VERSION ""

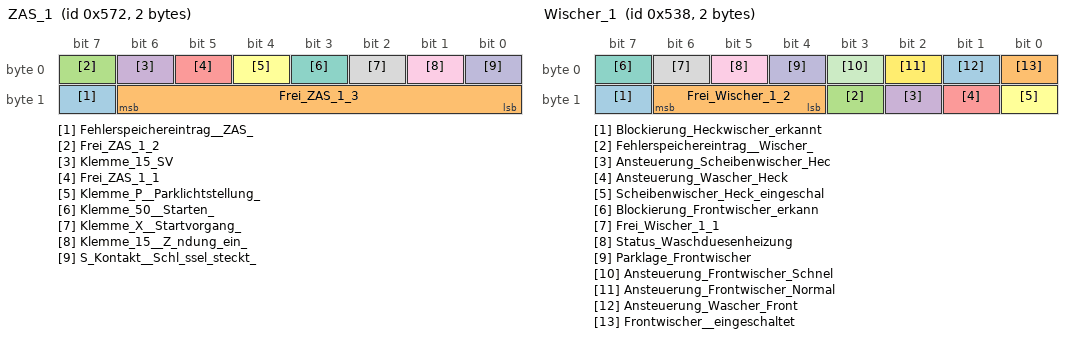
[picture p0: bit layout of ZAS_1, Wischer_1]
BO_ 1394 ZAS_1: 2 XXX
 SG_ Fehlerspeichereintrag__ZAS_ : 15|1@1+ (1,0) [0|0] "" XXX
 SG_ Frei_ZAS_1_3 : 8|7@1+ (1,0) [0|0] "" XXX
 SG_ Frei_ZAS_1_2 : 7|1@1+ (1,0) [0|0] "" XXX
 SG_ Klemme_15_SV : 6|1@1+ (1,0) [0|0] "" XXX
 SG_ Frei_ZAS_1_1 : 5|1@1+ (1,0) [0|0] "" XXX
 SG_ Klemme_P__Parklichtstellung_ : 4|1@1+ (1,0) [0|0] "" XXX
 SG_ Klemme_50__Starten_ : 3|1@1+ (1,0) [0|0] "" XXX
 SG_ Klemme_X__Startvorgang_ : 2|1@1+ (1,0) [0|0] "" XXX
 SG_ Klemme_15__Z_ndung_ein_ : 1|1@1+ (1,0) [0|0] "" XXX
 SG_ S_Kontakt__Schl_ssel_steckt_ : 0|1@1+ (1,0) [0|0] "" XXX

BO_ 1336 Wischer_1: 2 XXX
 SG_ Blockierung_Heckwischer_erkannt : 15|1@1+ (1,0) [0|0] "" XXX
 SG_ Frei_Wischer_1_2 : 12|3@1+ (1,0) [0|0] "" XXX
 SG_ Fehlerspeichereintrag__Wischer_ : 11|1@1+ (1,0) [0|0] "" XXX
 SG_ Ansteuerung_Scheibenwischer_Hec : 10|1@1+ (1,0) [0|0] "" XXX
 SG_ Ansteuerung_Wascher_Heck : 9|1@1+ (1,0) [0|0] "" XXX
 SG_ Scheibenwischer_Heck_eingeschal : 8|1@1+ (1,0) [0|0] "" XXX
 SG_ Blockierung_Frontwischer_erkann : 7|1@1+ (1,0) [0|0] "" XXX
 SG_ Frei_Wischer_1_1 : 6|1@1+ (1,0) [0|0] "" XXX
 SG_ Status_Waschduesenheizung : 5|1@1+ (1,0) [0|0] "" XXX
 SG_ Parklage_Frontwischer : 4|1@1+ (1,0) [0|0] "" XXX
 SG_ Ansteuerung_Frontwischer_Schnel : 3|1@1+ (1,0) [0|0] "" XXX
 SG_ Ansteuerung_Frontwischer_Normal : 2|1@1+ (1,0) [0|0] "" XXX
 SG_ Ansteuerung_Wascher_Front : 1|1@1+ (1,0) [0|0] "" XXX
 SG_ Frontwischer__eingeschaltet : 0|1@1+ (1,0) [0|0] "" XXX

BO_ 1464 WFS_1: 2 XXX
 SG_ WFS_Textbits : 8|8@1+ (1,0) [0|0] "" XXX
 SG_ Frei_WFS_1_1 : 1|7@1+ (1,0) [0|0] "" XXX
 SG_ WFS_LED : 0|1@1+ (1,0) [0|0] "" XXX

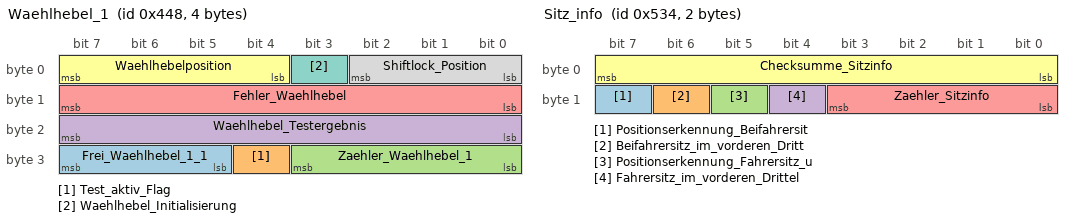
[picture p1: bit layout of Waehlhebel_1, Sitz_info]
BO_ 1096 Waehlhebel_1: 4 XXX
 SG_ Frei_Waehlhebel_1_1 : 29|3@1+ (1,0) [0|0] "" XXX
 SG_ Test_aktiv_Flag : 28|1@1+ (1,0) [0|0] "" XXX
 SG_ Zaehler_Waehlhebel_1 : 24|4@1+ (1,0) [0|15] "" XXX
 SG_ Waehlhebel_Testergebnis : 16|8@1+ (1,0) [0|255] "" XXX
 SG_ Fehler_Waehlhebel : 8|8@1+ (1,0) [0|0] "" XXX
 SG_ Waehlhebelposition : 4|4@1+ (1,0) [0|0] "" XXX
 SG_ Waehlhebel_Initialisierung : 3|1@1+ (1,0) [0|0] "" XXX
 SG_ Shiftlock_Position : 0|3@1+ (1,0) [0|0] "" XXX

BO_ 1496 Verbauliste_1: 8 XXX
 SG_ TV_Tuner : 63|1@1+ (1,0) [0|0] "" XXX
 SG_ DSP : 62|1@1+ (1,0) [0|0] "" XXX
 SG_ CD_Wechsler : 61|1@1+ (1,0) [0|0] "" XXX
 SG_ Spracheingabe : 60|1@1+ (1,0) [0|0] "" XXX
 SG_ Telematik : 59|1@1+ (1,0) [0|0] "" XXX
 SG_ Navigation : 58|1@1+ (1,0) [0|0] "" XXX
 SG_ Telefon : 57|1@1+ (1,0) [0|0] "" XXX
 SG_ Radio : 56|1@1+ (1,0) [0|0] "" XXX
 SG_ MMI_vorne : 55|1@1+ (1,0) [0|0] "" XXX
 SG_ MMI_hinten : 54|1@1+ (1,0) [0|0] "" XXX
 SG_ Frei_Verbauliste_1_11 : 53|1@1+ (1,0) [0|0] "" XXX
 SG_ Klimabedienteil_HL : 52|1@1+ (1,0) [0|0] "" XXX
 SG_ Frei_Verbauliste_1_10 : 50|2@1+ (1,0) [0|0] "" XXX
 SG_ Tankgeber : 49|1@1+ (1,0) [0|0] "" XXX
 SG_ Assistenzfahrlicht : 48|1@1+ (1,0) [0|0] "" XXX
 SG_ Memory_hinter_Fahrer : 47|1@1+ (1,0) [0|0] "" XXX
 SG_ Sitzmemory_hinten : 46|1@1+ (1,0) [0|0] "" XXX
 SG_ Sitzmemory_Beifahrer : 45|1@1+ (1,0) [0|0] "" XXX
 SG_ Anh_ngersteuergeraet : 44|1@1+ (1,0) [0|0] "" XXX
 SG_ Energiemanagement : 43|1@1+ (1,0) [0|0] "" XXX
 SG_ Wischermodul : 42|1@1+ (1,0) [0|0] "" XXX
 SG_ EZS___Kessy__Komfort_ : 41|1@1+ (1,0) [0|0] "" XXX
 SG_ Verdecksteuergeraet : 40|1@1+ (1,0) [0|0] "" XXX
 SG_ Standheizung : 39|1@1+ (1,0) [0|0] "" XXX
 SG_ Frei_Verbauliste_1_9 : 38|1@1+ (1,0) [0|0] "" XXX
 SG_ Einparkhilfe : 37|1@1+ (1,0) [0|0] "" XXX
 SG_ Klimasteuergeraet_Komfort : 36|1@1+ (1,0) [0|0] "" XXX
 SG_ Gateway : 35|1@1+ (1,0) [0|0] "" XXX
 SG_ Lenksaeulenmodul : 34|1@1+ (1,0) [0|0] "" XXX
 SG_ Reifendruck : 33|1@1+ (1,0) [0|0] "" XXX
 SG_ Kombiinstrument_Komfort : 32|1@1+ (1,0) [0|0] "" XXX
 SG_ Dachmodul : 31|1@1+ (1,0) [0|0] "" XXX
 SG_ Memory : 30|1@1+ (1,0) [0|0] "" XXX
 SG_ TSG_HR : 29|1@1+ (1,0) [0|0] "" XXX
 SG_ TSG_HL : 28|1@1+ (1,0) [0|0] "" XXX
 SG_ TSG_BT : 27|1@1+ (1,0) [0|0] "" XXX
 SG_ TSG_FT : 26|1@1+ (1,0) [0|0] "" XXX
 SG_ ZKE : 25|1@1+ (1,0) [0|0] "" XXX
 SG_ BSG_Komfort : 24|1@1+ (1,0) [0|0] "" XXX
 SG_ Frei_Verbauliste_1_8 : 19|5@1+ (1,0) [0|0] "" XXX
 SG_ Stabi_Entkopplung : 18|1@1+ (1,0) [0|0] "" XXX
 SG_ Waehlhebel : 17|1@1+ (1,0) [0|0] "" XXX
 SG_ Batteriemanager : 16|1@1+ (1,0) [0|0] "" XXX
 SG_ Daempfer_SG : 15|1@1+ (1,0) [0|0] "" XXX
 SG_ Niveauregulierung : 14|1@1+ (1,0) [0|0] "" XXX
 SG_ EZS___Kessy__Antrieb_ : 13|1@1+ (1,0) [0|0] "" XXX
 SG_ Bremsbooster : 12|1@1+ (1,0) [0|0] "" XXX
 SG_ Lenkhilfe : 11|1@1+ (1,0) [0|0] "" XXX
 SG_ Kombi_Antrieb : 10|1@1+ (1,0) [0|0] "" XXX
 SG_ Einspritzpumpe : 9|1@1+ (1,0) [0|0] "" XXX
 SG_ Lenkwinkel : 8|1@1+ (1,0) [0|0] "" XXX
 SG_ Allrad : 7|1@1+ (1,0) [0|0] "" XXX
 SG_ BSG_Antrieb : 6|1@1+ (1,0) [0|0] "" XXX
 SG_ ADR : 5|1@1+ (1,0) [0|0] "" XXX
 SG_ Airbag : 4|1@1+ (1,0) [0|0] "" XXX
 SG_ Climatronic_Antrieb : 3|1@1+ (1,0) [0|0] "" XXX
 SG_ ABS : 2|1@1+ (1,0) [0|0] "" XXX
 SG_ Getriebesteuergeraet : 1|1@1+ (1,0) [0|0] "" XXX
 SG_ Motorsteuergeraet : 0|1@1+ (1,0) [0|0] "" XXX

BO_ 1488 Systeminfo_1: 6 XXX
 SG_ CAN_Stand_4_1_Antrieb_Daten_Hau : 44|4@1+ (1,0) [0|15] "" XXX
 SG_ CAN_Stand_4_1_Antrieb_Daten_Neb : 40|4@1+ (1,0) [0|15] "" XXX
 SG_ CAN_Stand_4_1_Komfort_Daten_Hau : 36|4@1+ (1,0) [0|15] "" XXX
 SG_ CAN_Stand_4_1_Komfort_Daten_Neb : 32|4@1+ (1,0) [0|15] "" XXX
 SG_ Frei_Systeminfo_1_6 : 30|1@1+ (1,0) [0|0] "" XXX
 SG_ Viertuerer : 29|1@1+ (1,0) [0|0] "" XXX
 SG_ Rechtslenker : 28|1@1+ (1,0) [0|0] "" XXX
 SG_ Fahrzeug_Index : 24|4@1+ (1,0) [0|0] "" XXX
 SG_ Fahrzeug_Generation : 20|4@1+ (1,0) [0|15] "" XXX
 SG_ Fahrzeug_Derivat : 16|4@1+ (1,0) [0|15] "" XXX
 SG_ Fahrzeug_Marke_2 : 12|4@1+ (1,0) [0|15] "" XXX
 SG_ Fahrzeug_Klasse : 8|4@1+ (1,0) [0|15] "" XXX
 SG_ Verbauinformation_gueltig : 7|1@1+ (1,0) [0|0] "" XXX
 SG_ CAN_Infotainment_verbaut : 6|1@1+ (1,0) [0|0] "" XXX
 SG_ CAN_Infotainment_in_Diagnose : 5|1@1+ (1,0) [0|0] "" XXX
 SG_ Sleep_CAN_Infotainment : 4|1@1+ (1,0) [0|0] "" XXX
 SG_ CAN_Komfort_in_Diagnose : 3|1@1+ (1,0) [0|0] "" XXX
 SG_ Sleep_CAN_Komfort : 2|1@1+ (1,0) [0|0] "" XXX
 SG_ CAN_Antrieb_in_Diagnose : 1|1@1+ (1,0) [0|0] "" XXX
 SG_ CAN_Extern_zugeschaltet : 0|1@1+ (1,0) [0|0] "" XXX

BO_ 268 Slave_1: 8 XXX
 SG_ Delta_reduziertes_Sollmoment : 48|1@1+ (1,0) [0|0] "" XXX
 SG_ Delta_Drosselklappenwinkel : 32|16@1+ (1,0) [0|0] "" XXX
 SG_ Frei_Slave_1_1 : 25|7@1+ (1,0) [0|0] "" XXX
 SG_ Delta_Zuendwinkelausgabe : 24|1@1+ (1,0) [0|0] "" XXX
 SG_ Ubat_Freigabe_DVE__Slave_ : 23|1@1+ (1,0) [0|0] "" XXX
 SG_ Drosselklappe_Sollwertbegrenzun : 22|1@1+ (1,0) [0|0] "" XXX
 SG_ Einspritzverbot_lernen__Slave_ : 21|1@1+ (1,0) [0|0] "" XXX
 SG_ Master_erkannt__Slave_ : 20|1@1+ (1,0) [0|0] "" XXX
 SG_ Fehler_Momentenausgabe : 19|1@1+ (1,0) [0|0] "" XXX
 SG_ Fehler_Getriebe_Moment : 18|1@1+ (1,0) [0|0] "" XXX
 SG_ Fehler_Bremsenbotschaft : 17|1@1+ (1,0) [0|0] "" XXX
 SG_ Indiziertes_Istmoment__Slave_ : 0|16@1+ (0.0015259,0) [0|99.998] "%" XXX
 SG_ Timeout_Bremsenbotschaft : 0|1@1+ (1,0) [0|0] "" XXX

BO_ 1332 Sitz_info: 2 XXX
 SG_ Positionserkennung_Beifahrersit : 15|1@1+ (1,0) [0|0] "" XXX
 SG_ Beifahrersitz_im_vorderen_Dritt : 14|1@1+ (1,0) [0|0] "" XXX
 SG_ Positionserkennung_Fahrersitz_u : 13|1@1+ (1,0) [0|0] "" XXX
 SG_ Fahrersitz_im_vorderen_Drittel : 12|1@1+ (1,0) [0|0] "" XXX
 SG_ Zaehler_Sitzinfo : 8|4@1+ (1,0) [0|15] "" XXX
 SG_ Checksumme_Sitzinfo : 0|8@1+ (1,0) [0|0] "" XXX

BO_ 1810 PSG_3: 2 XXX
 SG_ Selbsttestergebnis : 0|16@1+ (1,0) [0|0] "" XXX

BO_ 1298 PSG_2: 8 XXX
 SG_ RAM_Inhalt_4 : 48|16@1+ (1,0) [0|0] "" XXX
 SG_ RAM_Inhalt_3 : 32|16@1+ (1,0) [0|0] "" XXX
 SG_ RAM_Inhalt_2 : 16|16@1+ (1,0) [0|0] "" XXX
 SG_ RAM_Inhalt_1 : 0|16@1+ (1,0) [0|0] "" XXX

BO_ 274 PSG_1: 8 XXX
 SG_ Pumpentemperatur__2_1_ : 48|16@1+ (0.0625,0) [0|4096] "K" XXX
 SG_ Pumpentemperatur__3_2_2_ : 44|12@1+ (1,0) [0|0] "" XXX
 SG_ Zylinderzaehler__3_2_2_ : 43|3@1+ (1,0) [1|8] "Zaehler" XXX
 SG_ Ansteuerdauer__3_2_2_ : 32|11@1+ (0.0469,0) [0|96] "NW" XXX
 SG_ Nockenwellendrehzahl__3_2_2_ : 20|12@1+ (4,0) [0|16380] "upm" XXX
 SG_ Pumpen_Statuswort__3_2_2_ : 0|20@1+ (1,0) [0|0] "" XXX

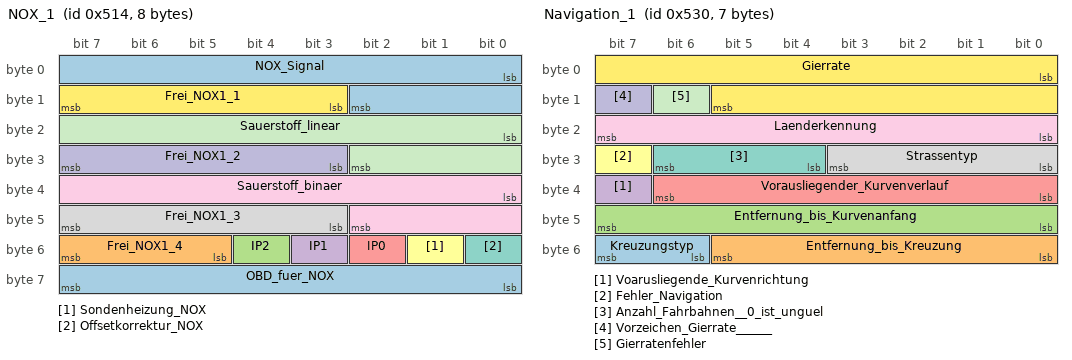
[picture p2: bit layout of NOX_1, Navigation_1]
BO_ 1300 NOX_1: 8 XXX
 SG_ OBD_fuer_NOX : 56|8@1+ (1,0) [0|0] "" XXX
 SG_ Frei_NOX1_4 : 53|3@1+ (1,0) [0|0] "" XXX
 SG_ IP2 : 52|1@1+ (1,0) [0|0] "" XXX
 SG_ IP1 : 51|1@1+ (1,0) [0|0] "" XXX
 SG_ IP0 : 50|1@1+ (1,0) [0|0] "" XXX
 SG_ Sondenheizung_NOX : 49|1@1+ (1,0) [0|0] "" XXX
 SG_ Offsetkorrektur_NOX : 48|1@1+ (1,0) [0|0] "" XXX
 SG_ Frei_NOX1_3 : 43|5@1+ (1,0) [0|0] "" XXX
 SG_ Sauerstoff_binaer : 32|11@1+ (1,-200) [-200|1847] "mV" XXX
 SG_ Frei_NOX1_2 : 27|5@1+ (1,0) [0|0] "" XXX
 SG_ Sauerstoff_linear : 16|11@1+ (1,0) [0|2047] "1000/Lambd" XXX
 SG_ Frei_NOX1_1 : 11|5@1+ (1,0) [0|0] "" XXX
 SG_ NOX_Signal : 0|11@1+ (1,0) [0|2047] "ppm" XXX

BO_ 1424 Niveau_1: 6 XXX
 SG_ Beladungszustand : 40|8@1+ (1,0) [0|253] "Zuladung" XXX
 SG_ Fehlerspeichereintrag__Niveau_1 : 39|1@1+ (1,0) [0|0] "" XXX
 SG_ Systemstatus__Niveau_1_ : 38|1@1+ (1,0) [0|0] "" XXX
 SG_ Reserve_Fahrzeugart : 37|1@1+ (1,0) [0|0] "" XXX
 SG_ Fahrzeugart_Niveau : 36|1@1+ (1,0) [0|0] "" XXX
 SG_ Textbits__Niveau_1_ : 32|4@1+ (1,0) [0|0] "" XXX
 SG_ Verstellung_HL : 31|1@1+ (1,0) [0|0] "" XXX
 SG_ Verstellung_HR : 30|1@1+ (1,0) [0|0] "" XXX
 SG_ Verstellung_VL : 29|1@1+ (1,0) [0|0] "" XXX
 SG_ Verstellung_VR : 28|1@1+ (1,0) [0|0] "" XXX
 SG_ Absenkung_Fahrzeug : 27|1@1+ (1,0) [0|0] "" XXX
 SG_ Anhebung_Fahrzeug : 26|1@1+ (1,0) [0|0] "" XXX
 SG_ Verstellung_aktiv : 25|1@1+ (1,0) [0|0] "" XXX
 SG_ Kompressorlauf_in_Kuerze : 24|1@1+ (1,0) [0|0] "" XXX
 SG_ Frei_Niveau_1_5 : 23|1@1+ (1,0) [0|0] "" XXX
 SG_ Taster_Niveau : 22|1@1+ (1,0) [0|0] "" XXX
 SG_ Parkniveau : 21|1@1+ (1,0) [0|0] "" XXX
 SG_ Zwischenniveau : 20|1@1+ (1,0) [0|0] "" XXX
 SG_ Niveaustati : 16|4@1+ (1,0) [0|0] "" XXX
 SG_ MSG_Einschraenkung : 15|1@1+ (1,0) [0|0] "" XXX
 SG_ ESP_Beeinflussung : 14|1@1+ (1,0) [0|0] "" XXX
 SG_ Warnlampe_Niveau_1 : 13|1@1+ (1,0) [0|0] "" XXX
 SG_ Frei_Niveau_1_1 : 12|1@1+ (1,0) [0|0] "" XXX
 SG_ Zaehler_Niveau_1 : 8|4@1+ (1,0) [0|15] "Zaehler" XXX
 SG_ Checksumme_Niveau_1 : 0|8@1+ (1,0) [0|0] "" XXX

BO_ 1328 Navigation_1: 7 XXX
 SG_ Kreuzungstyp : 54|2@1+ (1,0) [0|3] "" XXX
 SG_ Entfernung_bis_Kreuzung : 48|6@1+ (5,0) [0|315] "m" XXX
 SG_ Entfernung_bis_Kurvenanfang : 40|8@1+ (1,0) [0|255] "m" XXX
 SG_ Voarusliegende_Kurvenrichtung : 39|1@1+ (1,0) [0|0] "" XXX
 SG_ Vorausliegender_Kurvenverlauf : 32|7@1+ (50,0) [0|6350] "m" XXX
 SG_ Fehler_Navigation : 31|1@1+ (1,0) [0|0] "" XXX
 SG_ Anzahl_Fahrbahnen__0_ist_unguel : 28|3@1+ (1,0) [1|7] "" XXX
 SG_ Strassentyp : 24|4@1+ (1,0) [0|15] "" XXX
 SG_ Laenderkennung : 16|8@1+ (1,0) [0|0] "" XXX
 SG_ Vorzeichen_Gierrate______ : 15|1@1+ (1,0) [0|0] "" XXX
 SG_ Gierratenfehler : 14|1@1+ (1,0) [0|0] "" XXX
 SG_ Gierrate : 0|14@1+ (0.01,0) [0|100] "deg/sek" XXX

BO_ 1792 MSG_3: 3 XXX
 SG_ MSG_Konfiguration : 16|8@1+ (1,0) [0|0] "" XXX
 SG_ Lage_des_OT_Impuls : 0|16@1+ (0.01172,-384) [-384|384] "KW" XXX

BO_ 1280 MSG_2: 8 XXX
 SG_ RAM_Adresse_4 : 48|16@1+ (1,0) [0|0] "" XXX
 SG_ RAM_Adresse_3 : 32|16@1+ (1,0) [0|0] "" XXX
 SG_ RAM_Adresse_2 : 16|16@1+ (1,0) [0|0] "" XXX
 SG_ Ram_Adresse_1 : 0|16@1+ (1,0) [0|0] "" XXX

BO_ 256 MSG_1: 8 XXX
 SG_ Kurbelwellendrehzahl__3_2_2_ : 56|8@1+ (1,0) [0|0] "" XXX
 SG_ Soll_Foerderbeginn_KW__3_2_2_ : 40|16@1+ (0.01172,-384) [-384|384] "KW" XXX
 SG_ Soll_Foerderbeginn_NW__3_2_2_ : 28|12@1+ (0.01172,0) [0|768] "degNW" XXX
 SG_ Soll_Voreinspritzung : 16|12@1+ (1,0) [0|0] "" XXX
 SG_ Soll_Einspritzmenge : 0|16@1+ (0.03125,0) [0|2047] "mg/H" XXX

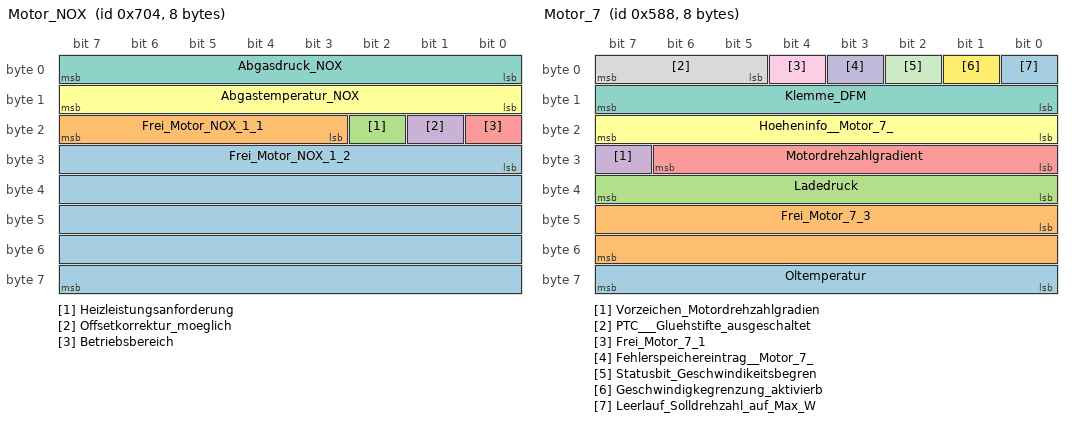
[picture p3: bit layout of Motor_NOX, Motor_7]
BO_ 1796 Motor_NOX: 8 XXX
 SG_ Frei_Motor_NOX_1_2 : 24|40@1+ (1,0) [0|0] "" XXX
 SG_ Frei_Motor_NOX_1_1 : 19|5@1+ (1,0) [0|0] "" XXX
 SG_ Heizleistungsanforderung : 18|1@1+ (1,0) [0|0] "" XXX
 SG_ Offsetkorrektur_moeglich : 17|1@1+ (1,0) [0|0] "" XXX
 SG_ Betriebsbereich : 16|1@1+ (1,0) [0|0] "" XXX
 SG_ Abgastemperatur_NOX : 8|8@1+ (5,-40) [-40|1230] "C" XXX
 SG_ Abgasdruck_NOX : 0|8@1+ (5,600) [600|1870] "mbar" XXX

BO_ 900 Motor_Momente: 8 XXX
 SG_ Momentenangaben_ungenau__Moment : 35|2@1+ (1,0) [0|0] "" XXX

BO_ 1408 Motor_Flexia: 8 XXX
 SG_ Ansaugsystem m0 : 63|1@1+ (1,0) [0|0] "" XXX
 SG_ Hubraum m0 : 56|7@1+ (0.1,0) [0|12.7] "l" XXX
 SG_ Steigung_der_Befuellungskennlin m1 : 56|8@1+ (0.001,0) [0|0.255] "l/mm" XXX
 SG_ Anzahl_Zylinder m0 : 52|4@1+ (1,0) [0|15] "Vent./Zyl." XXX
 SG_ Bewertungsfaktor_Russindex_Turb m1 : 50|6@1+ (0.1,0) [0|6.3] "" XXX
 SG_ Anzahl_Ventile m0 : 49|3@1+ (1,0) [0|7] "Vent./Zyl." XXX
 SG_ Bewertungsfaktor_Verschleissind m1 : 44|6@1+ (0.1,0) [0|6.3] "" XXX
 SG_ Hersteller_Code m1 : 40|4@1+ (1,0) [0|15] "" XXX
 SG_ Motorleistung m0 : 40|9@1+ (1,0) [0|512] "KW" XXX
 SG_ Max_Drehmoment m0 : 32|8@1+ (10,0) [0|2550] "Nm" XXX
 SG_ Normierter_Verbrauch m1 : 32|8@1+ (10,0) [0|2550] "l/Zyl." XXX
 SG_ Oelniveauschwelle m1 : 24|8@1+ (0.25,0) [0|63.75] "cm" XXX
 SG_ Drehzahl_MaxNorm m0 : 24|8@1+ (100,0) [0|25500] "U/min" XXX
 SG_ Verschleissindex : 16|8@1+ (1,0) [0|254] "" XXX
 SG_ Russindex : 8|8@1+ (1,0) [0|254] "" XXX
 SG_ Verbrennungsart : 7|1@1+ (1,0) [0|0] "" XXX
 SG_ Frei_Motor_Flexia_1 : 6|1@1+ (1,0) [0|0] "" XXX
 SG_ Warm_Up_Cycle : 5|1@1+ (1,0) [0|0] "" XXX
 SG_ Driving_Cycle : 4|1@1+ (1,0) [0|0] "" XXX
 SG_ Zaehler_Motor_Flexia : 1|3@1+ (1,0) [0|15] "" XXX
 SG_ Multiplex_Schalter_Motor_Flexia M : 0|1@1+ (1,0) [0|0] "" XXX

BO_ 1416 Motor_7: 8 XXX
 SG_ Oltemperatur : 56|8@1+ (1,0) [0|0] "" XXX
 SG_ Frei_Motor_7_3 : 40|16@1+ (1,0) [0|0] "" XXX
 SG_ Ladedruck : 32|8@1+ (0.01,0) [0|2.54] "bar" XXX
 SG_ Vorzeichen_Motordrehzahlgradien : 31|1@1+ (1,0) [0|0] "" XXX
 SG_ Motordrehzahlgradient : 24|7@1+ (1,0) [0|126] "U/min" XXX
 SG_ Hoeheninfo__Motor_7_ : 16|8@1+ (0.00787,0) [0|2] "" XXX
 SG_ Klemme_DFM : 8|8@1+ (0.4,0) [0|101.6] "%" XXX
 SG_ PTC___Gluehstifte_ausgeschaltet : 5|3@1+ (1,0) [0|0] "" XXX
 SG_ Frei_Motor_7_1 : 4|1@1+ (1,0) [0|0] "" XXX
 SG_ Fehlerspeichereintrag__Motor_7_ : 3|1@1+ (1,0) [0|0] "" XXX
 SG_ Statusbit_Geschwindikeitsbegren : 2|1@1+ (1,0) [0|0] "" XXX
 SG_ Geschwindigkegrenzung_aktivierb : 1|1@1+ (1,0) [0|0] "" XXX
 SG_ Leerlauf_Solldrehzahl_auf_Max_W : 0|1@1+ (1,0) [0|0] "" XXX

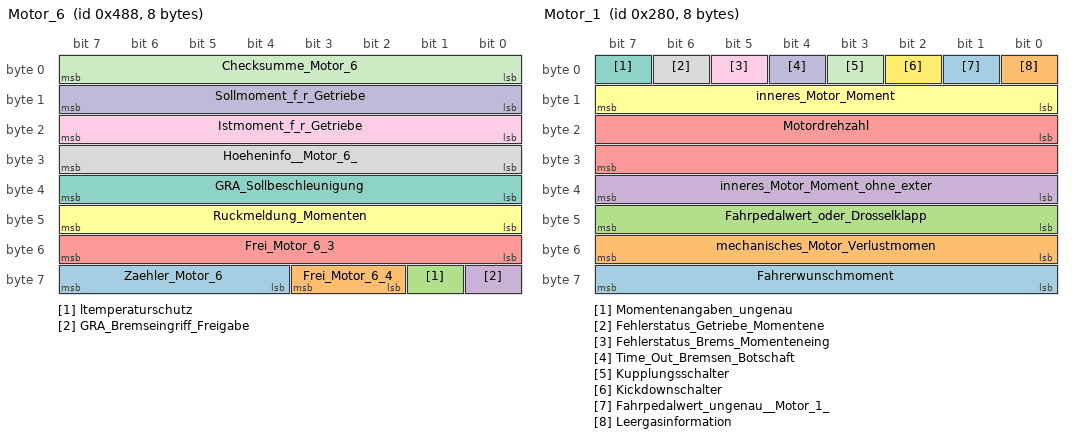
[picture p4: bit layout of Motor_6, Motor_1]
BO_ 1160 Motor_6: 8 XXX
 SG_ Zaehler_Motor_6 : 60|4@1+ (1,0) [0|15] "" XXX
 SG_ Frei_Motor_6_4 : 58|2@1+ (1,0) [0|0] "" XXX
 SG_ ltemperaturschutz : 57|1@1+ (1,0) [0|0] "" XXX
 SG_ GRA_Bremseingriff_Freigabe : 56|1@1+ (1,0) [0|0] "" XXX
 SG_ Frei_Motor_6_3 : 48|8@1+ (1,0) [0|0] "" XXX
 SG_ Ruckmeldung_Momenten : 40|8@1+ (0.39,0) [0|100] "" XXX
 SG_ GRA_Sollbeschleunigung : 32|8@1+ (0.024,-3.984) [-3.984|2.112] "m/s2" XXX
 SG_ Hoeheninfo__Motor_6_ : 24|8@1+ (0.00787,0) [0|2] "" XXX
 SG_ Istmoment_f_r_Getriebe : 16|8@1+ (0.39,0) [0|99] "MDI" XXX
 SG_ Sollmoment_f_r_Getriebe : 8|8@1+ (0.39,0) [0|99] "MDI" XXX
 SG_ Checksumme_Motor_6 : 0|8@1+ (1,0) [0|0] "" XXX

BO_ 1152 Motor_5: 8 XXX
 SG_ CHECKSUM : 56|8@1+ (1,0) [0|0] "" XXX
 SG_ Motortext_Bits__4_1_ : 52|4@1+ (1,0) [0|0] "" XXX
 SG_ Doppelte_Momente : 51|1@1+ (1,0) [0|0] "" XXX
 SG_ GRA_Hauptschalter : 50|1@1+ (1,0) [0|0] "" XXX
 SG_ Anlasser_Ausspuren : 49|1@1+ (1,0) [0|0] "" XXX
 SG_ Anlasser_Freigabe : 48|1@1+ (1,0) [0|0] "" XXX
 SG_ Klimadrucksignal__Motor_5_ : 40|8@1+ (0.2,0) [0|50.8] "bar" XXX
 SG_ K_hlerluefteransteuerung : 32|8@1+ (0.4,0) [0|101.6] "%" XXX
 SG_ Verbrauch_Ueberlauf : 31|1@1+ (1,0) [0|0] "" XXX
 SG_ Kraftstoffverbrauchssignal : 16|15@1+ (1,0) [0|32767] "ul" XXX
 SG_ Klimakompressor_Leistungsreduzi : 15|1@1+ (1,0) [0|0] "" XXX
 SG_ Kennfeldkuehlung : 14|1@1+ (1,0) [0|0] "" XXX
 SG_ Klimakompressor_aus__Motor_5_ : 13|1@1+ (1,0) [0|0] "" XXX
 SG_ CAT_Warnung : 12|1@1+ (1,0) [0|0] "" XXX
 SG_ OBD_2_Lampe : 11|1@1+ (1,0) [0|0] "" XXX
 SG_ E_Gas_Lampe : 10|1@1+ (1,0) [0|0] "" XXX
 SG_ Vorgluehlampe__Motor_5_ : 9|1@1+ (1,0) [0|0] "" XXX
 SG_ Ladekontroll_Lampe : 8|1@1+ (1,0) [0|0] "" XXX
 SG_ Multiplex_Code M : 6|2@1+ (1,0) [0|0] "" XXX
 SG_ Multiplex_Info_norm__Verbrauch m3 : 0|6@1+ (20,0) [0|1260] "l/Zyl" XXX
 SG_ Multiplex_Info_Motortyp m2 : 0|6@1+ (1,0) [0|0] "" XXX
 SG_ Multiplex_Info_Drehzahl_MD_Max m1 : 0|6@1+ (100,0) [0|6300] "U/min" XXX
 SG_ Multiplex_Info_Max_Drehmoment m0 : 0|6@1+ (10,0) [0|630] "Nm" XXX

BO_ 896 Motor_3: 8 XXX
 SG_ Drosselklappenpoti : 56|8@1+ (0.4,0) [0|101.6] "%" XXX
 SG_ Motor_Wunschdrehzahl : 48|8@1+ (25,0) [0|6350] "U/min" XXX
 SG_ Motordrehzahlbeeinflussung : 40|8@1+ (0.392,0) [0|100] "%" XXX
 SG_ Kein_Start_Stop : 39|1@1+ (1,0) [0|0] "" XXX
 SG_ Kein_E_Gas : 38|1@1+ (1,0) [0|0] "" XXX
 SG_ Reserviert_Motor_3_1 : 37|1@1+ (1,0) [0|0] "" XXX
 SG_ Vorzeichen_Rad_Wunschmoment : 36|1@1+ (1,0) [0|0] "" XXX
 SG_ Rad_Wunschmoment : 24|12@1+ (0.39,0) [0|1597] "MDI" XXX
 SG_ Fahrpedal_Rohsignal : 16|8@1+ (0.4,0) [0|101.6] "%" XXX
 SG_ Ansauglufttemperatur : 8|8@1+ (0.75,-48) [-48|142.5] "" XXX
 SG_ Fehlerstatus_Ansauglufttemperat : 7|1@1+ (1,0) [0|0] "" XXX
 SG_ Motorsteuerger_t_gesperrt : 6|1@1+ (1,0) [0|0] "" XXX
 SG_ Drosselklappenwinkel_ungenau : 5|1@1+ (1,0) [0|0] "" XXX
 SG_ Fahrpedalwert_ungenau__Motor_3_ : 4|1@1+ (1,0) [0|0] "" XXX
 SG_ Frei_Motor_3_1 : 3|1@1+ (1,0) [0|0] "" XXX
 SG_ Motor_Wunschdrehzahl_Priorit_t : 2|1@1+ (1,0) [0|0] "" XXX
 SG_ Uebertemperaturschutz__Motor_3_ : 1|1@1+ (1,0) [0|0] "" XXX
 SG_ Vorgluehmeldung : 0|1@1+ (1,0) [0|0] "" XXX

BO_ 648 Motor_2: 8 XXX
 SG_ Minimales_Motormoment_bei_Zuend : 56|8@1+ (0.39,0) [0|99] "MDI" XXX
 SG_ Begrenzungsmoment : 48|8@1+ (0.39,0) [0|99] "MDI" XXX
 SG_ Leerlaufsolldrehzahl__Motor_2_ : 40|8@1+ (10,0) [0|2540] "U/min" XXX
 SG_ Soll_Geschwindigkeit_bei_GRA_Be : 32|8@1+ (1.28,0) [0|325] "km/h" XXX
 SG_ Fahrzeuggeschwindigkeit : 24|8@1+ (1.28,0) [0|325] "km/h" XXX
 SG_ GRA_Status : 22|2@1+ (1,0) [0|0] "" XXX
 SG_ OBD_2_freeze_frame : 21|1@1+ (1,0) [0|0] "" XXX
 SG_ Status_Normalbetrieb : 20|1@1+ (1,0) [0|0] "" XXX
 SG_ Ansteuerung_Klima__4_1_ : 19|1@1+ (1,0) [0|0] "" XXX
 SG_ Fehlerstatus_Kuhlmitteltempera : 18|1@1+ (1,0) [0|0] "" XXX
 SG_ Bremstestschalter : 17|1@1+ (1,0) [0|0] "" XXX
 SG_ Bremslichtschalter : 16|1@1+ (1,0) [0|0] "" XXX
 SG_ Kuehlmitteltemperatur__Motor_2_ : 8|8@1+ (0.75,-48) [-48|142.5] "" XXX
 SG_ Multiplex_Code_Motor_2 M : 6|2@1+ (1,0) [0|0] "" XXX
 SG_ Multiplex_Info_Motorcode__4_x_ m1 : 0|6@1+ (1,0) [0|0] "" XXX
 SG_ Multiplex_Info_Getriebecode m2 : 0|6@1+ (1,0) [0|0] "" XXX
 SG_ Multiplex_Info_Max_Moment__Norm m3 : 0|6@1+ (10,0) [0|630] "Nm" XXX
 SG_ Multiplex_Info_CAN_Stand m0 : 0|6@1+ (1,0) [0|0] "" XXX

BO_ 640 Motor_1: 8 XXX
 SG_ Fahrerwunschmoment : 56|8@1+ (0.39,0) [0|99] "MDI" XXX
 SG_ mechanisches_Motor_Verlustmomen : 48|8@1+ (0.39,0) [0|99] "MDI" XXX
 SG_ Fahrpedalwert_oder_Drosselklapp : 40|8@1+ (0.4,0) [0|101.6] "%" XXX
 SG_ inneres_Motor_Moment_ohne_exter : 32|8@1+ (0.39,0) [0|99] "MDI" XXX
 SG_ Motordrehzahl : 16|16@1+ (0.25,0) [0|16256] "U/min" XXX
 SG_ inneres_Motor_Moment : 8|8@1+ (0.39,0) [0|99] "MDI" XXX
 SG_ Momentenangaben_ungenau : 7|1@1+ (1,0) [0|0] "" XXX
 SG_ Fehlerstatus_Getriebe_Momentene : 6|1@1+ (1,0) [0|0] "" XXX
 SG_ Fehlerstatus_Brems_Momenteneing : 5|1@1+ (1,0) [0|0] "" XXX
 SG_ Time_Out_Bremsen_Botschaft : 4|1@1+ (1,0) [0|0] "" XXX
 SG_ Kupplungsschalter : 3|1@1+ (1,0) [0|0] "" XXX
 SG_ Kickdownschalter : 2|1@1+ (1,0) [0|0] "" XXX
 SG_ Fahrpedalwert_ungenau__Motor_1_ M : 1|1@1+ (1,0) [0|0] "" XXX
 SG_ Leergasinformation : 0|1@1+ (1,0) [0|0] "" XXX

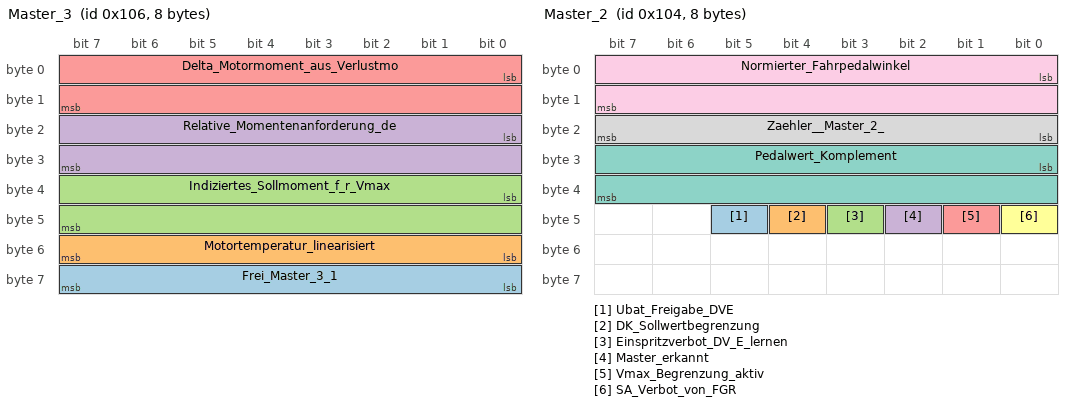
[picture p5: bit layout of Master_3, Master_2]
BO_ 262 Master_3: 8 XXX
 SG_ Frei_Master_3_1 : 56|8@1+ (1,0) [0|0] "" XXX
 SG_ Motortemperatur_linearisiert : 48|8@1+ (0.75,-48) [-48|143.25] "" XXX
 SG_ Indiziertes_Sollmoment_f_r_Vmax : 32|16@1+ (0.0015259,0) [0|100] "%" XXX
 SG_ Relative_Momentenanforderung_de : 16|16@1+ (0.003052,0) [0|200] "%" XXX
 SG_ Delta_Motormoment_aus_Verlustmo : 0|16@1+ (0.003052,-100) [-100|100] "%" XXX

BO_ 260 Master_2: 8 XXX
 SG_ Ubat_Freigabe_DVE : 45|1@1+ (1,0) [0|0] "" XXX
 SG_ DK_Sollwertbegrenzung : 44|1@1+ (1,0) [0|0] "" XXX
 SG_ Einspritzverbot_DV_E_lernen : 43|1@1+ (1,0) [0|0] "" XXX
 SG_ Master_erkannt : 42|1@1+ (1,0) [0|0] "" XXX
 SG_ Vmax_Begrenzung_aktiv : 41|1@1+ (1,0) [0|0] "" XXX
 SG_ SA_Verbot_von_FGR : 40|1@1+ (1,0) [0|0] "" XXX
 SG_ Pedalwert_Komplement : 24|16@1+ (1,0) [0|0] "" XXX
 SG_ Zaehler__Master_2_ : 16|8@1+ (1,0) [0|255] "" XXX
 SG_ Normierter_Fahrpedalwinkel : 0|16@1+ (0.001526,0) [0|100] "%" XXX

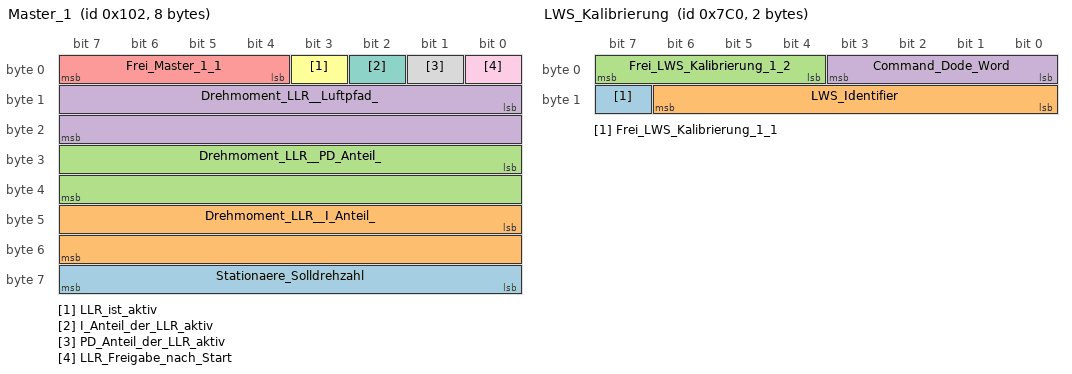
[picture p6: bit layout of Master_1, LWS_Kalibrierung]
BO_ 258 Master_1: 8 XXX
 SG_ Stationaere_Solldrehzahl : 56|8@1+ (10,0) [0|2550] "Umin" XXX
 SG_ Drehmoment_LLR__I_Anteil_ : 40|16@1+ (0.003052,-100) [-100|100] "%" XXX
 SG_ Drehmoment_LLR__PD_Anteil_ : 24|16@1+ (0.003052,-100) [-100|100] "%" XXX
 SG_ Drehmoment_LLR__Luftpfad_ : 8|16@1+ (0.003052,-100) [-100|100] "%" XXX
 SG_ Frei_Master_1_1 : 4|4@1+ (1,0) [0|0] "" XXX
 SG_ LLR_ist_aktiv : 3|1@1+ (1,0) [0|0] "" XXX
 SG_ I_Anteil_der_LLR_aktiv : 2|1@1+ (1,0) [0|0] "" XXX
 SG_ PD_Anteil_der_LLR_aktiv : 1|1@1+ (1,0) [0|0] "" XXX
 SG_ LLR_Freigabe_nach_Start : 0|1@1+ (1,0) [0|0] "" XXX

BO_ 1984 LWS_Kalibrierung: 2 XXX
 SG_ Frei_LWS_Kalibrierung_1_1 : 15|1@1+ (1,0) [0|0] "" XXX
 SG_ LWS_Identifier : 8|7@1+ (1,0) [0|0] "" XXX
 SG_ Frei_LWS_Kalibrierung_1_2 : 4|4@1+ (1,0) [0|0] "" XXX
 SG_ Command_Dode_Word : 0|4@1+ (1,0) [0|0] "" XXX

BO_ 1986 Lenkwinkel_Init: 4 XXX
 SG_ Kodierbytes : 8|24@1+ (1,0) [0|0] "" XXX
 SG_ Identiifier_f_r_LWS_Init : 0|8@1+ (1,0) [0|0] "" XXX

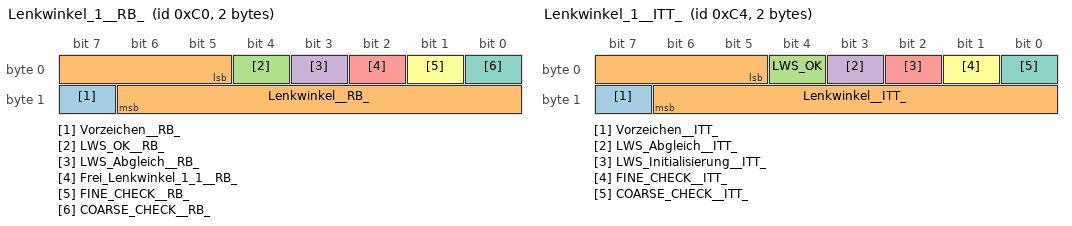
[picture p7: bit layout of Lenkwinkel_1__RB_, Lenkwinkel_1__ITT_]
BO_ 192 Lenkwinkel_1__RB_: 2 XXX
 SG_ Vorzeichen__RB_ : 15|1@1+ (1,0) [0|0] "" XXX
 SG_ Lenkwinkel__RB_ : 5|10@1+ (2.5,-720) [-720|720] "" XXX
 SG_ LWS_OK__RB_ : 4|1@1+ (1,0) [0|0] "" XXX
 SG_ LWS_Abgleich__RB_ : 3|1@1+ (1,0) [0|0] "" XXX
 SG_ Frei_Lenkwinkel_1_1__RB_ : 2|1@1+ (1,0) [0|0] "" XXX
 SG_ FINE_CHECK__RB_ : 1|1@1+ (1,0) [0|0] "" XXX
 SG_ COARSE_CHECK__RB_ : 0|1@1+ (1,0) [0|0] "" XXX

BO_ 196 Lenkwinkel_1__ITT_: 2 XXX
 SG_ Vorzeichen__ITT_ : 15|1@1+ (1,0) [0|0] "" XXX
 SG_ Lenkwinkel__ITT_ : 5|10@1+ (1.5,-768) [-768|766.5] "" XXX
 SG_ LWS_OK : 4|1@1+ (1,0) [0|0] "" XXX
 SG_ LWS_Abgleich__ITT_ : 3|1@1+ (1,0) [0|0] "" XXX
 SG_ LWS_Initialisierung__ITT_ : 2|1@1+ (1,0) [0|0] "" XXX
 SG_ FINE_CHECK__ITT_ : 1|1@1+ (1,0) [0|0] "" XXX
 SG_ COARSE_CHECK__ITT_ : 0|1@1+ (1,0) [0|0] "" XXX

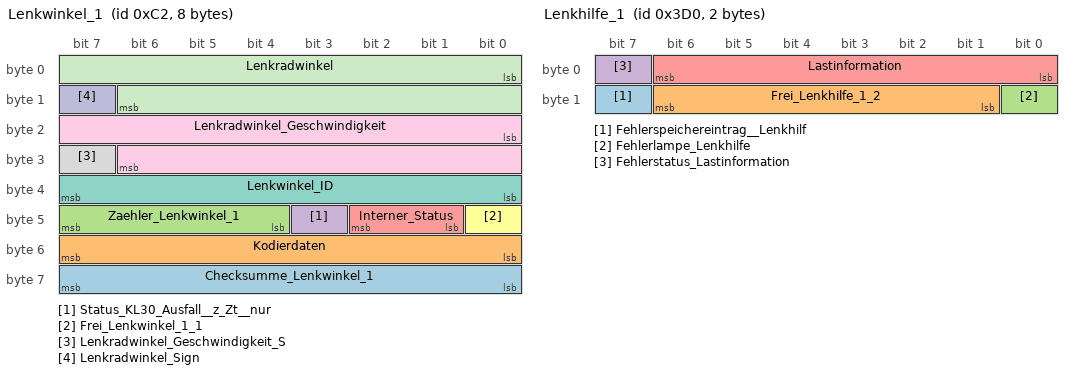
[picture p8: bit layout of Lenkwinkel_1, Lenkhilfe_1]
BO_ 194 Lenkwinkel_1: 8 XXX
 SG_ Checksumme_Lenkwinkel_1 : 56|8@1+ (1,0) [0|0] "" XXX
 SG_ Kodierdaten : 48|8@1+ (1,0) [0|0] "" XXX
 SG_ Zaehler_Lenkwinkel_1 : 44|4@1+ (1,0) [0|15] "" XXX
 SG_ Status_KL30_Ausfall__z_Zt__nur : 43|1@1+ (1,0) [0|0] "" XXX
 SG_ Interner_Status : 41|2@1+ (1,0) [0|0] "" XXX
 SG_ Frei_Lenkwinkel_1_1 : 40|1@1+ (1,0) [0|0] "" XXX
 SG_ Lenkwinkel_ID : 32|8@1+ (1,0) [0|0] "" XXX
 SG_ Lenkradwinkel_Geschwindigkeit_S : 31|1@1+ (1,0) [0|0] "" XXX
 SG_ Lenkradwinkel_Geschwindigkeit : 16|15@1+ (0.04375,0) [0|1433.6] "Grad/Sek" XXX
 SG_ Lenkradwinkel_Sign : 15|1@1+ (1,0) [0|0] "" XXX
 SG_ Lenkradwinkel : 0|15@1+ (0.04375,0) [0|1433.6] "Grad" XXX

BO_ 1502 Lenkhilfe_Fehler: 7 XXX
 SG_ Werkstattcode : 48|8@1+ (1,0) [0|0] "" XXX
 SG_ Multiplex_Signal : 45|3@1+ (1,0) [0|7] "" XXX
 SG_ Sensorcodierung_Lenkhilfe : 44|1@1+ (1,0) [0|0] "" XXX
 SG_ Kennliniencodierung_Lenkhilfe : 40|4@1+ (1,0) [0|15] "Kennlinie" XXX
 SG_ Geber_f__Lenkw__Speicher_ausles : 39|1@1+ (1,0) [0|0] "" XXX
 SG_ Kombiinstr__Speicher_auslesen : 38|1@1+ (1,0) [0|0] "" XXX
 SG_ Steuerger__Speicher_auslesen : 37|1@1+ (1,0) [0|0] "" XXX
 SG_ Lenkhilfe_Steuergeraet_defekt : 36|1@1+ (1,0) [0|0] "" XXX
 SG_ Frei_Lenkhilfe_1_3 : 32|4@1+ (1,0) [0|0] "" XXX
 SG_ Frei_Lenkhilfe_1_4 : 30|2@1+ (1,0) [0|0] "" XXX
 SG_ Geber_f__Lenkwi__k__CAN_Komm_sp : 29|1@1+ (1,0) [0|0] "" XXX
 SG_ Geber_f__Lenkwinkel_k__CAN_Komm : 28|1@1+ (1,0) [0|0] "" XXX
 SG_ Kombiinstr__k__CAN_Kommunik__sp : 27|1@1+ (1,0) [0|0] "" XXX
 SG_ Kombiinstrument_k__CAN_Kommunik : 26|1@1+ (1,0) [0|0] "" XXX
 SG_ Steuergeraet_k__CAN_Kommunik__S : 25|1@1+ (1,0) [0|0] "" XXX
 SG_ Steuergeraet_keine_CAN_Kommunik : 24|1@1+ (1,0) [0|0] "" XXX
 SG_ Lenkhilfe_Spannung_Ks__nach_Mas : 23|1@1+ (1,0) [0|0] "" XXX
 SG_ Lenkhilfe_Spannung_Ks_nach_Mass : 22|1@1+ (1,0) [0|0] "" XXX
 SG_ Lenkhilfe_Spannung_Ks__nach___s : 21|1@1+ (1,0) [0|0] "" XXX
 SG_ Lenkhilfe_Spannung_Ks__nach__ : 20|1@1+ (1,0) [0|0] "" XXX
 SG_ Lenkhilfe_Temperaturschutz_sp_ : 19|1@1+ (1,0) [0|0] "" XXX
 SG_ Lenkhilfe_Temperaturschutz : 18|1@1+ (1,0) [0|0] "" XXX
 SG_ Lenkhilfe_Betrieb_unpl__Sig__sp : 17|1@1+ (1,0) [0|0] "" XXX
 SG_ Lenkhilfe_Betrieb_unpl__Signal : 16|1@1+ (1,0) [0|0] "" XXX
 SG_ Lenkhilfesensor_k__Kommunik__sp : 15|1@1+ (1,0) [0|0] "" XXX
 SG_ Lenkhilfesensor_keine_Kommunik_ : 14|1@1+ (1,0) [0|0] "" XXX
 SG_ Lenkhilfesensor_defekt_sp_ : 13|1@1+ (1,0) [0|0] "" XXX
 SG_ Lenkhilfesensor_defekt : 12|1@1+ (1,0) [0|0] "" XXX
 SG_ Lenkhilfesensor_Unterbrechung_s : 11|1@1+ (1,0) [0|0] "" XXX
 SG_ Lenkhilfesensor_Unterbrechung : 10|1@1+ (1,0) [0|0] "" XXX
 SG_ Lenkhilfesensor_Ks_nach_Masse_s : 9|1@1+ (1,0) [0|0] "" XXX
 SG_ Lenkhifesensor_Ks_nach_Masse : 8|1@1+ (1,0) [0|0] "" XXX
 SG_ Spannung_Kl_15_zu_klein_sp_ : 7|1@1+ (1,0) [0|0] "" XXX
 SG_ Spannung_Kl_15_zu_klein : 6|1@1+ (1,0) [0|0] "" XXX
 SG_ Frei_Lenkhilfe_1_5 : 4|2@1+ (1,0) [0|0] "" XXX
 SG_ Spannung_Kl_30_zu_klein_sp_ : 3|1@1+ (1,0) [0|0] "" XXX
 SG_ Spannung_Kl_30_zu_klein : 2|1@1+ (1,0) [0|0] "" XXX
 SG_ Spannung_Kl_30_zu_gro__sp_ : 1|1@1+ (1,0) [0|0] "" XXX
 SG_ Spannung_Kl_30_zu_gro_ : 0|1@1+ (1,0) [0|0] "" XXX

BO_ 976 Lenkhilfe_1: 2 XXX
 SG_ Fehlerspeichereintrag__Lenkhilf : 15|1@1+ (1,0) [0|0] "" XXX
 SG_ Frei_Lenkhilfe_1_2 : 9|6@1+ (1,0) [0|0] "" XXX
 SG_ Fehlerlampe_Lenkhilfe : 8|1@1+ (1,0) [0|0] "" XXX
 SG_ Fehlerstatus_Lastinformation : 7|1@1+ (1,0) [0|0] "" XXX
 SG_ Lastinformation : 0|7@1+ (1,0) [0|127] "A" XXX

BO_ 1312 Kombi_3: 8 XXX
 SG_ Frei_Kombi_3_2 : 60|4@1+ (1,0) [0|0] "" XXX
 SG_ Kilometerstand : 40|20@1+ (1,0) [0|1000000] "km" XXX
 SG_ Fehlerstatus_Standzeit : 39|1@1+ (1,0) [0|0] "" XXX
 SG_ Standzeit : 24|15@1+ (4,0) [0|131068] "sec" XXX
 SG_ Frei_Kombi_3_1 : 20|4@1+ (1,0) [0|0] "" XXX
 SG_ Schluesselinfo : 16|4@1+ (1,0) [0|15] "" XXX
 SG_ Kombi_Multiplex_Code M : 14|2@1+ (1,0) [0|0] "" XXX
 SG_ Kombi_Verbauliste_Niveauregulie m3 : 11|1@1+ (1,0) [0|0] "" XXX
 SG_ Kombi_Multiplex_Marke m1 : 11|3@1+ (1,0) [0|0] "" XXX
 SG_ Kombi_Verbauliste_Lenkhilfe m3 : 10|1@1+ (1,0) [0|0] "" XXX
 SG_ Kombi_Verbauliste_Dieselpumpe m3 : 9|1@1+ (1,0) [0|0] "" XXX
 SG_ Kombi_Verbauliste_Lenkwinkel m3 : 8|1@1+ (1,0) [0|0] "" XXX
 SG_ Kombi_Multiplex_Baureihe m1 : 8|3@1+ (1,0) [0|0] "" XXX
 SG_ Kombi_Multiplex_Laendervariante m0 : 8|6@1+ (1,0) [0|0] "" XXX
 SG_ Kombi_Verbauliste_Allrad m3 : 7|1@1+ (1,0) [0|0] "" XXX
 SG_ Kombi_Verbauliste_Bordnetz m3 : 6|1@1+ (1,0) [0|0] "" XXX
 SG_ Kombi_Verbauliste_ACC m3 : 5|1@1+ (1,0) [0|0] "" XXX
 SG_ Kombi_Verbauliste_Airbag m3 : 4|1@1+ (1,0) [0|0] "" XXX
 SG_ Kombi_Multiplex_Generation m1 : 4|4@1+ (1,0) [0|0] "" XXX
 SG_ Kombi_Verbauliste_Klima m3 : 3|1@1+ (1,0) [0|0] "" XXX
 SG_ Kombi_Verbauliste_ABS m3 : 2|1@1+ (1,0) [0|0] "" XXX
 SG_ Kombi_Verbauliste_Motor m3 : 0|1@1+ (1,0) [0|0] "" XXX
 SG_ Kombi_Multiplex_Derivat m1 : 0|4@1+ (1,0) [0|0] "" XXX
 SG_ Kombi_Multiplex_Sprachvariante m0 : 0|8@1+ (1,0) [0|0] "" XXX
 SG_ Kombi_Multiplex_Reifenumfang m2 : 0|12@1+ (1,0) [0|4095] "mm" XXX

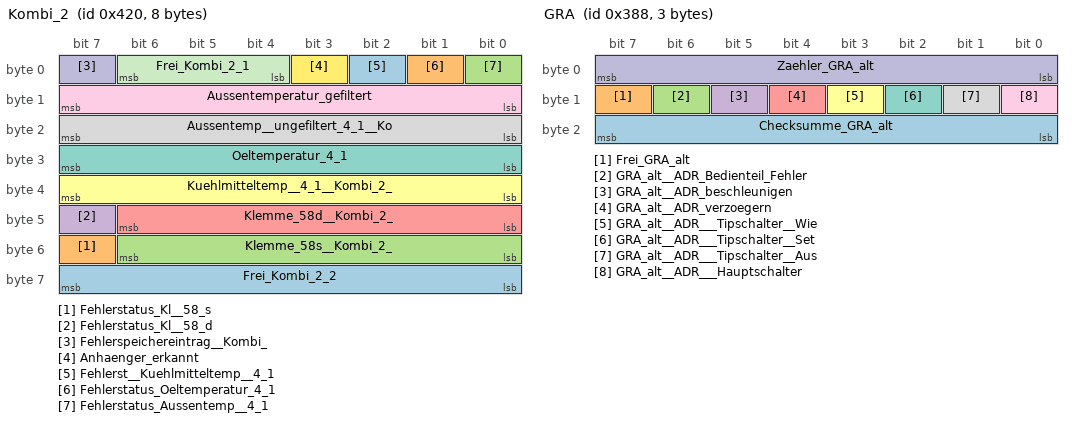
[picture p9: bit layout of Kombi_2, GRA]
BO_ 1056 Kombi_2: 8 XXX
 SG_ Frei_Kombi_2_2 : 56|8@1+ (1,0) [0|0] "" XXX
 SG_ Fehlerstatus_Kl__58_s : 55|1@1+ (1,0) [0|0] "" XXX
 SG_ Klemme_58s__Kombi_2_ : 48|7@1+ (1,0) [0|100] "%" XXX
 SG_ Fehlerstatus_Kl__58_d : 47|1@1+ (1,0) [0|0] "" XXX
 SG_ Klemme_58d__Kombi_2_ : 40|7@1+ (1,0) [0|100] "%" XXX
 SG_ Kuehlmitteltemp__4_1__Kombi_2_ : 32|8@1+ (0.75,-48) [-48|142.5] "C" XXX
 SG_ Oeltemperatur_4_1 : 24|8@1+ (1,-60) [-60|194] "C" XXX
 SG_ Aussentemp__ungefiltert_4_1__Ko : 16|8@1+ (0.5,-50) [-50|77] "C" XXX
 SG_ Aussentemperatur_gefiltert : 8|8@1+ (0.5,-50) [-50|77] "C" XXX
 SG_ Fehlerspeichereintrag__Kombi_ : 7|1@1+ (1,0) [0|0] "" XXX
 SG_ Frei_Kombi_2_1 : 4|3@1+ (1,0) [0|0] "" XXX
 SG_ Anhaenger_erkannt : 3|1@1+ (1,0) [0|0] "" XXX
 SG_ Fehlerst__Kuehlmitteltemp__4_1 : 2|1@1+ (1,0) [0|0] "" XXX
 SG_ Fehlerstatus_Oeltemperatur_4_1 : 1|1@1+ (1,0) [0|0] "" XXX
 SG_ Fehlerstatus_Aussentemp__4_1 : 0|1@1+ (1,0) [0|0] "" XXX

BO_ 800 Kombi_1: 8 XXX
 SG_ Frei_Kombi_1_3 : 56|8@1+ (1,0) [0|0] "" XXX
 SG_ Angezeigte_Geschwindigkeit : 46|10@1+ (0.32,0) [0|325] "km/h" XXX
 SG_ Blinker_rechts_4_1 : 45|1@1+ (1,0) [0|0] "" XXX
 SG_ Blinker_links_4_1 : 44|1@1+ (1,0) [0|0] "" XXX
 SG_ Gesetzte_Zeitluecke__Kombi_1_ : 43|1@1+ (1,0) [0|0] "" XXX
 SG_ ADR_Summer_abgeschaltet : 42|1@1+ (1,0) [0|0] "" XXX
 SG_ Frei_Kombi_1_2 : 40|2@1+ (1,0) [0|0] "" XXX
 SG_ Geschwindigkeit__Kombi_1_ : 25|15@1+ (0.01,0) [0|326] "km/h" XXX
 SG_ Signalquelle_Geschwindigkeit_4_ : 24|1@1+ (1,0) [0|0] "" XXX
 SG_ Tankwarnung : 23|1@1+ (1,0) [0|0] "" XXX
 SG_ Tankinhalt : 16|7@1+ (1,0) [0|126] "l" XXX
 SG_ Tankstop : 15|1@1+ (1,0) [0|0] "" XXX
 SG_ Frei_Kombi_1_7 : 12|3@1+ (1,0) [0|0] "" XXX
 SG_ Kombi_im_Stellgliedtest : 11|1@1+ (1,0) [0|0] "" XXX
 SG_ Ladekontroll_Lampe__Kombi_ : 10|1@1+ (1,0) [0|0] "" XXX
 SG_ Bremsinfo : 8|2@1+ (1,0) [0|0] "" XXX
 SG_ Vorgluehlampe__Kombi_1_ : 7|1@1+ (1,0) [0|0] "" XXX
 SG_ Tankwarnlampe : 6|1@1+ (1,0) [0|0] "" XXX
 SG_ Heissleuchten_Vorwarnung : 5|1@1+ (1,0) [0|0] "" XXX
 SG_ Kuehlmittelmangel : 4|1@1+ (1,0) [0|0] "" XXX
 SG_ Dynamische_Oeldruckwarnung : 3|1@1+ (1,0) [0|0] "" XXX
 SG_ Oeldruck : 2|1@1+ (1,0) [0|0] "" XXX
 SG_ Fehlerstatus_Tank : 1|1@1+ (1,0) [0|0] "" XXX
 SG_ Fahrertuer_4_1 : 0|1@1+ (1,0) [0|0] "" XXX

BO_ 1504 Klima_1: 8 XXX
 SG_ Aussentemp__ungef__Sto_f__4_1 : 56|8@1+ (0.5,-50) [-50|77] "C" XXX
 SG_ Fehlerspeichereintrag__Klima_ : 55|1@1+ (1,0) [0|0] "" XXX
 SG_ Frei_Klima_1_5 : 50|5@1+ (1,0) [0|0] "" XXX
 SG_ AC_Schalter : 49|1@1+ (1,0) [0|0] "" XXX
 SG_ Temperatureinheit : 48|1@1+ (1,0) [0|0] "" XXX
 SG_ Kuehlerluefteransteuerung__Klim : 40|8@1+ (0.4,0) [0|101.6] "%" XXX
 SG_ Geblaeselast_4_1 : 32|8@1+ (0.4,0) [0|101.6] "%" XXX
 SG_ Kompressorlast : 24|8@1+ (0.25,0) [0|63.5] "Nm" XXX
 SG_ Klimadrucksignal__Klima_1_ : 16|8@1+ (0.2,0) [0|50.8] "bar" XXX
 SG_ Aussentemp__ungef__4_1__Klima_1 : 8|8@1+ (0.5,-50) [-50|77] "C" XXX
 SG_ Kaeltemitteldruck_veraltet : 7|1@1+ (1,0) [0|0] "" XXX
 SG_ Kompressormoment_veraltet_4_1 : 6|1@1+ (1,0) [0|0] "" XXX
 SG_ Keine_Heizleistg_gewuenscht_4_1 : 5|1@1+ (1,0) [0|0] "" XXX
 SG_ Kompressorzustand__4_1_ : 4|1@1+ (1,0) [0|0] "" XXX
 SG_ Heizbare_Frontscheibe : 3|1@1+ (1,0) [0|0] "" XXX
 SG_ Heizbare_Heckscheibe : 2|1@1+ (1,0) [0|0] "" XXX
 SG_ Fahrerwunsch_Zuheizer : 1|1@1+ (1,0) [0|0] "" XXX
 SG_ Drehzahlanhebung : 0|1@1+ (1,0) [0|0] "" XXX

BO_ 906 GRA_Neu: 4 XXX
 SG_ CHECKSUM : 0|8@1+ (1,0) [0|255] "" XXX
 SG_ GRA_Hauptschalt : 8|1@1+ (1,0) [0|1] "" XXX
 SG_ GRA_Abbrechen : 9|1@1+ (1,0) [0|1] "" XXX
 SG_ GRA_Down_kurz : 10|1@1+ (1,0) [0|1] "" XXX
 SG_ GRA_Up_kurz : 11|1@1+ (1,0) [0|1] "" XXX
 SG_ GRA_Down_lang : 12|1@1+ (1,0) [0|1] "" XXX
 SG_ GRA_Up_lang : 13|1@1+ (1,0) [0|1] "" XXX
 SG_ GRA_Fehler_Bed : 14|1@1+ (1,0) [0|1] "" XXX
 SG_ GRA_Kodierinfo : 15|1@1+ (1,0) [0|1] "" XXX
 SG_ GRA_Neu_Setzen : 16|1@1+ (1,0) [0|1] "" XXX
 SG_ GRA_Recall : 17|1@1+ (1,0) [0|1] "" XXX
 SG_ GRA_Sender : 18|2@1+ (1,0) [0|3] "" XXX
 SG_ COUNTER : 20|4@1+ (1,0) [0|15] "" XXX
 SG_ GRA_Tip_Down : 24|1@1+ (1,0) [0|1] "" XXX
 SG_ GRA_Tip_Up : 25|1@1+ (1,0) [0|1] "" XXX
 SG_ GRA_Zeitluecke : 26|2@1+ (1,0) [0|3] "" XXX
 SG_ GRA_Sta_Limiter : 28|1@1+ (1,0) [0|1] "" XXX
 SG_ GRA_Typ_Hauptschalt : 29|1@1+ (1,0) [0|1] "" XXX
 SG_ GRA_Sportschalter : 30|1@1+ (1,0) [0|1] "" XXX
 SG_ GRA_Fehler_Tip : 31|1@1+ (1,0) [0|1] "" XXX

BO_ 904 GRA: 3 XXX
 SG_ Checksumme_GRA_alt : 16|8@1+ (1,0) [0|0] "" XXX
 SG_ Frei_GRA_alt : 15|1@1+ (1,0) [0|0] "" XXX
 SG_ GRA_alt__ADR_Bedienteil_Fehler : 14|1@1+ (1,0) [0|0] "" XXX
 SG_ GRA_alt__ADR_beschleunigen : 13|1@1+ (1,0) [0|0] "" XXX
 SG_ GRA_alt__ADR_verzoegern : 12|1@1+ (1,0) [0|0] "" XXX
 SG_ GRA_alt__ADR___Tipschalter__Wie : 11|1@1+ (1,0) [0|0] "" XXX
 SG_ GRA_alt__ADR___Tipschalter__Set : 10|1@1+ (1,0) [0|0] "" XXX
 SG_ GRA_alt__ADR___Tipschalter__Aus : 9|1@1+ (1,0) [0|0] "" XXX
 SG_ GRA_alt__ADR___Hauptschalter : 8|1@1+ (1,0) [0|0] "" XXX
 SG_ Zaehler_GRA_alt : 0|8@1+ (1,0) [0|255] "" XXX

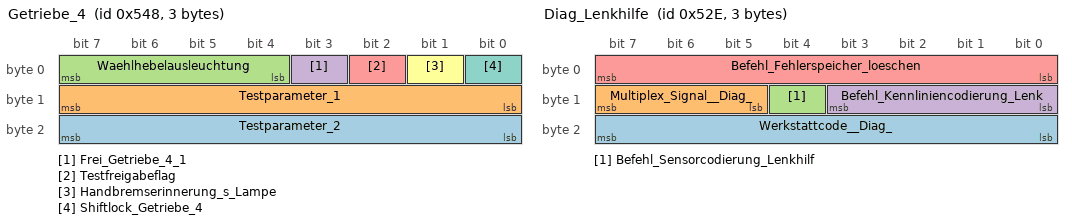
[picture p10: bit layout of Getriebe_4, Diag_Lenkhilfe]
BO_ 1352 Getriebe_4: 3 XXX
 SG_ Testparameter_2 : 16|8@1+ (1,0) [0|255] "" XXX
 SG_ Testparameter_1 : 8|8@1+ (1,0) [0|255] "" XXX
 SG_ Waehlhebelausleuchtung : 4|4@1+ (1,0) [0|0] "" XXX
 SG_ Frei_Getriebe_4_1 : 3|1@1+ (1,0) [0|0] "" XXX
 SG_ Testfreigabeflag : 2|1@1+ (1,0) [0|0] "" XXX
 SG_ Handbremserinnerung_s_Lampe : 1|1@1+ (1,0) [0|0] "" XXX
 SG_ Shiftlock_Getriebe_4 : 0|1@1+ (1,0) [0|0] "" XXX

BO_ 1344 Getriebe_2: 8 XXX
 SG_ eingelegte_Fahrstufe : 60|4@1+ (1,0) [0|0] "" XXX
 SG_ Ganganzeige_Kombi___Getriebe_Va : 56|4@1+ (1,0) [0|15] "" XXX
 SG_ Fehlerlampe_f_r_Kupplung_bei_VL : 55|1@1+ (1,0) [0|0] "" XXX
 SG_ Anforderung_Kriechadaption : 54|1@1+ (1,0) [0|0] "" XXX
 SG_ ECO_Anzeige__4_1_ : 53|1@1+ (1,0) [0|0] "" XXX
 SG_ Shift_Lock_Lampe : 52|1@1+ (1,0) [0|0] "" XXX
 SG_ Unterdrueckung_von_Warnungen : 51|1@1+ (1,0) [0|0] "" XXX
 SG_ Gong : 50|1@1+ (1,0) [0|0] "" XXX
 SG_ Starter_wird_angesteuert : 49|1@1+ (1,0) [0|0] "" XXX
 SG_ Hochschaltlampe : 48|1@1+ (1,0) [0|0] "" XXX
 SG_ Synchronisationszeit : 40|8@1+ (20,0) [0|5080] "ms" XXX
 SG_ invertierte_Synchronisations_Wu : 32|8@1+ (25,0) [0|6350] "U/min" XXX
 SG_ Synchronisations_Wunschdrehzahl : 24|8@1+ (25,0) [0|6350] "U/min" XXX
 SG_ Gradientenbegrenzung : 16|8@1+ (10,0) [0|2540] "Nm/s" XXX
 SG_ Leerlaufsolldrehzahl__Getriebe : 8|8@1+ (10,0) [0|2540] "U/min" XXX
 SG_ Zahler_Getriebe_2 : 4|4@1+ (1,0) [0|15] "" XXX
 SG_ Zwischengasflag : 3|1@1+ (1,0) [0|0] "" XXX
 SG_ Ecomatic__4_1_ : 2|1@1+ (1,0) [0|0] "" XXX
 SG_ Schubabschaltunterstuetzung : 1|1@1+ (1,0) [0|0] "" XXX
 SG_ LFR_Adaption_Freigabeflag : 0|1@1+ (1,0) [0|0] "" XXX

BO_ 1088 Getriebe_1: 8 XXX
 SG_ Wandlerverlustmoment : 56|8@1+ (0.39,0) [0|99.06] "MDI" XXX
 SG_ Fehlerspeichereintrag__Getriebe : 55|1@1+ (1,0) [0|0] "" XXX
 SG_ COUNTER : 51|4@1+ (1,0) [0|15] "" XXX
 SG_ Gang_eingelegt : 50|1@1+ (1,0) [0|0] "" XXX
 SG_ Schaltabsicht : 49|1@1+ (1,0) [0|0] "" XXX
 SG_ Motor_aus : 48|1@1+ (1,0) [0|0] "" XXX
 SG_ OBD_Status__Getriebe_1___4_1_ : 46|2@1+ (1,0) [0|0] "" XXX
 SG_ Kuehlleistung : 44|2@1+ (1,0) [0|0] "" XXX
 SG_ Getriebe_Notlauf : 40|4@1+ (1,0) [0|0] "" XXX
 SG_ Fahrwiderstandsindex : 32|8@1+ (0.249,-31.6) [-31.6|31.6] "" XXX
 SG_ inneres_Soll_Motormoment : 24|8@1+ (0.39,0) [0|99.06] "MDI" XXX
 SG_ Uebertragungsfunktion : 16|8@1+ (0.1,0) [0|25.4] "" XXX
 SG_ Waehlhebelposition__Getriebe_1_ : 12|4@1+ (1,0) [0|0] "" XXX
 SG_ Zielgang_oder_eingelegter_Gang : 8|4@1+ (1,0) [0|0] "" XXX
 SG_ EGS_Anforderung : 7|1@1+ (1,0) [0|0] "" XXX
 SG_ Kodierung_im_MSG : 6|1@1+ (1,0) [0|0] "" XXX
 SG_ Leerlaufsolldrehzahlanhebung : 5|1@1+ (1,0) [0|0] "" XXX
 SG_ Wandlerkupplung : 3|2@1+ (1,0) [0|0] "" XXX
 SG_ Klimakompressor_aus__Getriebe_1 : 2|1@1+ (1,0) [0|0] "" XXX
 SG_ Status_Getriebe_und_Wandlerschu : 1|1@1+ (1,0) [0|0] "" XXX
 SG_ Schaltung_aktiv__Getriebe_1_ : 0|1@1+ (1,0) [0|0] "" XXX

BO_ 912 Gate_Komf_1: 8 XXX
 SG_ GK1_Sta_RDK_Warn : 0|1@1+ (1,0) [0|1] "" XXX
 SG_ GK1_Sta_Anhaen : 1|1@1+ (1,0) [0|1] "" XXX
 SG_ GK1_Sta_Licht1 : 2|1@1+ (1,0) [0|1] "" XXX
 SG_ GK1_Sta_Licht3 : 3|1@1+ (1,0) [0|1] "" XXX
 SG_ GK1_Sta_Tuerkont : 4|1@1+ (1,0) [0|1] "" XXX
 SG_ GK1_Sta_Li_vorn : 5|1@1+ (1,0) [0|1] "" XXX
 SG_ GK1_SleepAckn : 7|1@1+ (1,0) [0|1] "" XXX
 SG_ GK1_CharismaModus m1 : 8|4@1+ (1,0) [0|15] "" XXX
 SG_ GK1_SamFktNr M : 12|4@1+ (1,0) [0|15] "" XXX
 SG_ GK1_Fa_Tuerkont : 16|1@1+ (1,0) [0|1] "" XXX
 SG_ GK1_RueckfahrSch : 17|1@1+ (1,0) [0|1] "" XXX
 SG_ GK1_ELV_verrieg : 18|1@1+ (1,0) [0|1] "" XXX
 SG_ GK1_Sta_Kessy_2 : 19|1@1+ (1,0) [0|1] "" XXX
 SG_ GK1_Sta_Stdhzg : 20|1@1+ (1,0) [0|1] "" XXX
 SG_ GK1_SH_Verbau : 21|1@1+ (1,0) [0|1] "" XXX
 SG_ GK1_ParkFrontWi : 22|1@1+ (1,0) [0|1] "" XXX
 SG_ GK1_KW_Warm : 23|1@1+ (1,0) [0|1] "" XXX
 SG_ BCM_Remotestart_Betrieb : 24|1@1+ (1,0) [0|1] "" XXX
 SG_ BSK_HL_geoeffnet : 26|1@1+ (1,0) [0|1] "" XXX
 SG_ BSK_HR_geoeffnet : 27|1@1+ (1,0) [0|1] "" XXX
 SG_ GK1_Rueckfahr : 28|1@1+ (1,0) [0|1] "" XXX
 SG_ GK1_BrLi_links : 29|1@1+ (1,0) [0|1] "" XXX
 SG_ GK1_BrLi_rechts : 30|1@1+ (1,0) [0|1] "" XXX
 SG_ GK1_BrLi_mitte : 31|1@1+ (1,0) [0|1] "" XXX
 SG_ GK1_BLS_ILM : 32|1@1+ (1,0) [0|1] "" XXX
 SG_ GK1_EDC_ILM : 33|1@1+ (1,0) [0|1] "" XXX
 SG_ GK1_Blinker_li : 34|1@1+ (1,0) [0|1] "" XXX
 SG_ GK1_Blinker_re : 35|1@1+ (1,0) [0|1] "" XXX
 SG_ GK1_def_P_verr : 36|1@1+ (1,0) [0|1] "" XXX
 SG_ GK1_LS1_Fernlicht : 37|1@1+ (1,0) [0|1] "" XXX
 SG_ GK1_Sta_Licht2 : 38|1@1+ (1,0) [0|1] "" XXX
 SG_ GK1_Sta_LSM : 39|1@1+ (1,0) [0|1] "" XXX
 SG_ GK1_Count_Anhaen : 40|4@1+ (1,0) [0|15] "" XXX
 SG_ BSK_BT_geoeffnet : 41|1@1+ (1,0) [0|1] "" XXX
 SG_ BSK_HD_Hauptraste : 43|1@1+ (1,0) [0|1] "" XXX
 SG_ GK1_BLS_AAG : 44|1@1+ (1,0) [0|1] "" XXX
 SG_ GK1_EDC_AAG : 45|1@1+ (1,0) [0|1] "" XXX
 SG_ GK1_Anhaenger : 46|1@1+ (1,0) [0|1] "" XXX
 SG_ GK1_BrLi_Anhaen : 47|1@1+ (1,0) [0|1] "" XXX
 SG_ GK1_Abblendlicht : 48|1@1+ (1,0) [0|1] "" XXX
 SG_ GK1_Fernlicht : 49|1@1+ (1,0) [0|1] "" XXX
 SG_ GK1_Wischer_vorn : 50|1@1+ (1,0) [0|1] "" XXX
 SG_ GK1_Sta_ILM_F_1 : 51|1@1+ (1,0) [0|1] "" XXX
 SG_ GK1_Abbl_VL_def : 52|1@1+ (1,0) [0|1] "" XXX
 SG_ GK1_Abbl_VR_def : 53|1@1+ (1,0) [0|1] "" XXX
 SG_ GK1_Blink_Autob : 54|1@1+ (1,0) [0|1] "" XXX
 SG_ GK1_Warnblk_Status : 55|1@1+ (1,0) [0|1] "" XXX
 SG_ GK1_SH_laeuft : 56|1@1+ (1,0) [0|1] "" XXX
 SG_ SH1_ein_Wasserpumpe : 57|1@1+ (1,0) [0|1] "" XXX
 SG_ GK1_Nebel_ein : 58|1@1+ (1,0) [0|1] "" XXX
 SG_ GK1_Bremslicht : 59|1@1+ (1,0) [0|1] "" XXX
 SG_ GK1_Anh_abgesteckt : 60|1@1+ (1,0) [0|1] "" XXX
 SG_ GK1_AnhKonLamp : 61|1@1+ (1,0) [0|1] "" XXX
 SG_ LDS_Stellung_AFL : 62|1@1+ (1,0) [0|1] "" XXX
 SG_ GK1_SH_Zusatzfkt : 63|1@1+ (1,0) [0|1] "" XXX

BO_ 1340 Fahrwerk_1: 1 XXX
 SG_ Frei_Fahrwerk_1_2 : 7|1@1+ (1,0) [0|0] "" XXX
 SG_ Frei_Fahrwerk_1_1 : 6|2@1+ (1,0) [0|0] "" XXX
 SG_ Einstellung_Fahrwerkdaempfung_4 : 4|3@1+ (1,0) [0|7] "" XXX
 SG_ Ansteuererung_Fahrzeugniveau : 0|4@1+ (1,0) [0|15] "" XXX

BO_ 1472 EPB_1: 8 XXX
 SG_ COUNTER : 0|4@1+ (1,0) [0|15] "" XXX
 SG_ EP1_Fehler_Sta : 4|2@1+ (1,0) [0|3] "" Vector__XXX
 SG_ EP1_Sta_EPB : 6|1@1+ (1,0) [0|1] "" XXX
 SG_ EP1_Sta_Schalter : 7|1@1+ (1,0) [0|1] "" XXX
 SG_ EP1_Spannkraft : 8|5@1+ (1,0) [0|30] "Unit_KiloNewto" XXX
 SG_ EP1_Schalterinfo : 13|2@1+ (1,0) [0|3] "" XXX
 SG_ EP1_Sta_NWS : 15|1@1+ (1,0) [0|1] "" XXX
 SG_ EP1_Neig_winkel : 16|8@1+ (1,-128) [-128|127] "Unit_PerCentOfForceOfGravi" XXX
 SG_ EP1_Verzoegerung : 24|8@1+ (0.048,-7.968) [-7.968|4.224] "Unit_MeterPerSeconSquar" XXX
 SG_ EP1_Fehlereintr : 32|1@1+ (1,0) [0|1] "" XXX
 SG_ EP1_Freigabe_Ver : 33|1@1+ (1,0) [0|1] "" XXX
 SG_ EP1_AutoHold_zul : 34|1@1+ (1,0) [0|1] "" XXX
 SG_ EP1_AutoHold_aktiv : 35|1@1+ (1,0) [0|1] "" XXX
 SG_ EP1_SleepInd : 36|1@1+ (1,0) [0|1] "" XXX
 SG_ EP1_Status_Kl_15 : 37|1@1+ (1,0) [0|1] "" XXX
 SG_ EP1_Lampe_AutoP : 38|1@1+ (1,0) [0|1] "" XXX
 SG_ EP1_Bremslicht : 39|1@1+ (1,0) [0|1] "" XXX
 SG_ EP1_Warnton1 : 40|1@1+ (1,0) [0|1] "" XXX
 SG_ EP1_Warnton2 : 41|1@1+ (1,0) [0|1] "" XXX
 SG_ EP1_AnfShLock : 42|1@1+ (1,0) [0|1] "" XXX
 SG_ EPB_Autoholdlampe : 43|1@1+ (1,0) [0|1] "" XXX
 SG_ EP1_QualNeigWi : 44|1@1+ (1,0) [0|1] "" XXX
 SG_ EP1_KuppModBer : 45|2@1+ (1,0) [0|3] "" XXX
 SG_ EP1_HydrHalten : 47|1@1+ (1,0) [0|1] "" XXX
 SG_ EP1_Fkt_Lampe : 48|1@1+ (1,0) [0|1] "" Vector__XXX
 SG_ EP1_Warnton : 49|1@1+ (1,0) [0|1] "" XXX
 SG_ EP1_Fehler_BKL : 50|1@1+ (1,0) [0|1] "" Vector__XXX
 SG_ EP1_Fehler_gelb : 51|1@1+ (1,0) [0|1] "" XXX
 SG_ EP1__Text : 52|4@1+ (1,0) [0|8] "" Vector__XXX
 SG_ CHECKSUM : 56|8@1+ (1,0) [0|255] "" XXX

BO_ 1326 Diag_Lenkhilfe: 3 XXX
 SG_ Werkstattcode__Diag_ : 16|8@1+ (1,0) [0|0] "" XXX
 SG_ Multiplex_Signal__Diag_ : 13|3@1+ (1,0) [0|7] "" XXX
 SG_ Befehl_Sensorcodierung_Lenkhilf : 12|1@1+ (1,0) [0|0] "" XXX
 SG_ Befehl_Kennliniencodierung_Lenk : 8|4@1+ (1,0) [0|0] "" XXX
 SG_ Befehl_Fehlerspeicher_loeschen : 0|8@1+ (1,0) [0|0] "" XXX

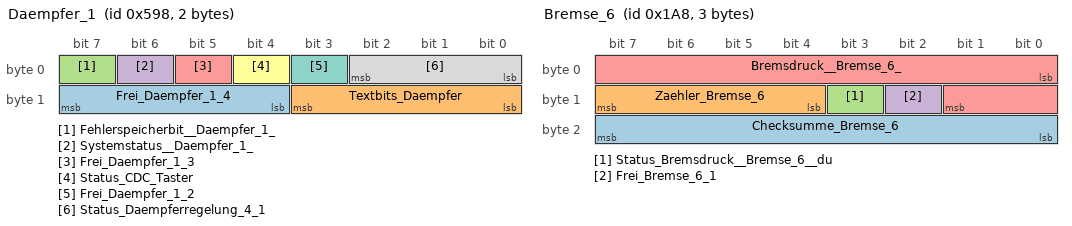
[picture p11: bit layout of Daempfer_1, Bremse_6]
BO_ 1432 Daempfer_1: 2 XXX
 SG_ Frei_Daempfer_1_4 : 12|4@1+ (1,0) [0|0] "" XXX
 SG_ Textbits_Daempfer : 8|4@1+ (1,0) [0|0] "" XXX
 SG_ Fehlerspeicherbit__Daempfer_1_ : 7|1@1+ (1,0) [0|0] "" XXX
 SG_ Systemstatus__Daempfer_1_ : 6|1@1+ (1,0) [0|0] "" XXX
 SG_ Frei_Daempfer_1_3 : 5|1@1+ (1,0) [0|0] "" XXX
 SG_ Status_CDC_Taster : 4|1@1+ (1,0) [0|0] "" XXX
 SG_ Frei_Daempfer_1_2 : 3|1@1+ (1,0) [0|0] "" XXX
 SG_ Status_Daempferregelung_4_1 : 0|3@1+ (1,0) [0|7] "" XXX

BO_ 1392 BSG_Last: 4 XXX
 SG_ Klimaanlage_abschalten : 31|1@1+ (1,0) [0|0] "" XXX
 SG_ Sitzbelueftung_abschalten : 30|1@1+ (1,0) [0|0] "" XXX
 SG_ Wischwasserheizung_abschalten : 29|1@1+ (1,0) [0|0] "" XXX
 SG_ Lenkradheizung_abschalten : 28|1@1+ (1,0) [0|0] "" XXX
 SG_ Heizbare_Sitze_abschalten : 27|1@1+ (1,0) [0|0] "" XXX
 SG_ Heizbare_Aussenspiegel_abschalt : 26|1@1+ (1,0) [0|0] "" XXX
 SG_ Heizbare_Frontscheibe_abschalte : 25|1@1+ (1,0) [0|0] "" XXX
 SG_ Heizbare_Heckscheibe_abschalten : 24|1@1+ (1,0) [0|0] "" XXX
 SG_ Batteriespannung_Bordnetzbatter : 16|8@1+ (0.05,5) [5|17.7] "V" XXX
 SG_ Motorhaubenkontakt : 15|1@1+ (1,0) [0|0] "" XXX
 SG_ Leuchtweitenregulierung : 14|1@1+ (1,0) [0|0] "" XXX
 SG_ Fehlerspeichereintrag__BSG_Last : 13|1@1+ (1,0) [0|0] "" XXX
 SG_ Zustand_der_Starterbatterie : 11|2@1+ (1,0) [0|0] "" XXX
 SG_ Zustand_der_Bordnetzbatterie : 9|2@1+ (1,0) [0|0] "" XXX
 SG_ LL_Drehzahlanhebung : 8|1@1+ (1,0) [0|0] "" XXX
 SG_ Klemme_L : 7|1@1+ (1,0) [0|0] "" XXX
 SG_ Frei_BSG_Last_1_1 : 4|3@1+ (1,0) [0|0] "" XXX
 SG_ ZAS_Klemme_50 : 3|1@1+ (1,0) [0|0] "" XXX
 SG_ ZAS_Klemme_X : 2|1@1+ (1,0) [0|0] "" XXX
 SG_ ZAS_Klemme_15 : 1|1@1+ (1,0) [0|0] "" XXX
 SG_ ZAS_Klemme_S : 0|1@1+ (1,0) [0|0] "" XXX

BO_ 1136 BSG_Kombi: 5 XXX
 SG_ Frei_BSG_Kombi_1_3 : 36|4@1+ (1,0) [0|0] "" XXX
 SG_ Ruecksitzlehne_HR_verr__4_1 : 35|1@1+ (1,0) [0|0] "" XXX
 SG_ Ruecksitzlehne_HL_verr__4_1 : 34|1@1+ (1,0) [0|0] "" XXX
 SG_ Fehlerlampe_Lenkhilfe_veraltet : 33|1@1+ (1,0) [0|0] "" XXX
 SG_ Fehlerlampe_Lenkhilfe__BSG_Komb : 32|1@1+ (1,0) [0|0] "" XXX
 SG_ Fehlerstatus_Kl__58s : 31|1@1+ (1,0) [0|0] "" XXX
 SG_ Klemme_58s__BSG_Kombi_ : 24|7@1+ (1,0) [0|100] "%" XXX
 SG_ Fehlerstatus_Kl__58d : 23|1@1+ (1,0) [0|0] "" XXX
 SG_ Klemme_58d__BSG_Kombi_ : 16|7@1+ (1,0) [0|100] "%" XXX
 SG_ Unterspannung : 15|1@1+ (1,0) [0|0] "" XXX
 SG_ Frei_BSG_Kombi_1_2 : 14|1@1+ (1,0) [0|0] "" XXX
 SG_ Heckdeckel_geoeffnet : 13|1@1+ (1,0) [0|0] "" XXX
 SG_ Motorhaube_geoeffnet : 12|1@1+ (1,0) [0|0] "" XXX
 SG_ Tuer_hinten_rechts_geoeffnet : 11|1@1+ (1,0) [0|0] "" XXX
 SG_ Tuer_hinten_links_geoeffnet : 10|1@1+ (1,0) [0|0] "" XXX
 SG_ Beifahrertuer_geoeffnet : 9|1@1+ (1,0) [0|0] "" XXX
 SG_ Fahrertuer_geoeffnet : 8|1@1+ (1,0) [0|0] "" XXX
 SG_ Lade_Kontrollampe : 7|1@1+ (1,0) [0|0] "" XXX
 SG_ Frei_BSG_Kombi_1_1 : 6|1@1+ (1,0) [0|0] "" XXX
 SG_ Rueckfahrlicht : 5|1@1+ (1,0) [0|0] "" XXX
 SG_ DWA_Akku : 4|1@1+ (1,0) [0|0] "" XXX
 SG_ Warnblink_Mode : 3|1@1+ (1,0) [0|0] "" XXX
 SG_ Anhaenger_Kontrollampe : 2|1@1+ (1,0) [0|0] "" XXX
 SG_ Blinker_rechts_Kontrollampe : 1|1@1+ (1,0) [0|0] "" XXX
 SG_ Blinker_links_Kontrollampe : 0|1@1+ (1,0) [0|0] "" XXX

BO_ 424 Bremse_6: 3 XXX
 SG_ Checksumme_Bremse_6 : 16|8@1+ (1,0) [0|0] "" XXX
 SG_ Zaehler_Bremse_6 : 12|4@1+ (1,0) [0|15] "" XXX
 SG_ Status_Bremsdruck__Bremse_6__du : 11|1@1+ (1,0) [0|0] "" XXX
 SG_ Frei_Bremse_6_1 : 10|1@1+ (1,0) [0|0] "" XXX
 SG_ Bremsdruck__Bremse_6_ : 0|10@1+ (0.3255,-40) [-40|293] "bar" XXX

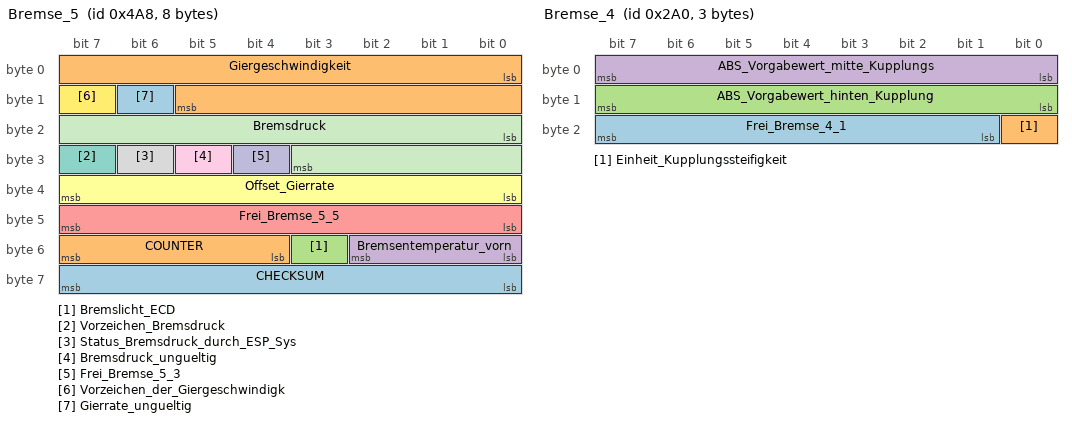
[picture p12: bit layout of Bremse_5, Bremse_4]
BO_ 1192 Bremse_5: 8 XXX
 SG_ CHECKSUM : 56|8@1+ (1,0) [0|0] "" XXX
 SG_ COUNTER : 52|4@1+ (1,0) [0|15] "" XXX
 SG_ Bremslicht_ECD : 51|1@1+ (1,0) [0|0] "" XXX
 SG_ Bremsentemperatur_vorn : 48|3@1+ (125,125) [125|1000] "C" XXX
 SG_ Frei_Bremse_5_5 : 40|8@1+ (1,0) [0|0] "" XXX
 SG_ Offset_Gierrate : 32|8@1+ (0.05,-6.375) [-6.375|6.375] "deg/s" XXX
 SG_ Vorzeichen_Bremsdruck : 31|1@1+ (1,0) [0|0] "" XXX
 SG_ Status_Bremsdruck_durch_ESP_Sys : 30|1@1+ (1,0) [0|0] "" XXX
 SG_ Bremsdruck_ungueltig : 29|1@1+ (1,0) [0|0] "" XXX
 SG_ Frei_Bremse_5_3 : 28|1@1+ (1,0) [0|0] "" XXX
 SG_ Bremsdruck : 16|12@1+ (0.1,0) [0|250] "bar" XXX
 SG_ Vorzeichen_der_Giergeschwindigk : 15|1@1+ (1,0) [0|0] "" XXX
 SG_ Gierrate_ungueltig : 14|1@1+ (1,0) [0|0] "" XXX
 SG_ Giergeschwindigkeit : 0|14@1+ (0.01,0) [0|100] "Grad/sec" XXX

BO_ 672 Bremse_4: 3 XXX
 SG_ Frei_Bremse_4_1 : 17|7@1+ (1,0) [0|0] "" XXX
 SG_ Einheit_Kupplungssteifigkeit : 16|1@1+ (1,0) [0|0] "" XXX
 SG_ ABS_Vorgabewert_hinten_Kupplung : 8|8@1+ (0.7874,0) [0|100] "%" XXX
 SG_ ABS_Vorgabewert_mitte_Kupplungs : 0|8@1+ (3,-381) [-381|378] "Nm/min" XXX

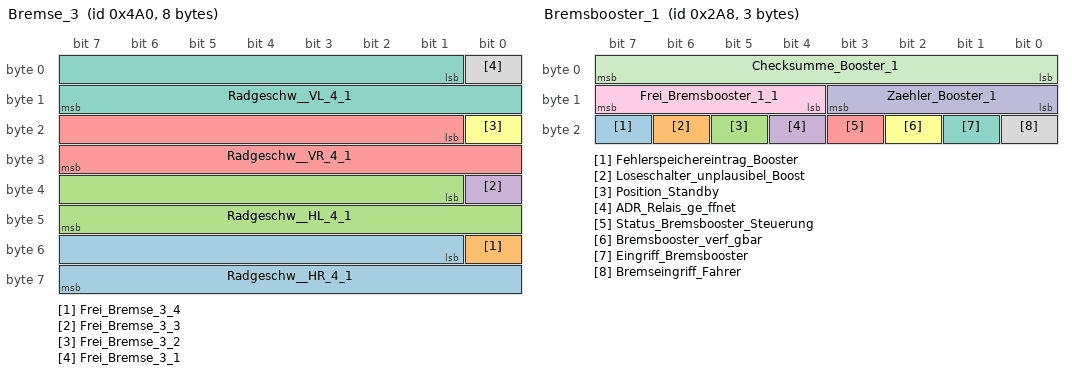
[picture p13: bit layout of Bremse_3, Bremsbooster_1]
BO_ 1184 Bremse_3: 8 XXX
 SG_ Radgeschw__HR_4_1 : 49|15@1+ (0.01,0) [0|326] "km/h" XXX
 SG_ Frei_Bremse_3_4 : 48|1@1+ (1,0) [0|0] "" XXX
 SG_ Radgeschw__HL_4_1 : 33|15@1+ (0.01,0) [0|326] "km/h" XXX
 SG_ Frei_Bremse_3_3 : 32|1@1+ (1,0) [0|0] "" XXX
 SG_ Radgeschw__VR_4_1 : 17|15@1+ (0.01,0) [0|326] "km/h" XXX
 SG_ Frei_Bremse_3_2 : 16|1@1+ (0.01,0) [0|325] "km/h" XXX
 SG_ Radgeschw__VL_4_1 : 1|15@1+ (0.01,0) [0|326] "km/h" XXX
 SG_ Frei_Bremse_3_1 : 0|1@1+ (1,0) [0|0] "" XXX

BO_ 1440 Bremse_2: 8 XXX
 SG_ gemessene_Querbeschleunigung : 63|1@1+ (1,0) [0|0] "" XXX
 SG_ Frei_Bremse_2_2 : 62|1@1+ (1,0) [0|0] "" XXX
 SG_ Impulszahl : 56|6@1+ (1,0) [0|63] "" XXX
 SG_ Fehlerstatus_Wegimpulse_4_1 : 55|1@1+ (1,0) [0|0] "" XXX
 SG_ Frei_Bremse_2_5 : 54|1@1+ (1,0) [0|0] "" XXX
 SG_ Warnlampe_DDS : 53|1@1+ (1,0) [0|0] "" XXX
 SG_ Fehlerspeichereintrag_Bremse : 52|1@1+ (1,0) [0|0] "" XXX
 SG_ Wegimpulszaehlerstatus : 51|1@1+ (1,0) [0|0] "" XXX
 SG_ Wegimpulse_Vorderachse : 40|11@1+ (1,0) [0|2047] "" XXX
 SG_ Zeitstempel : 24|16@1+ (1,0) [0|65535] "tics" XXX
 SG_ mittlere_Raddrehzahl__Bremse_2 : 9|15@1+ (0.002,0) [0|65.278] "U/sec" XXX
 SG_ Querbeschl__TimerTic M : 8|1@1+ (1,0) [0|0] "" XXX
 SG_ Timer m1 : 0|8@1+ (0.04,0) [0|10.2] "usec" XXX
 SG_ Querbeschleunigung m0 : 0|8@1+ (0.01,-1.27) [-1.27|1.27] "g" XXX

BO_ 416 Bremse_1: 8 XXX
 SG_ Geschwindigkeitsersatzwert : 63|1@1+ (1,0) [0|0] "" XXX
 SG_ ESP_Systemstatus_4_1 : 62|1@1+ (1,0) [0|0] "" XXX
 SG_ ESP_Passiv_getastet : 61|1@1+ (1,0) [0|0] "" XXX
 SG_ ASR_Steuerger_t : 60|1@1+ (1,0) [0|0] "" XXX
 SG_ COUNTER : 56|4@1+ (1,0) [0|15] "" XXX
 SG_ MSR_Eingriffsmoment : 48|8@1+ (0.39,0) [0|99.06] "MDI" XXX
 SG_ ASR_Eingriffsmoment_schnell : 40|8@1+ (0.39,0) [0|99.06] "MDI" XXX
 SG_ ASR_Eingriffsmoment_langsam : 32|8@1+ (0.39,0) [0|99.06] "MDI" XXX
 SG_ Geschwindigkeit_neu__Bremse_1_ : 17|15@1+ (0.01,0) [0|326.39] "km/h" XXX
 SG_ Aktiver_Bremskraftverstaerker : 16|1@1+ (1,0) [0|0] "" XXX
 SG_ ABS_in_Diagnose : 15|1@1+ (1,0) [0|0] "" XXX
 SG_ Fehlerstatus_Schlechtwegausblen : 14|1@1+ (1,0) [0|0] "" XXX
 SG_ Schlechtwegausblendung : 13|1@1+ (1,0) [0|0] "" XXX
 SG_ Fahrer_bremst__Bremse_1___4_1_ : 11|1@1+ (1,0) [0|0] "" XXX
 SG_ Bremskontroll_Lampe : 10|1@1+ (1,0) [0|0] "" XXX
 SG_ Lampe_ASR___ESP : 9|1@1+ (1,0) [0|0] "" XXX
 SG_ Lampe_ABS : 8|1@1+ (1,0) [0|0] "" XXX
 SG_ EBV_Eingriff : 7|1@1+ (1,0) [0|0] "" XXX
 SG_ ASR_Schaltbeeinflussung : 5|2@1+ (1,0) [0|0] "" XXX
 SG_ ESP_Eingriff : 4|1@1+ (1,0) [0|0] "" XXX
 SG_ EDS_Eingriff : 3|1@1+ (1,0) [0|0] "" XXX
 SG_ ABS_Bremsung__4_1_ : 2|1@1+ (1,0) [0|0] "" XXX
 SG_ MSR_Anforderung : 1|1@1+ (1,0) [0|0] "" XXX
 SG_ ASR_Anforderung : 0|1@1+ (1,0) [0|0] "" XXX

BO_ 680 Bremsbooster_1: 3 XXX
 SG_ Fehlerspeichereintrag_Booster : 23|1@1+ (1,0) [0|0] "" XXX
 SG_ Loseschalter_unplausibel_Boost : 22|1@1+ (1,0) [0|0] "" XXX
 SG_ Position_Standby : 21|1@1+ (1,0) [0|0] "" XXX
 SG_ ADR_Relais_ge_ffnet : 20|1@1+ (1,0) [0|0] "" XXX
 SG_ Status_Bremsbooster_Steuerung : 19|1@1+ (1,0) [0|0] "" XXX
 SG_ Bremsbooster_verf_gbar : 18|1@1+ (1,0) [0|0] "" XXX
 SG_ Eingriff_Bremsbooster : 17|1@1+ (1,0) [0|0] "" XXX
 SG_ Bremseingriff_Fahrer : 16|1@1+ (1,0) [0|0] "" XXX
 SG_ Frei_Bremsbooster_1_1 : 12|4@1+ (1,0) [0|0] "" XXX
 SG_ Zaehler_Booster_1 : 8|4@1+ (1,0) [0|15] "" XXX
 SG_ Checksumme_Booster_1 : 0|8@1+ (1,0) [0|0] "" XXX

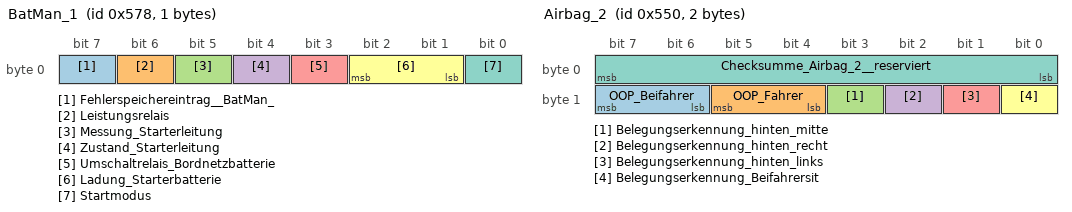
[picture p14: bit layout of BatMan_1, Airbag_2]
BO_ 1400 BatMan_1: 1 XXX
 SG_ Fehlerspeichereintrag__BatMan_ : 7|1@1+ (1,0) [0|0] "" XXX
 SG_ Leistungsrelais : 6|1@1+ (1,0) [0|0] "" XXX
 SG_ Messung_Starterleitung : 5|1@1+ (1,0) [0|0] "" XXX
 SG_ Zustand_Starterleitung : 4|1@1+ (1,0) [0|0] "" XXX
 SG_ Umschaltrelais_Bordnetzbatterie : 3|1@1+ (1,0) [0|0] "" XXX
 SG_ Ladung_Starterbatterie : 1|2@1+ (1,0) [0|0] "" XXX
 SG_ Startmodus : 0|1@1+ (1,0) [0|0] "" XXX

BO_ 704 Allrad_1: 5 XXX
 SG_ Kupplungssteifigkeit_Hinten__Is : 32|8@1+ (0.7874,0) [0|100] "%" XXX
 SG_ Fehlerspeichereintrag_Allrad_1 : 31|1@1+ (1,0) [0|0] "" XXX
 SG_ Frei_Allrad_1_1 : 26|5@1+ (1,0) [0|0] "" XXX
 SG_ Schaltung_Vorwarnung : 25|1@1+ (1,0) [0|0] "" XXX
 SG_ Schaltung_aktiv__Allrad_1_ : 24|1@1+ (1,0) [0|0] "" XXX
 SG_ Ganginfo__PNG_ : 20|4@1+ (1,0) [0|0] "" XXX
 SG_ PNG_Anzeige_blinkend : 19|1@1+ (1,0) [0|0] "" XXX
 SG_ PNG_Status_4_1 : 16|3@1+ (1,0) [0|0] "" XXX
 SG_ Kupplungssteifigkeit_Mitte__Ist : 8|8@1+ (3,-381) [-381|378] "Nm/min" XXX
 SG_ Einheit_der_Kupplungssteifigkei : 7|1@1+ (1,0) [0|0] "" XXX
 SG_ Geschwindigkeitsbegrenzung : 6|1@1+ (1,0) [0|0] "" XXX
 SG_ Allrad_Warnlampe : 5|1@1+ (1,0) [0|0] "" XXX
 SG_ Notlauf : 4|1@1+ (1,0) [0|0] "" XXX
 SG_ Kupplung_komplett_offen : 3|1@1+ (1,0) [0|0] "" XXX
 SG_ Fehlerstatus_Kupplungssteifigke : 2|1@1+ (1,0) [0|0] "" XXX
 SG_ Ubertemperaturschutz__Allrad_1_ : 1|1@1+ (1,0) [0|0] "" XXX
 SG_ Fehler_Allrad_Kupplung : 0|1@1+ (1,0) [0|0] "" XXX

BO_ 1360 Airbag_2: 2 XXX
 SG_ OOP_Beifahrer : 14|2@1+ (1,0) [0|0] "" XXX
 SG_ OOP_Fahrer : 12|2@1+ (1,0) [0|0] "" XXX
 SG_ Belegungserkennung_hinten_mitte : 11|1@1+ (1,0) [0|0] "" XXX
 SG_ Belegungserkennung_hinten_recht : 10|1@1+ (1,0) [0|0] "" XXX
 SG_ Belegungserkennung_hinten_links : 9|1@1+ (1,0) [0|0] "" XXX
 SG_ Belegungserkennung_Beifahrersit : 8|1@1+ (1,0) [0|0] "" XXX
 SG_ Checksumme_Airbag_2__reserviert : 0|8@1+ (1,0) [0|0] "" XXX

BO_ 80 Airbag_1: 4 XXX
 SG_ CHECKSUM : 24|8@1+ (1,0) [0|0] "" XXX
 SG_ COUNTER : 20|4@1+ (1,0) [0|15] "" XXX
 SG_ Fehlerspeichereintrag : 19|1@1+ (1,0) [0|0] "" XXX
 SG_ Frei_Airbag_1_2 : 18|1@1+ (1,0) [0|0] "" XXX
 SG_ Airbag_im_Stellgliedtest : 17|1@1+ (1,0) [0|0] "" XXX
 SG_ Airbag_in_Diagnose : 16|1@1+ (1,0) [0|0] "" XXX
 SG_ Gurtwarnung_Beifahrer : 15|1@1+ (1,0) [0|0] "" XXX
 SG_ Gurtschalter_Beifahrer : 14|1@1+ (1,0) [0|0] "" XXX
 SG_ Gurtwarnung_Fahrer : 13|1@1+ (1,0) [0|0] "" XXX
 SG_ Gurtschalter_Fahrer : 12|1@1+ (1,0) [0|0] "" XXX
 SG_ Airbag_Systemfehler : 11|1@1+ (1,0) [0|0] "" XXX
 SG_ Kindersitzerkennung : 10|1@1+ (1,0) [0|0] "" XXX
 SG_ Airbag_deaktiviert : 9|1@1+ (1,0) [0|0] "" XXX
 SG_ Airbag_Lampe : 8|1@1+ (1,0) [0|0] "" XXX
 SG_ Crash_Intensitaet : 5|3@1+ (1,0) [0|111] "B" XXX
 SG_ Rollover : 4|1@1+ (1,0) [0|0] "" XXX
 SG_ Seiten_Crash_Beifahrer : 3|1@1+ (1,0) [0|0] "" XXX
 SG_ Seiten_Crash_Fahrer : 2|1@1+ (1,0) [0|0] "" XXX
 SG_ Heck_Crash : 1|1@1+ (1,0) [0|0] "" XXX
 SG_ Front_Crash : 0|1@1+ (1,0) [0|0] "" XXX

BO_ 864 ADR_System: 8 XXX
 SG_ S_Checksumme_ADR_1 : 56|8@1+ (1,0) [0|0] "" XXX
 SG_ S_Frei_ADR_1_1 : 52|4@1+ (1,0) [0|0] "" XXX
 SG_ S_Zeitluecke_gemessen : 48|4@1+ (1,0) [0|15] "" XXX
 SG_ S_Fehlerspeichereintrag_ADR : 47|1@1+ (1,0) [0|0] "" XXX
 SG_ S_Fehlerspeichereintrag_Bremsbo : 46|1@1+ (1,0) [0|0] "" XXX
 SG_ S_ADR_Relais_geoeffnet : 45|1@1+ (1,0) [0|0] "" XXX
 SG_ S_Bremsbooster_Status : 43|2@1+ (1,0) [0|0] "" XXX
 SG_ S_Eingriff_Bremsbooster : 42|1@1+ (1,0) [0|0] "" XXX
 SG_ S_Loeseschalter_unplausibel : 41|1@1+ (1,0) [0|0] "" XXX
 SG_ S_Bremseingriff_Fahrer : 40|1@1+ (1,0) [0|0] "" XXX
 SG_ S_Anzeige_Sensor_blind : 39|1@1+ (1,0) [0|0] "" XXX
 SG_ S_Ansteuerung_optischer_Fahrerh : 38|1@1+ (1,0) [0|0] "" XXX
 SG_ S_Ansteuerung_Gong_2 : 37|1@1+ (1,0) [0|0] "" XXX
 SG_ S_Ansteuerung_Gong_1 : 36|1@1+ (1,0) [0|0] "" XXX
 SG_ S_Schaltaufforderung : 34|2@1+ (1,0) [0|0] "" XXX
 SG_ S_Anzeige_Prioritaet : 33|1@1+ (1,0) [0|0] "" XXX
 SG_ S_Anzeige_Zeitluecke : 32|1@1+ (1,0) [0|0] "" XXX
 SG_ S_Wunschgeschwindigkeit : 24|8@1+ (1,0) [0|254] "km/h" XXX
 SG_ S_Objekt_erfasst : 22|2@1+ (1,0) [0|0] "" XXX
 SG_ S_Gesetzte_Zeitluecke__ADR_1_ : 18|4@1+ (1,0) [0|15] "" XXX
 SG_ S_Synchronisation_Bremsbooster : 17|1@1+ (1,0) [0|0] "" XXX
 SG_ S_Momentenanforderung_Freigabe : 16|1@1+ (1,0) [0|0] "" XXX
 SG_ S_Verhinderung_Schubabschaltung : 15|1@1+ (1,0) [0|0] "" XXX
 SG_ S_Status_ADR_1__S_ : 13|2@1+ (1,0) [0|0] "" XXX
 SG_ S_Fehler_ADR_1__S_ : 12|1@1+ (1,0) [0|0] "" XXX
 SG_ S_Zaehler_ADR_1 : 8|4@1+ (1,0) [0|15] "" XXX
 SG_ S_Momentenanforderung_ADR : 0|8@1+ (0.39,0) [0|99] "MDI" XXX

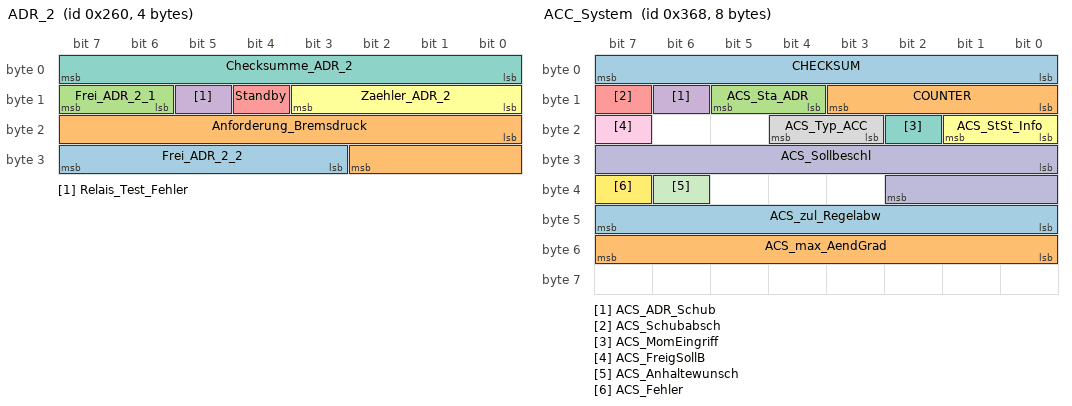
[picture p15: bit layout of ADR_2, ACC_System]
BO_ 608 ADR_2: 4 XXX
 SG_ Frei_ADR_2_2 : 27|5@1+ (1,0) [0|0] "" XXX
 SG_ Anforderung_Bremsdruck : 16|11@1+ (0.0625,0) [0|127.9375] "bar" XXX
 SG_ Frei_ADR_2_1 : 14|2@1+ (1,0) [0|0] "" XXX
 SG_ Relais_Test_Fehler : 13|1@1+ (1,0) [0|0] "" XXX
 SG_ Standby : 12|1@1+ (1,0) [0|0] "" XXX
 SG_ Zaehler_ADR_2 : 8|4@1+ (1,0) [0|15] "" XXX
 SG_ Checksumme_ADR_2 : 0|8@1+ (1,0) [0|0] "" XXX

BO_ 1324 ADR_1: 8 XXX
 SG_ Checksumme_ADR_1 : 56|8@1+ (1,0) [0|0] "" XXX
 SG_ Frei_ADR_1_5 : 52|4@1+ (1,0) [0|0] "" XXX
 SG_ Zeitluecke_gemessen : 48|4@1+ (1,0) [0|15] "" XXX
 SG_ Fehlerspeichereintrag_ADR : 47|1@1+ (1,0) [0|0] "" XXX
 SG_ Reserviert_ADR_1_1 : 40|7@1+ (1,0) [0|0] "" XXX
 SG_ Anzeige_Sensor_blind : 39|1@1+ (1,0) [0|0] "" XXX
 SG_ Ansteuerung_optischer_Fahrerhin : 38|1@1+ (1,0) [0|0] "" XXX
 SG_ Ansteuerung_Gong_2 : 37|1@1+ (1,0) [0|0] "" XXX
 SG_ Ansteuerung_Gong_1 : 36|1@1+ (1,0) [0|0] "" XXX
 SG_ Schaltaufforderung : 34|2@1+ (1,0) [0|0] "" XXX
 SG_ Anzeige_Prioritaet : 33|1@1+ (1,0) [0|0] "" XXX
 SG_ Anzeige_Zeitluecke : 32|1@1+ (1,0) [0|0] "" XXX
 SG_ Wunschgeschwindigkeit : 24|8@1+ (1,0) [0|254] "km/h" XXX
 SG_ Objekt_erfasst : 22|2@1+ (1,0) [0|0] "" XXX
 SG_ Gesetzte_Zeitluecke__ADR_1_ : 18|4@1+ (1,0) [0|15] "" XXX
 SG_ Synchronisation_Bremsbooster : 17|1@1+ (1,0) [0|0] "" XXX
 SG_ Momentenanforderung_Freigabe : 16|1@1+ (1,0) [0|0] "" XXX
 SG_ Verhinderung_Schubabschaltung : 15|1@1+ (1,0) [0|0] "" XXX
 SG_ Status_ADR_1 : 13|2@1+ (1,0) [0|0] "" XXX
 SG_ Fehler_ADR_1 : 12|1@1+ (1,0) [0|0] "" XXX
 SG_ Zaehler_ADR_1 : 8|4@1+ (1,0) [0|15] "" XXX
 SG_ Momentenanforderung_ADR : 0|8@1+ (0.39,0) [0|99] "MDI" XXX

BO_ 1550 Einheiten_1: 2 XXX
 SG_ MFA_v_Einheit_02 : 0|1@1+ (1,0) [0|1] "" XXX

BO_ 872 ACC_System: 8 XXX
 SG_ CHECKSUM : 0|8@1+ (1,0) [0|255] "" XXX
 SG_ COUNTER : 8|4@1+ (1,0) [0|15] "" XXX
 SG_ ACS_Sta_ADR : 12|2@1+ (1,0) [0|3] "" XXX
 SG_ ACS_ADR_Schub : 14|1@1+ (1,0) [0|1] "" XXX
 SG_ ACS_Schubabsch : 15|1@1+ (1,0) [0|1] "" XXX
 SG_ ACS_StSt_Info : 16|2@1+ (1,0) [0|3] "" XXX
 SG_ ACS_MomEingriff : 18|1@1+ (1,0) [0|1] "" XXX
 SG_ ACS_Typ_ACC : 19|2@1+ (1,0) [0|3] "" XXX
 SG_ ACS_FreigSollB : 23|1@1+ (1,0) [0|1] "" XXX
 SG_ ACS_Sollbeschl : 24|11@1+ (0.005,-7.22) [-7.22|3.005] "Unit_MeterPerSeconSquar" XXX
 SG_ ACS_Anhaltewunsch : 38|1@1+ (1,0) [0|1] "" XXX
 SG_ ACS_Fehler : 39|1@1+ (1,0) [0|1] "" XXX
 SG_ ACS_zul_Regelabw : 40|8@1+ (0.005,0) [0|1.265] "Unit_MeterPerSeconSquar" XXX
 SG_ ACS_max_AendGrad : 48|8@1+ (0.02,0) [0.02|5.06] "Unit_MeterPerSeconSquar" XXX

BO_ 1386 ACC_GRA_Anzeige: 8 XXX
 SG_ CHECKSUM : 0|8@1+ (1,0) [0|255] "" XXX
 SG_ ACA_StaACC : 8|3@1+ (1,0) [0|7] "" XXX
 SG_ ACA_ID_StaACC : 11|5@1+ (1,0) [0|31] "" XXX
 SG_ ACA_Fahrerhinw : 16|1@1+ (1,0) [0|1] "" XXX
 SG_ ACA_AnzDisplay : 17|1@1+ (1,0) [0|1] "" XXX
 SG_ ACA_Zeitluecke : 18|4@1+ (1,0) [0|15] "" XXX
 SG_ ACA_V_Wunsch : 24|8@1+ (1,0) [0|255] "Unit_KiloMeterPerHour" XXX
 SG_ ACA_kmh_mph : 32|1@1+ (1,0) [0|1] "" XXX
 SG_ ACA_Akustik1 : 33|1@1+ (1,0) [0|1] "" XXX
 SG_ ACA_Akustik2 : 34|1@1+ (1,0) [0|1] "" XXX
 SG_ ACA_PrioDisp : 35|2@1+ (1,0) [0|3] "" XXX
 SG_ ACA_gemZeitl : 40|4@1+ (1,0) [0|15] "" XXX
 SG_ ACA_ACC_Verz : 44|1@1+ (1,0) [0|1] "" XXX
 SG_ ACA_StaGRA : 48|3@1+ (1,0) [0|7] "" XXX
 SG_ ACA_ID_StaGRA : 51|5@1+ (1,0) [0|31] "" XXX
 SG_ ACA_Codierung : 56|1@1+ (1,0) [0|1] "" XXX
 SG_ ACA_Tachokranz : 57|1@1+ (1,0) [0|1] "" XXX
 SG_ ACA_Aend_Zeitluecke : 58|1@1+ (1,0) [0|1] "" XXX
 SG_ COUNTER : 60|4@1+ (1,0) [0|15] "" XXX

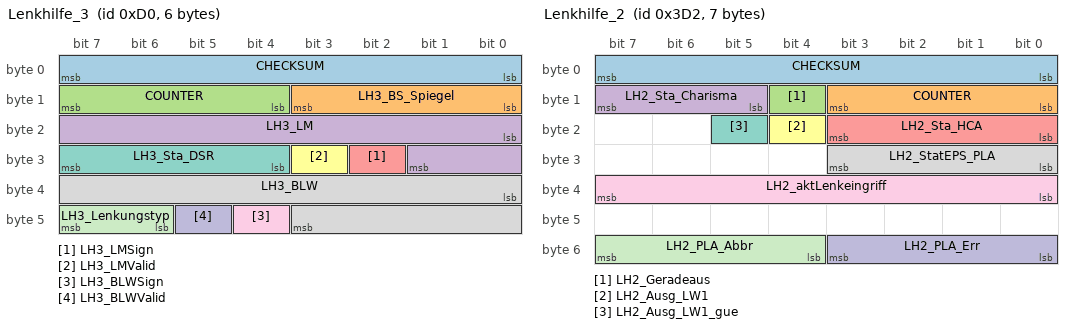
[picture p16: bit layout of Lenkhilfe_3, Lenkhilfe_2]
BO_ 208 Lenkhilfe_3: 6 XXX
 SG_ CHECKSUM : 0|8@1+ (1,0) [0|255] "" XXX
 SG_ LH3_BS_Spiegel : 8|4@1+ (1,0) [0|15] "" XXX
 SG_ COUNTER : 12|4@1+ (1,0) [0|15] "" XXX
 SG_ LH3_LM : 16|10@1+ (1,0) [0|1023] "" XXX
 SG_ LH3_LMSign : 26|1@1+ (1,0) [0|1] "" XXX
 SG_ LH3_LMValid : 27|1@1+ (1,0) [0|1] "" XXX
 SG_ LH3_Sta_DSR : 28|4@1+ (1,0) [0|15] "" XXX
 SG_ LH3_BLW : 32|12@1+ (0.15,0) [0|615] "" XXX
 SG_ LH3_BLWSign : 44|1@1+ (1,0) [0|1] "" XXX
 SG_ LH3_BLWValid : 45|1@1+ (1,0) [0|1] "" XXX
 SG_ LH3_Lenkungstyp : 46|2@1+ (1,0) [0|3] "" XXX

BO_ 978 Lenkhilfe_2: 7 XXX
 SG_ CHECKSUM : 0|8@1+ (1,0) [0|255] "" XXX
 SG_ COUNTER : 8|4@1+ (1,0) [0|15] "" XXX
 SG_ LH2_Geradeaus : 12|1@1+ (1,0) [0|1] "" XXX
 SG_ LH2_Sta_Charisma : 13|3@1+ (1,0) [0|7] "" XXX
 SG_ LH2_Sta_HCA : 16|4@1+ (1,0) [0|15] "" XXX
 SG_ LH2_Ausg_LW1 : 20|1@1+ (1,0) [0|1] "" XXX
 SG_ LH2_Ausg_LW1_gue : 21|1@1+ (1,0) [0|1] "" XXX
 SG_ LH2_StatEPS_PLA : 24|4@1+ (1,0) [0|15] "" XXX
 SG_ LH2_aktLenkeingriff : 32|8@1+ (1,0) [0|255] "" XXX
 SG_ LH2_PLA_Err : 48|4@1+ (1,0) [0|15] "" XXX
 SG_ LH2_PLA_Abbr : 52|4@1+ (1,0) [0|15] "" XXX

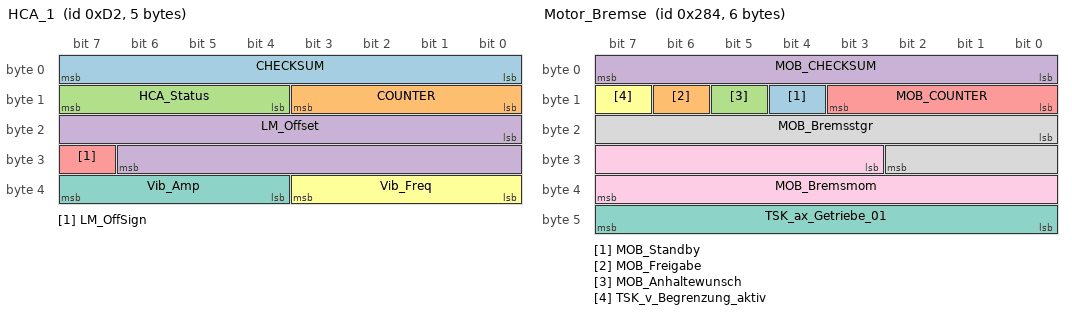
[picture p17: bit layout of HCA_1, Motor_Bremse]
BO_ 210 HCA_1: 5 XXX
 SG_ CHECKSUM : 0|8@1+ (1,0) [0|15] "" XXX
 SG_ COUNTER : 8|4@1+ (1,0) [0|15] "" XXX
 SG_ HCA_Status : 12|4@1+ (1,0) [0|15] "" XXX
 SG_ LM_Offset : 16|15@1+ (0.03125,0) [0|300] "cNm" XXX
 SG_ LM_OffSign : 31|1@1+ (1,0) [0|1] "" XXX
 SG_ Vib_Freq : 32|4@1+ (4,0) [0|60] "Hz" XXX
 SG_ Vib_Amp : 36|4@1+ (0.5,0) [0|7.5] "Nm" XXX

BO_ 644 Motor_Bremse: 6 XXX
 SG_ MOB_Standby : 12|1@1+ (1,0) [0|1] ""  XXX
 SG_ MOB_Freigabe : 14|1@1+ (1,0) [0|1] "" BCM_Gateway,Bremse_MK25AESP,Gateway_separat
 SG_ MOB_Anhaltewunsch : 13|1@1+ (1,0) [0|1] "" Bremse_MK25AESP,Getriebe_DQ
 SG_ MOB_CHECKSUM : 0|8@1+ (1,0) [0|255] "" Bremse_MK25AESP
 SG_ MOB_COUNTER : 8|4@1+ (1,0) [0|15] "" Bremse_MK25AESP
 SG_ TSK_v_Begrenzung_aktiv : 15|1@0+ (1,0) [0|1] "" XXX
 SG_ TSK_ax_Getriebe_01 : 40|8@1+ (0.048,0) [0|255] "m/s2" XXX
 SG_ MOB_Bremsstgr : 16|11@1+ (0.048852,0) [0|100] "Unit_PerCent" Vector__XXX
 SG_ MOB_Bremsmom : 27|13@1+ (4,0) [0|32760] "Unit_NewtoMeter"  Bremse_MK25AESP

BO_ 870 AWV: 8 XXX
 SG_ CHECKSUM : 0|8@1+ (1,0) [0|255] "" Vector__XXX
 SG_ COUNTER : 8|4@1+ (1,0) [0|15] "" Vector__XXX
 SG_ AWV_Text : 12|4@1+ (1,0) [0|14] "" Vector__XXX
 SG_ AWV_1_Freigabe : 16|1@1+ (1,0) [0|1] "" Vector__XXX
 SG_ AWV_1_Prefill : 17|1@1+ (1,0) [0|1] "" Vector__XXX
 SG_ AWV_1_Parameter : 18|2@1+ (1,0) [0|3] "" Vector__XXX
 SG_ AWV_only : 20|1@1+ (1,0) [0|1] "" Vector__XXX
 SG_ AWV_CityANB_Auspraegung : 21|1@1+ (1,0) [0|1] "" Vector__XXX
 SG_ AWV_Halten : 22|1@1+ (1,0) [0|1] "" Vector__XXX
 SG_ ANB_Teilbremsung_Freigabe : 23|1@1+ (1,0) [0|1] "" Vector__XXX
 SG_ AWV_2_Status : 24|1@1+ (1,0) [0|1] "" Vector__XXX
 SG_ AWV_2_Fehler : 25|1@1+ (1,0) [0|1] "" Vector__XXX
 SG_ AWV_2_SU_Warnzeit : 26|2@1+ (1,0) [0|3] "" Vector__XXX
 SG_ AWV_2_SU_Bremsruck : 28|1@1+ (1,0) [0|1] "" Vector__XXX
 SG_ AWV_2_SU_Gong : 29|1@1+ (1,0) [0|1] "" Vector__XXX
 SG_ AWV_2_SU_Lampe : 30|1@1+ (1,0) [0|1] "" Vector__XXX
 SG_ AWV_2_Umfeldwarn : 31|1@1+ (1,0) [0|1] "" Vector__XXX
 SG_ AWV_2_Freigabe : 32|1@1+ (1,0) [0|1] "" Vector__XXX
 SG_ AWV_2_Ruckprofil : 33|3@1+ (1,0) [0|7] "" Vector__XXX
 SG_ AWV_2_Warnton : 36|1@1+ (1,0) [0|1] "" Vector__XXX
 SG_ AWV_2_Warnsymbol : 37|1@1+ (1,0) [0|1] "" Vector__XXX
 SG_ AWV_Infoton : 38|1@1+ (1,0) [0|1] "" Vector__XXX
 SG_ AWV_2_Gurtstraffer : 39|1@1+ (1,0) [0|1] "" Vector__XXX
 SG_ AWV_Konfiguration_Menueanf : 40|1@1+ (1,0) [0|1] "" Vector__XXX
 SG_ AWV_Konfiguration_Vorw_Menueanf : 41|1@1+ (1,0) [0|1] "" Vector__XXX
 SG_ AWV_Konfiguration_Status : 42|1@1+ (1,0) [0|1] "" Vector__XXX
 SG_ AWV_Konfiguration_Vorw_Status : 43|1@1+ (1,0) [0|1] "" Vector__XXX
 SG_ AWV_2_Abstandswarnung : 51|1@1+ (1,0) [0|1] "" Vector__XXX
 SG_ ANB_Zielbremsung_Freigabe : 52|1@1+ (1,0) [0|1] "" Vector__XXX
 SG_ ANB_CM_Anforderung : 53|1@1+ (1,0) [0|1] "" Vector__XXX
 SG_ ANB_Ziel_Teilbrems_Verz_Anf : 54|10@1+ (0.024,-20.016) [0|1023] "Unit_MeterPerSeconSquar" Vector__XXX

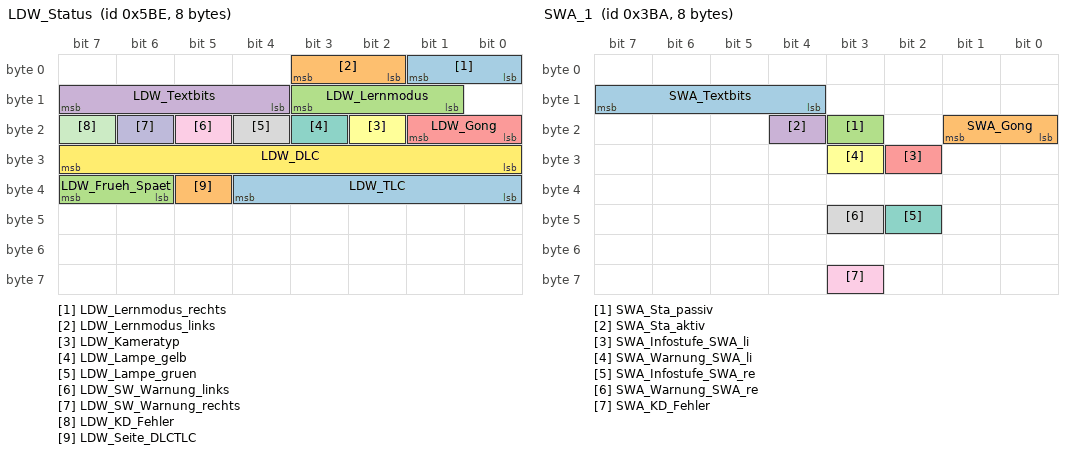
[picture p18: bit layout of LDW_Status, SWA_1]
BO_ 1470 LDW_Status: 8 XXX
 SG_ LDW_Lernmodus_rechts : 0|2@1+ (1,0) [0|3] "" XXX
 SG_ LDW_Lernmodus_links : 2|2@1+ (1,0) [0|3] "" XXX
 SG_ LDW_Lernmodus : 9|3@1+ (1,0) [0|3] "" XXX
 SG_ LDW_Textbits : 12|4@1+ (1,0) [0|15] "" XXX
 SG_ LDW_Gong : 16|2@1+ (1,0) [0|3] "" XXX
 SG_ LDW_Kameratyp : 18|1@1+ (1,0) [0|1] "" XXX
 SG_ LDW_Lampe_gelb : 19|1@1+ (1,0) [0|1] "" XXX
 SG_ LDW_Lampe_gruen : 20|1@1+ (1,0) [0|1] "" XXX
 SG_ LDW_SW_Warnung_links : 21|1@1+ (1,0) [0|1] "" XXX
 SG_ LDW_SW_Warnung_rechts : 22|1@1+ (1,0) [0|1] "" XXX
 SG_ LDW_KD_Fehler : 23|1@1+ (1,0) [0|1] "" XXX
 SG_ LDW_DLC : 24|8@1+ (0.01,-1.25) [-1.25|1.25] "" XXX
 SG_ LDW_TLC : 32|5@1+ (0.1,0) [0|3] "" XXX
 SG_ LDW_Seite_DLCTLC : 37|1@1+ (1,0) [0|1] "" XXX
 SG_ LDW_Frueh_Spaet : 38|2@1+ (1,0) [0|3] "" XXX

BO_ 428 Bremse_8: 8 XXX
 SG_ BR8_Checksumme : 0|8@1+ (1,0) [0|255] "" XXX
 SG_ BR8_Zaehler : 8|4@1+ (1,0) [0|15] "" XXX
 SG_ BR8_Sta_ACC_Anf : 12|1@1+ (1,0) [0|1] "" XXX
 SG_ BR8_Verz_EPB_akt : 13|1@1+ (1,0) [0|1] "" XXX
 SG_ BR8_Sta_Br_temp : 14|1@1+ (1,0) [0|1] "" XXX
 SG_ BR8_Sta_Br_Druck : 15|1@1+ (1,0) [0|1] "" XXX
 SG_ BR8_TolAbgl_HL : 16|8@1+ (0.048828125,-6.201171875) [-6.201171875|6.15234375] "Unit_PerCent" XXX
 SG_ BR8_TolAbgl_HR : 24|8@1+ (0.048828125,-6.201171875) [-6.201171875|6.15234375] "Unit_PerCent" XXX
 SG_ BR8_Istbeschl : 32|9@1+ (0.02,-7.22) [-7.22|2.98] "Unit_MeterPerSeconSquar"  XXX
 SG_ BR8_Sta_HW_BLS : 41|1@1+ (1,0) [0|1] "" XXX
 SG_ BR8_QB_LBeschl : 42|1@1+ (1,0) [0|1] "" XXX
 SG_ BR8_ESC_Mode : 43|2@1+ (1,0) [0|3] "" XXX
 SG_ BR8_aktBrSyst : 45|1@1+ (1,0) [0|1] "" XXX
 SG_ BR8_Fa_bremst : 46|1@1+ (1,0) [0|1] "" XXX
 SG_ BR8_StaBrSyst : 47|1@1+ (1,0) [0|1] "" XXX
 SG_ BR8_Laengsbeschl : 48|10@1+ (0.03125,-16) [-15.96875|15.9375] "Unit_MeterPerSeconSquar" XXX
 SG_ BR8_Sta_ADR_BR : 58|1@1+ (1,0) [0|1] "" XXX
 SG_ BR8_Quattro : 59|1@1+ (1,0) [0|1] "" XXX
 SG_ BR8_Sta_VerzReg : 60|1@1+ (1,0) [0|1] "" XXX
 SG_ BR8_Sta_BLS : 61|1@1+ (1,0) [0|1] "" XXX
 SG_ BR8_Verz_EPB : 62|1@1+ (1,0) [0|1] "" XXX
 SG_ BR8_Check_EPB : 63|1@1+ (1,0) [0|1] "" XXX

BO_ 928 Bremse_10: 8 XXX
 SG_ B10_Checksumme : 0|8@1+ (1,0) [0|255] "" XXX
 SG_ B10_Zaehler : 8|4@1+ (1,0) [0|15] "" XXX
 SG_ B10_QB_Wegimp_VL : 12|1@1+ (1,0) [0|1] "" XXX
 SG_ B10_QB_Wegimp_VR : 13|1@1+ (1,0) [0|1] "" XXX
 SG_ B10_QB_Wegimp_HL : 14|1@1+ (1,0) [0|1] "" XXX
 SG_ B10_QB_Wegimp_HR : 15|1@1+ (1,0) [0|1] "" XXX
 SG_ B10_Wegimp_VL : 16|10@1+ (1,0) [0|1000] "" XXX
 SG_ B10_Wegimp_VR : 26|10@1+ (1,0) [0|1000] "" XXX
 SG_ B10_Wegimp_HL : 36|10@1+ (1,0) [0|1000] "" XXX
 SG_ B10_Wegimp_HR : 46|10@1+ (1,0) [0|1000] "" XXX
 SG_ B10_QB_Fahrtr_VL : 56|1@1+ (1,0) [0|1] "" XXX
 SG_ B10_QB_Fahrtr_VR : 57|1@1+ (1,0) [0|1] "" XXX
 SG_ B10_QB_Fahrtr_HL : 58|1@1+ (1,0) [0|1] "" XXX
 SG_ B10_QB_Fahrtr_HR : 59|1@1+ (1,0) [0|1] "" XXX
 SG_ B10_Fahrtr_VL : 60|1@1+ (1,0) [0|1] "" XXX
 SG_ B10_Fahrtr_VR : 61|1@1+ (1,0) [0|1] "" XXX
 SG_ B10_Fahrtr_HL : 62|1@1+ (1,0) [0|1] "" XXX
 SG_ B10_Fahrtr_HR : 63|1@1+ (1,0) [0|1] "" XXX

BO_ 835 RDK_Status: 3 XXX
 SG_ RKS_Reifen_VL : 0|1@1+ (1,0) [0|1] "" XXX
 SG_ RKS_Reifen_VR : 1|1@1+ (1,0) [0|1] "" XXX
 SG_ RKS_Reifen_HL : 2|1@1+ (1,0) [0|1] "" XXX
 SG_ RKS_Reifen_HR : 3|1@1+ (1,0) [0|1] "" XXX
 SG_ RKS_Reifen_RR : 4|1@1+ (1,0) [0|1] "" XXX
 SG_ RKS_Warnung_2 : 5|1@1+ (1,0) [0|1] "" XXX
 SG_ RKS_Warnung_1 : 6|1@1+ (1,0) [0|1] "" XXX
 SG_ RKS_Systemfehler : 7|1@1+ (1,0) [0|1] "" XXX
 SG_ RKS_Kalibrier_abgew : 8|1@1+ (1,0) [0|1] "" XXX
 SG_ RKS_Druckdiff_Vorn : 9|1@1+ (1,0) [0|1] "" XXX
 SG_ RKS_Druckdiff_Hinten : 10|1@1+ (1,0) [0|1] "" XXX
 SG_ RKS_Befuellung_RR_low : 11|1@1+ (1,0) [0|1] "" XXX
 SG_ RKS_Funkstoerung : 12|1@1+ (1,0) [0|1] "" XXX
 SG_ RKS_System_Aus : 13|1@1+ (1,0) [0|1] "" XXX
 SG_ RKS_KD_Fehler : 15|1@1+ (1,0) [0|1] "" XXX
 SG_ RKS_Lampe : 16|1@1+ (1,0) [0|1] "" XXX
 SG_ RKS_Ton : 17|1@1+ (1,0) [0|1] "" XXX
 SG_ RKS_Gong : 18|1@1+ (1,0) [0|1] "" XXX
 SG_ RKS_RDK_Blinkbit : 19|1@1+ (1,0) [0|1] "" XXX
 SG_ RKS_Teillast : 20|1@1+ (1,0) [0|1] "" XXX

BO_ 914 Gate_Komf_2: 8 XXX
 SG_ GK2_Sta_LSM : 0|1@1+ (1,0) [0|1] "" XXX
 SG_ GK2_Sta_Lichtsensor : 1|1@1+ (1,0) [0|1] "" XXX
 SG_ GK2_Sta_Licht1 : 2|1@1+ (1,0) [0|1] "" XXX
 SG_ GK2_Sta_VSG : 3|1@1+ (1,0) [0|1] "" XXX
 SG_ GK2_Sta_Schluessel : 4|1@1+ (1,0) [0|1] "" XXX
 SG_ GK2_Sta_Profil : 5|1@1+ (1,0) [0|1] "" XXX
 SG_ GK2_Sta_Clima2 : 6|1@1+ (1,0) [0|1] "" XXX
 SG_ GK2_Sta_BSG4 : 7|1@1+ (1,0) [0|1] "" XXX
 SG_ GK2_Sta_Kessy_4 : 8|1@1+ (1,0) [0|1] "" XXX
 SG_ BS4_Gleitende_Leuchtw_Anf : 9|1@1+ (1,0) [0|1] "" XXX
 SG_ BS4_GLW_Fernlicht_Anf : 10|1@1+ (1,0) [0|1] "" XXX
 SG_ GK2_Blk_L_Kontrolle : 11|1@1+ (1,0) [0|1] "" XXX
 SG_ GK2_Blk_R_Kontrolle : 12|1@1+ (1,0) [0|1] "" XXX
 SG_ GK2_LS_KomFehler : 14|1@1+ (1,0) [0|1] "" XXX
 SG_ GK2_LS_def : 15|1@1+ (1,0) [0|1] "" XXX
 SG_ GK2_Helligkeit : 16|3@1+ (714.286,0) [0|5000.002] "Unit_Lux" XXX
 SG_ GK2_VD_zu_ver : 19|1@1+ (1,0) [0|1] "" XXX
 SG_ GK2_VD_entriegelt : 20|1@1+ (1,0) [0|1] "" XXX
 SG_ GK2_VD_offen_ver : 21|1@1+ (1,0) [0|1] "" XXX
 SG_ GK2_Verdeck_Anf : 22|1@1+ (1,0) [0|1] "" XXX
 SG_ GK2_VDKD_auf : 23|1@1+ (1,0) [0|1] "" XXX
 SG_ GK2_Schluessel : 24|4@1+ (1,0) [0|15] "" XXX
 SG_ GK2_Hardtop : 28|1@1+ (1,0) [0|1] "" XXX
 SG_ GK2_AFL_Schalter : 29|1@1+ (1,0) [0|1] "" XXX
 SG_ GK2_Nebelschluss : 30|1@1+ (1,0) [0|1] "" XXX
 SG_ GK2_EM_LIN_ungueltig : 31|1@1+ (1,0) [0|1] "" XXX
 SG_ GK2_Profil : 32|4@1+ (1,0) [0|15] "" XXX
 SG_ GK2_Kl_StSt_Info : 36|2@1+ (1,0) [0|3] "" XXX
 SG_ GK2_BSG_StSt_Info : 38|2@1+ (1,0) [0|3] "" XXX
 SG_ GK2_BEM_P_Generator : 40|8@1+ (50,0) [0|12700] "Unit_Watt" XXX
 SG_ GK2_BEM_Abschaltstufen : 48|3@1+ (1,0) [0|7] "" XXX
 SG_ GK2_BEM_DFM : 51|5@1+ (3.225,0.025) [0.025|100] "Unit_PerCent" XXX
 SG_ GK2_Kessy_StSt_Info : 56|2@1+ (1,0) [0|3] "" XXX
 SG_ GK2_BEM_StSt_Info : 58|2@1+ (1,0) [0|3] "" XXX

BO_ 954 SWA_1: 8 SWA
 SG_ SWA_Textbits : 12|4@1+ (1,0) [0|15] ""  XXX
 SG_ SWA_Gong : 16|2@1+ (1,0) [0|3] ""  XXX
 SG_ SWA_Sta_passiv : 19|1@1+ (1,0) [0|1] ""  XXX
 SG_ SWA_Sta_aktiv : 20|1@1+ (1,0) [0|1] ""  XXX
 SG_ SWA_Infostufe_SWA_li : 26|1@1+ (1,0) [0|1] ""  XXX
 SG_ SWA_Warnung_SWA_li : 27|1@1+ (1,0) [0|1] ""  XXX
 SG_ SWA_Infostufe_SWA_re : 42|1@1+ (1,0) [0|1] ""  XXX
 SG_ SWA_Warnung_SWA_re : 43|1@1+ (1,0) [0|1] ""  XXX
 SG_ SWA_KD_Fehler : 59|1@1+ (1,0) [0|1] ""  XXX

BO_ 1175 Parkhilfe_01: 8 XXX
 SG_ PH_Abschaltursache : 13|3@1+ (1,0) [0|7] "" XXX
 SG_ PH_Opt_Anzeige_V_ein : 16|1@1+ (1,0) [0|1] "" XXX
 SG_ PH_Opt_Anzeige_H_ein : 17|1@1+ (1,0) [0|1] "" XXX
 SG_ PH_Opt_Anz_V_Hindernis : 18|1@1+ (1,0) [0|1] "" XXX
 SG_ PH_Opt_Anz_H_Hindernis : 19|1@1+ (1,0) [0|1] "" XXX
 SG_ PH_Tongeber_V_aktiv : 20|1@1+ (1,0) [0|1] "" XXX
 SG_ PH_Tongeber_H_aktiv : 21|1@1+ (1,0) [0|1] "" XXX
 SG_ PH_Tongeber_mute : 22|1@1+ (1,0) [0|1] "" XXX
 SG_ PH_Anf_Audioabsenkung : 23|1@1+ (1,0) [0|1] "" XXX
 SG_ PH_Frequenz_hinten : 32|4@1+ (1,0) [0|15] "" XXX
 SG_ PH_Lautstaerke_hinten : 36|4@1+ (1,0) [0|15] "" XXX
 SG_ PH_Frequenz_vorn : 40|4@1+ (1,0) [0|15] "" XXX
 SG_ PH_Lautstaerke_vorn : 44|4@1+ (1,0) [0|15] "" XXX
 SG_ PH_Trigger_Bildaufschaltung : 48|1@1+ (1,0) [0|1] "" XXX
 SG_ PH_StartStopp_Info : 49|2@1+ (1,0) [0|3] "" XXX
 SG_ PH_Aufbauten_erk : 51|1@1+ (1,0) [0|1] "" XXX
 SG_ PH_BerErk_vorn : 52|2@1+ (1,0) [0|3] "" XXX
 SG_ PH_BerErk_hinten : 54|2@1+ (1,0) [0|3] "" XXX
 SG_ PH_defekt : 56|1@1+ (1,0) [0|1] "" XXX
 SG_ PH_gestoert : 57|1@1+ (1,0) [0|1] "" XXX
 SG_ PH_Systemzustand : 58|3@1+ (1,0) [0|7] "" XXX
 SG_ PH_Display_Kundenwunsch : 61|2@1+ (1,0) [0|3] "" XXX
 SG_ PH_KD_Fehler : 63|1@1+ (1,0) [0|1] "" XXX

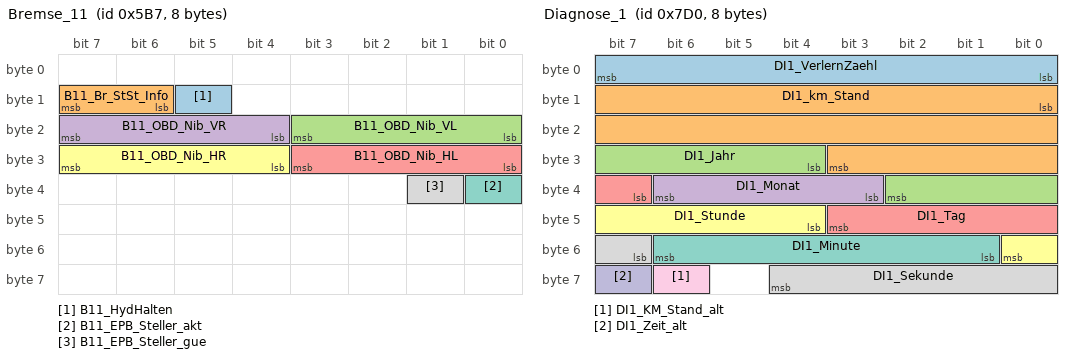
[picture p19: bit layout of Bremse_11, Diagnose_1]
BO_ 1463 Bremse_11: 8 XXX
 SG_ B11_HydHalten : 13|1@1+ (1,0) [0|1] "" XXX
 SG_ B11_Br_StSt_Info : 14|2@1+ (1,0) [0|3] "" XXX
 SG_ B11_OBD_Nib_VL : 16|4@1+ (1,0) [0|15] "" XXX
 SG_ B11_OBD_Nib_VR : 20|4@1+ (1,0) [0|15] "" XXX
 SG_ B11_OBD_Nib_HL : 24|4@1+ (1,0) [0|15] "" XXX
 SG_ B11_OBD_Nib_HR : 28|4@1+ (1,0) [0|15] "" XXX
 SG_ B11_EPB_Steller_akt : 32|1@1+ (1,0) [0|1] "" XXX
 SG_ B11_EPB_Steller_gue : 33|1@1+ (1,0) [0|1] "" XXX

BO_ 1500 Soll_Verbauliste_neu: 8 XXX
 SG_ VL1_Motor_SG : 0|1@1+ (1,0) [0|1] "" XXX
 SG_ VL1_Getr_SG : 1|1@1+ (1,0) [0|1] "" XXX
 SG_ VL1_ABS : 2|1@1+ (1,0) [0|1] "" XXX
 SG_ VL1_Kombi : 3|1@1+ (1,0) [0|1] "" XXX
 SG_ VL1_LSM : 4|1@1+ (1,0) [0|1] "" XXX
 SG_ VL1_Airbag : 5|1@1+ (1,0) [0|1] "" XXX
 SG_ VL1_Lenkhilfe : 6|1@1+ (1,0) [0|1] "" XXX
 SG_ VL1_dyn_LWR : 7|1@1+ (1,0) [0|1] "" XXX
 SG_ VL1_res_08 : 8|1@1+ (1,0) [0|1] "" XXX
 SG_ VL1_Allrad : 9|1@1+ (1,0) [0|1] "" XXX
 SG_ VL1_ADR : 10|1@1+ (1,0) [0|1] "" XXX
 SG_ VL1_ADR_getrennt : 11|1@1+ (1,0) [0|1] "" XXX
 SG_ VL1_EPB : 12|1@1+ (1,0) [0|1] "" XXX
 SG_ VL1_res_13 : 13|1@1+ (1,0) [0|1] "" XXX
 SG_ VL1_Daempfer : 14|1@1+ (1,0) [0|1] "" XXX
 SG_ VL1_Quersperre : 15|1@1+ (1,0) [0|1] "" XXX
 SG_ VL1_MotorSlave : 16|1@1+ (1,0) [0|1] "" XXX
 SG_ VL1_SWA : 17|1@1+ (1,0) [0|1] "" XXX
 SG_ VL1_HCA : 18|1@1+ (1,0) [0|1] "" XXX
 SG_ VL1_RKA_Plus : 19|1@1+ (1,0) [0|1] "" XXX
 SG_ VL1_PLA : 20|1@1+ (1,0) [0|1] "" XXX
 SG_ VL1_WFS_KBI : 21|1@1+ (1,0) [0|1] "" XXX
 SG_ VL1_Kombi_KBI : 22|1@1+ (1,0) [0|1] "" XXX
 SG_ VL1_Soll_eq_Ist : 23|1@1+ (1,0) [0|1] "" XXX
 SG_ VL1_BSG_Komf : 24|1@1+ (1,0) [0|1] "" XXX
 SG_ VL1_ZKE : 25|1@1+ (1,0) [0|1] "" XXX
 SG_ VL1_TSG_FT : 26|1@1+ (1,0) [0|1] "" XXX
 SG_ VL1_TSG_BT : 27|1@1+ (1,0) [0|1] "" XXX
 SG_ VL1_TSG_HL : 28|1@1+ (1,0) [0|1] "" XXX
 SG_ VL1_TSG_HR : 29|1@1+ (1,0) [0|1] "" XXX
 SG_ VL1_Memory : 30|1@1+ (1,0) [0|1] "" XXX
 SG_ VL1_Dachmodul_K : 31|1@1+ (1,0) [0|1] "" XXX
 SG_ VL1_Zentralelektrik_II : 32|1@1+ (1,0) [0|1] "" XXX
 SG_ VL1_RDK : 33|1@1+ (1,0) [0|1] "" XXX
 SG_ VL1_Lenksaeule : 34|1@1+ (1,0) [0|1] "" XXX
 SG_ VL1_Gateway : 35|1@1+ (1,0) [0|1] "" XXX
 SG_ VL1_Clima_Komf : 36|1@1+ (1,0) [0|1] "" XXX
 SG_ VL1_Einparkhilfe : 37|1@1+ (1,0) [0|1] "" XXX
 SG_ VL1_PTC_Heizung : 38|1@1+ (1,0) [0|1] "" XXX
 SG_ VL1_Standheiz : 39|1@1+ (1,0) [0|1] "" XXX
 SG_ VL1_Verdeck : 40|1@1+ (1,0) [0|1] "" XXX
 SG_ VL1_RSE_I : 41|1@1+ (1,0) [0|1] "" XXX
 SG_ VL1_res_42 : 42|1@1+ (1,0) [0|1] "" XXX
 SG_ VL1_MDI_I : 43|1@1+ (1,0) [0|1] "" XXX
 SG_ VL1_Anhaenger : 44|1@1+ (1,0) [0|1] ""  SWA
 SG_ VL1_Memory_BF : 45|1@1+ (1,0) [0|1] "" XXX
 SG_ VL1_Easy_Entry_VF : 46|1@1+ (1,0) [0|1] "" XXX
 SG_ VL1_Easy_Entry_VB : 47|1@1+ (1,0) [0|1] "" XXX
 SG_ VL1_Heckdeckel : 48|1@1+ (1,0) [0|1] "" XXX
 SG_ VL1_Rearview : 49|1@1+ (1,0) [0|1] "" XXX
 SG_ VL1_Sonderfzg_SG : 50|1@1+ (1,0) [0|1] "" XXX
 SG_ VL1_Tastenmodul : 51|1@1+ (1,0) [0|1] "" XXX
 SG_ VL1_Kompass : 52|1@1+ (1,0) [0|1] "" XXX
 SG_ VL1_WFS_K : 53|1@1+ (1,0) [0|1] "" XXX
 SG_ VL1_GSM_Pager : 54|1@1+ (1,0) [0|1] "" XXX
 SG_ VL1_InfoElektronik : 55|1@1+ (1,0) [0|1] "" XXX
 SG_ VL1_DSP : 56|1@1+ (1,0) [0|1] "" XXX
 SG_ VL1_DAB : 57|1@1+ (1,0) [0|1] "" XXX
 SG_ VL1_Telematik : 58|1@1+ (1,0) [0|1] "" XXX
 SG_ VL1_Navigation : 59|1@1+ (1,0) [0|1] "" XXX
 SG_ VL1_TV_Tuner : 60|1@1+ (1,0) [0|1] "" XXX
 SG_ VL1_Neigungsmodul_I : 61|1@1+ (1,0) [0|1] "" XXX
 SG_ VL1_Radio : 62|1@1+ (1,0) [0|1] "" XXX
 SG_ VL1_Telefon : 63|1@1+ (1,0) [0|1] "" XXX

BO_ 1490 Ident: 8 XXX
 SG_ IDT_Mux M : 0|2@1+ (1,0) [0|2] "" XXX
 SG_ IDT_Geheimnis_1 m0 : 8|8@1+ (1,0) [0|255] "" XXX
 SG_ IDT_VIN_4 m1 : 8|8@1+ (1,0) [0|255] "" XXX
 SG_ IDT_VIN_11 m2 : 8|8@1+ (1,0) [0|255] "" XXX
 SG_ IDT_Geheimnis_2 m0 : 16|8@1+ (1,0) [0|255] "" XXX
 SG_ IDT_VIN_5 m1 : 16|8@1+ (1,0) [0|255] "" XXX
 SG_ IDT_VIN_12 m2 : 16|8@1+ (1,0) [0|255] "" XXX
 SG_ IDT_Geheimnis_3 m0 : 24|8@1+ (1,0) [0|255] "" XXX
 SG_ IDT_VIN_6 m1 : 24|8@1+ (1,0) [0|255] "" XXX
 SG_ IDT_VIN_13 m2 : 24|8@1+ (1,0) [0|255] "" XXX
 SG_ IDT_Geheimnis_4 m0 : 32|8@1+ (1,0) [0|255] "" XXX
 SG_ IDT_VIN_7 m1 : 32|8@1+ (1,0) [0|255] "" XXX
 SG_ IDT_VIN_14 m2 : 32|8@1+ (1,0) [0|255] "" XXX
 SG_ IDT_VIN_1 m0 : 40|8@1+ (1,0) [0|255] "" XXX
 SG_ IDT_VIN_8 m1 : 40|8@1+ (1,0) [0|255] "" XXX
 SG_ IDT_VIN_15 m2 : 40|8@1+ (1,0) [0|255] "" XXX
 SG_ IDT_VIN_2 m0 : 48|8@1+ (1,0) [0|255] "" XXX
 SG_ IDT_VIN_9 m1 : 48|8@1+ (1,0) [0|255] "" XXX
 SG_ IDT_VIN_16 m2 : 48|8@1+ (1,0) [0|255] "" XXX
 SG_ IDT_VIN_3 m0 : 56|8@1+ (1,0) [0|255] "" XXX
 SG_ IDT_VIN_10 m1 : 56|8@1+ (1,0) [0|255] "" XXX
 SG_ IDT_VIN_17 m2 : 56|8@1+ (1,0) [0|255] "" XXX

BO_ 2000 Diagnose_1: 8 XXX
 SG_ DI1_VerlernZaehl : 0|8@1+ (1,0) [0|254] "" XXX
 SG_ DI1_km_Stand : 8|20@1+ (1,0) [0|1048575] "Unit_KiloMeter" XXX
 SG_ DI1_Jahr : 28|7@1+ (1,2000) [2000|2127] "Unit_Year" XXX
 SG_ DI1_Monat : 35|4@1+ (1,0) [1|12] "Unit_Month" XXX
 SG_ DI1_Tag : 39|5@1+ (1,0) [0|31] "Unit_Day" XXX
 SG_ DI1_Stunde : 44|5@1+ (1,0) [0|23] "Unit_Hours" XXX
 SG_ DI1_Minute : 49|6@1+ (1,0) [0|59] "Unit_Minut" XXX
 SG_ DI1_Sekunde : 55|6@1+ (1,0) [0|59] "Unit_Secon" XXX
 SG_ DI1_KM_Stand_alt : 62|1@1+ (1,0) [0|1] "" XXX
 SG_ DI1_Zeit_alt : 63|1@1+ (1,0) [0|1] "" XXX

CM_ SG_ 80 Checksumme_Airbag_1 "Checksum Airbag_1";
CM_ SG_ 80 Zaehler_Airbag_1 "Counter Airbag_1";

CM_ SG_ 210 LM_Offset "centiNewton-meters for ease of calculation without FP math in Panda";
CM_ SG_ 210 Vib_Amp "Steering wheel haptic, amplitude";
CM_ SG_ 210 Vib_Freq "Steering wheel haptic, frequency";

CM_ SG_ 416 Zaehler_Bremse_1 "Counter Bremse_1";

CM_ SG_ 640 inneres_Motor_Moment "Engine Indicated Torque";
CM_ SG_ 640 Fahrerwunschmoment "Driver Requested Torque";
CM_ SG_ 640 mechanisches_Motor_Verlustmomen "Mechanical Torque Loss";
CM_ SG_ 640 Fahrpedalwert_oder_Drosselklapp "Accelerator Pedal or Throttle Position";
CM_ SG_ 640 Motordrehzahl "Engine Speed";
CM_ SG_ 640 Momentenangaben_ungenau "Approximate Torque Values";
CM_ SG_ 640 inneres_Motor_Moment_ohne_exter "Inner torque without external";

CM_ SG_ 644 MOB_CHECKSUM "Checksum MOB";
CM_ SG_ 644 MOB_COUNTER "Counter MOB";

CM_ SG_ 648 Minimales_Motormoment_bei_Zuend "Minimum Torque Adjustment";
CM_ SG_ 648 Begrenzungsmoment "Maximum Inner Torque";
CM_ SG_ 648 Bremstestschalter "Brake Test Switch";
CM_ SG_ 648 Soll_Geschwindigkeit_bei_GRA_Be "Desired Vehicle Speed";
CM_ SG_ 648 Bremslichtschalter "Brake Light Switch";
CM_ SG_ 648 Leerlaufsolldrehzahl__Motor_2_ "Target Idle Speed";
CM_ SG_ 648 Fahrzeuggeschwindigkeit "Vehicle Speed";
CM_ SG_ 648 Kuehlmitteltemperatur__Motor_2_ "Coolant Temperature";

CM_ SG_ 896 Drosselklappenpoti "Throttle Position";
CM_ SG_ 896 Motor_Wunschdrehzahl "Desired engine speed";
CM_ SG_ 896 Motordrehzahlbeeinflussung "Shift Target Influence";
CM_ SG_ 896 Fahrpedal_Rohsignal "Accelerator Pedal Position";
CM_ SG_ 896 Ansauglufttemperatur "Intake Air Temperature";
CM_ SG_ 896 Kein_E_Gas "ETB flag";
CM_ SG_ 896 Kein_Start_Stop "Start/stop flag";
CM_ SG_ 896 Rad_Wunschmoment "Desired wheel torque";

CM_ SG_ 912 GK1_Fa_Tuerkont "Status of the driver's door rotary latch";
CM_ SG_ 912 BSK_HL_geoeffnet "Status of the rear left door rotary latch";
CM_ SG_ 912 BSK_HR_geoeffnet "Status of the rear right door rotary latch";
CM_ SG_ 912 BSK_BT_geoeffnet "Status of the passenger door rotary latch";
CM_ SG_ 912 BSK_HD_Hauptraste "Status of trunk lid main detent";

CM_ SG_ 1088 Zaehler_Getriebe_1 "Counter Getriebe_1";
CM_ SG_ 1088 Waehlhebelposition__Getriebe_1_ "Gear Selector Position";
CM_ SG_ 1088 inneres_Soll_Motormoment "Desired Inner Torque";
CM_ SG_ 1088 Schaltabsicht "Shift Intent";
CM_ SG_ 1088 Wandlerverlustmoment "Converter Torque Loss";

CM_ SG_ 1056 Fehlerstatus_Aussentemp__4_1 "ambient temp error";
CM_ SG_ 1056 Fehlerstatus_Oeltemperatur_4_1 "oil temp error";
CM_ SG_ 1056 Fehlerst__Kuehlmitteltemp__4_1 "water temp error";
CM_ SG_ 1056 Aussentemperatur_gefiltert "outside temp, filtered";
CM_ SG_ 1056 Oeltemperatur_4_1 "kombi oil temperature";
CM_ SG_ 1056 Kuehlmitteltemp__4_1__Kombi_2_ "kombi coolant temperature";

CM_ SG_ 1096 Zaehler_Waehlhebel_1 "Counter Waehlhebel_1";

CM_ SG_ 1152 CHECKSUM "Checksum Motor_5";
CM_ SG_ 1152 Anlasser_Ausspuren "Starter Disable";
CM_ SG_ 1152 Anlasser_Freigabe "Starter Release";
CM_ SG_ 1152 Klimadrucksignal__Motor_5_ "Air conditioning pressure signal";
CM_ SG_ 1152 Kraftstoffverbrauchssignal "Fuel consumption signal";
CM_ SG_ 1152 K_hlerluefteransteuerung "Cooling fan control signal";
CM_ SG_ 1152 Klimakompressor_Leistungsreduzi "Air conditioning compressor power reduction flag";
CM_ SG_ 1152 Klimakompressor_aus__Motor_5_ "Air conditioning compressor";
CM_ SG_ 1152 Anlasser_Freigabe "Starter release";
CM_ SG_ 1152 OBD_2_Lampe "OBD light";
CM_ SG_ 1152 E_Gas_Lampe "ETB light";
CM_ SG_ 1152 Ladekontroll_Lampe "Charge light";
CM_ SG_ 1152 Vorgluehlampe__Motor_5_ "Glow light";

CM_ SG_ 1160 Zaehler_Motor_6 "Counter Motor_6";
CM_ SG_ 1160 Hoeheninfo__Motor_6_ "Altitude Correction";
CM_ SG_ 1160 Istmoment_f_r_Getriebe "Actual torque for gear";
CM_ SG_ 1160 Sollmoment_f_r_Getriebe "Target torque for gearbox";
CM_ SG_ 1160 Checksumme_Motor_6 "Checksum Motor_6";
CM_ SG_ 1160 GRA_Sollbeschleunigung "GRA target acceleration";
CM_ SG_ 1160 Ruckmeldung_Momenten "Feedback torque-integral gear intervention";

CM_ SG_ 1344 Zahler_Getriebe_2 "Counter Getriebe_2";
CM_ SG_ 1344 Hochschaltlampe "Upshift Flag";

CM_ SG_ 1386 ACA_V_Wunsch "255=unset";

CM_ SG_ 1408 Zaehler_Motor_Flexia "Counter Motor_Flexia";
CM_ SG_ 1408 Verbrennungsart "Type of combustion";
CM_ SG_ 1408 Max_Drehmoment "Maximum torque";
CM_ SG_ 1408 Drehzahl_MaxNorm "RPM of maximum torque";
CM_ SG_ 1408 Hubraum "Displacement";
CM_ SG_ 1408 Anzahl_Zylinder "Number of cylinders";
CM_ SG_ 1408 Anzahl_Ventile "Number of valves";
CM_ SG_ 1408 Ansaugsystem "Induction System";
CM_ SG_ 1408 Motorleistung "Maximum engine power";

CM_ SG_ 1416 Ladedruck "Boost Pressure";
CM_ SG_ 1416 Motordrehzahlgradient "Engine speed gradient";
CM_ SG_ 1416 Hoeheninfo__Motor_7_ "Altitude correction factor";
CM_ SG_ 1416 Oltemperatur "Oil temperature";

CM_ SG_ 1470 LDW_Direction "0=right,1=left";
CM_ SG_ 1470 XX_DLCORTLC1 "Might be DLC or TLC";
CM_ SG_ 1470 XX_DLCORTLC2 "Might be DLC or TLC, might have wrong size";

CM_ SG_ 1550 MFA_v_Signal_02 "0=km/h, 1=mph";

VAL_ 823 DteAcceptNew_B_Rq 1 "Yes" 0 "No";
VAL_ 824 DteCldTrlrOn_B_Stat 1 "Yes" 0 "No";
VAL_ 824 DteCldTrlrOff_B_Stat 1 "Yes" 0 "No";
VAL_ 824 DteCldTraffic_B_Stat 1 "Yes" 0 "No";
VAL_ 824 DteCldTerrain_B_Stat 1 "Yes" 0 "No";
VAL_ 824 DteCldRoute_B_Stat 1 "Yes" 0 "No";
VAL_ 824 DteCldPayload_B_Stat 1 "Yes" 0 "No";
VAL_ 824 DteCldExtTe_B_Stat 1 "Yes" 0 "No";
VAL_ 824 DteCldDcac_B_Stat 1 "Yes" 0 "No";
VAL_ 949 Tire_Press_RR_ORR_Data 65535 "Not_Supported" 65534 "Invalid" 65533 "Unknown";
VAL_ 949 Tire_Press_LR_OLR_Data 65535 "Not_Supported" 65534 "Invalid" 65533 "Unknown";
VAL_ 949 Tire_Press_LF_Data 65535 "Not_Supported" 65534 "Invalid" 65533 "Unknown";
VAL_ 949 Tire_Press_RF_Data 65535 "Not_Supported" 65534 "Invalid" 65533 "Unknown";
VAL_ 740 BattAuxCnnct_B_Cmd 1 "Close" 0 "Open";
VAL_ 1160 DgtlCommPncReset_B_Req 1 "Yes" 0 "No";
VAL_ 1160 DataMntrSustn_B_Rq 1 "Active" 0 "Inactive";
VAL_ 1160 PwSustnRdata_B_RqTelem 1 "Active" 0 "Inactive";
VAL_ 776 ScChrgrPwMax_Pw_RqCld 4095 "Faulty";
VAL_ 776 PrcondEdit_D_RqCld 7 "NotUsed_3" 6 "NotUsed_2" 5 "NotUsed_1" 4 "High" 3 "Medium" 2 "Low" 1 "Off" 0 "Null";
VAL_ 776 GoTEditMnte_T_RqCld 15 "Faulty" 14 "NoDataExists" 13 "NotUsed_2" 12 "NotUsed_1" 11 "Minute_55" 10 "Minute_50" 9 "Minute_45" 8 "Minute_40" 7 "Minute_35" 6 "Minute_30" 5 "Minute_25" 4 "Minute_20" 3 "Minute_15" 2 "Minute_10" 1 "Minute_5" 0 "Minute_0";
VAL_ 776 GoTEditHr_T_RqCld 31 "Faulty" 30 "NoDataExists";
VAL_ 776 ChrgToPcEdit_Pc_RqCld 127 "Faulty" 126 "NoDataExists";
VAL_ 776 ScFreshDataEnbl_B_Rq 1 "Yes" 0 "No";
VAL_ 776 ScEnbl_D_RqCld 3 "NotUsed" 2 "On" 1 "Off" 0 "Null";
VAL_ 775 ScDayOfWeekId_D_RqCld 7 "Sunday" 6 "Saturday" 5 "Friday" 4 "Thursday" 3 "Wednesday" 2 "Tuesday" 1 "Monday" 0 "NotUsed";
VAL_ 775 ScChrgDurSet_D_RqCld 3 "NotUsed" 2 "On" 1 "Off" 0 "Null";
VAL_ 775 ScChrgDur_T_RqCld 2047 "Faulty" 2046 "NoDataExists";
VAL_ 774 ScLocLongPostv_B_RqCld 1 "Yes" 0 "No";
VAL_ 774 ScLocLattPostv_B_RqCld 1 "Yes" 0 "No";
VAL_ 774 ScLocDelete_B_RqCld 1 "Request" 0 "NoRequest";
VAL_ 811 DistToStopover_L_Actl 65535 "Faulty";
VAL_ 811 ExtLghtDsply_D_Stat 7 "NotUsed" 6 "PressToOn3" 5 "PressToOff3" 4 "PressToOn2" 3 "PressToOff2" 2 "PressToOn1" 1 "PressToOff1" 0 "Reset";
VAL_ 811 ExtLghtRight_D_RqMnu 7 "NotUsed" 6 "PressToOn3" 5 "PressToOff3" 4 "PressToOn2" 3 "PressToOff2" 2 "PressToOn1" 1 "PressToOff1" 0 "Reset";
VAL_ 811 AutoLghtOvrrd_B_RqDrv 1 "Allowed" 0 "NotAllowed";
VAL_ 811 ExtLghtRear_D_RqMnu 7 "NotUsed" 6 "PressToOn3" 5 "PressToOff3" 4 "PressToOn2" 3 "PressToOff2" 2 "PressToOn1" 1 "PressToOff1" 0 "Reset";
VAL_ 811 ExtLghtLeft_D_RqMnu 7 "NotUsed" 6 "PressToOn3" 5 "PressToOff3" 4 "PressToOn2" 3 "PressToOff2" 2 "PressToOn1" 1 "PressToOff1" 0 "Reset";
VAL_ 811 ExtLghtFront_D_RqMnu 7 "NotUsed" 6 "PressToOn3" 5 "PressToOff3" 4 "PressToOn2" 3 "PressToOff2" 2 "PressToOn1" 1 "PressToOff1" 0 "Reset";
VAL_ 811 GoTEditMnte_T_RqMnu 15 "Faulty" 14 "NoDataExists" 13 "NotUsed_2" 12 "NotUsed_1" 11 "Minute_55" 10 "Minute_50" 9 "Minute_45" 8 "Minute_40" 7 "Minute_35" 6 "Minute_30" 5 "Minute_25" 4 "Minute_20" 3 "Minute_15" 2 "Minute_10" 1 "Minute_5" 0 "Minute_0";
VAL_ 811 GoTEditHr_T_RqMnu 31 "Faulty" 30 "NoDataExists";
VAL_ 850 VehElRngeNut_L_Dsply 4095 "Faulty" 4094 "NoDataExists";
VAL_ 850 NxtUsgSocEst_Pc_Dsply 255 "Faulty" 254 "NoDataExists";
VAL_ 850 EstmChrgTimeLP_St 255 "Invalid";
VAL_ 850 EstmChrgTimeHP_St 255 "Invalid";
VAL_ 850 ChargeNowDuration_St 255 "Invalid";
VAL_ 563 DrvBhavWarn_B_Rq 1 "On" 0 "Off";
VAL_ 563 OfbChrgSetSync_D_Rq 3 "Fail" 2 "Success" 1 "InProgress" 0 "NoSyncInProgress";
VAL_ 563 KeyOffPwMde_D_Stat 7 "NotUsed_6" 6 "NotUsed_5" 5 "NotUsed_4" 4 "NotUsed_3" 0 "Inactive" 1 "On" 2 "NotUsed_1" 3 "NotUsed_2";
VAL_ 563 ModemReset_D_Stat 15 "NotUsed_10" 14 "NotUsed_9" 13 "NotUsed_8" 12 "NotUsed_7" 11 "NotUsed_6" 10 "NotUsed_5" 9 "NotUsed_4" 8 "NotUsed_3" 7 "NotUsed_2" 6 "NotUsed_1" 5 "WifiHotSpotResetComplete" 4 "CcsResetComplete" 3 "OnlineTrafficResetComplete" 2 "PaakResetComplete" 1 "ResetNotComplete" 0 "Null";
VAL_ 563 FactoryReset_St 3 "NotUsed_2" 2 "NotUsed_1" 1 "FactoryDefaultsRestored" 0 "Null";
VAL_ 570 SuspClkSync_No_Rq 255 "Faulty" 254 "NoDataExists";
VAL_ 570 SuspRearRight_L_Actl 511 "Faulty";
VAL_ 570 SuspFrntRight_L_Actl 511 "Faulty";
VAL_ 570 SuspRear_L_Prev 511 "Fault";
VAL_ 570 SuspRear_L_Actl 511 "Fault";
VAL_ 570 SuspFrnt_L_Prev 511 "Fault";
VAL_ 570 SuspFrnt_L_Actl 511 "Fault";
VAL_ 837 Ccd_B_Falt 1 "Yes" 0 "No";
VAL_ 837 SelDrvMdeSusp_D_Stat 3 "Faulty" 2 "TemporarilyNotAvailable" 1 "Available" 0 "NotAvailable";
VAL_ 837 AdptDrvMdePt_D_Rq 7 "Faulty" 6 "NotUsed3" 5 "NotUsed2" 4 "NotUsed1" 3 "Powertrain2Sport" 2 "Powertrain2Normal" 1 "Powertrain2Comfort" 0 "AdaptiveNotActive";
VAL_ 837 AdptDrvMdeChassis_D_Rq 7 "Faulty" 6 "NotUsed3" 5 "NotUsed2" 4 "NotUsed1" 3 "Chassis2Sport" 2 "Chassis2Normal" 1 "Chassis2Comfort" 0 "AdaptiveNotActive";
VAL_ 837 CcdMsgTxt_D_RqDsply 15 "Unused8" 14 "Unused7" 13 "Unused6" 12 "Unused5" 11 "Unused4" 10 "Unused3" 9 "Unused2" 8 "StationaryMode" 7 "Mode_Change_Unavailable" 6 "CCD_Temporarily_Off" 5 "CCD_Service_Required" 4 "Faulty" 3 "Sport" 2 "Normal" 1 "Comfort" 0 "No_Mode_Selected";
VAL_ 885 BattULoChrg_D_RqOta 1 "Yes" 0 "No";
VAL_ 885 VehStrtInhbt_T_Dsply 15 "NotUsed_12" 14 "NotUsed_11" 13 "NotUsed_10" 12 "NotUsed_9" 11 "NotUsed_8" 10 "NotUsed_7" 9 "NotUsed_6" 8 "NotUsed_5" 7 "NotUsed_4" 6 "NotUsed_3" 5 "NotUsed_2" 4 "NotUsed_1" 3 "PostOtaActivatePermFail" 2 "PostOtaActivateWarning" 1 "DuringOtaActivate" 0 "NoMessage";
VAL_ 885 VehStrtInhbt_D_Dsply 15 "NotUsed_12" 14 "NotUsed_11" 13 "NotUsed_10" 12 "NotUsed_9" 11 "NotUsed_8" 10 "NotUsed_7" 9 "NotUsed_6" 8 "NotUsed_5" 7 "NotUsed_4" 6 "NotUsed_3" 5 "NotUsed_2" 4 "NotUsed_1" 3 "PostOtaActivatePermFail" 2 "PostOtaActivateWarning" 1 "DuringOtaActivate" 0 "NoMessage";
VAL_ 885 VehOnRqstr_D_Stat 11 "NotUsed_8" 10 "NotUsed_7" 9 "NotUsed_6" 8 "NotUsed_5" 7 "NotUsed_4" 6 "NotUsed_3" 5 "NotUsed_2" 4 "NotUsed_1" 3 "FleetVehInhbt" 2 "StolenVehInhbt" 1 "OverTheAir" 0 "NoRequestor" 15 "NotUsed_12" 14 "NotUsed_11" 13 "NotUsed_10" 12 "NotUsed_9";
VAL_ 885 VehStrtInhbt_D_RqCld 3 "NotUsed" 2 "On" 1 "Off" 0 "Null";
VAL_ 885 VehOn_D_RqCld 3 "NoControl" 2 "On" 1 "Off" 0 "Null";
VAL_ 885 OtaActv_D_Stat 15 "NotUsed_10" 14 "NotUsed_9" 13 "NotUsed_8" 12 "NotUsed_7" 11 "NotUsed_6" 10 "NotUsed_5" 9 "NotUsed_4" 8 "NotUsed_3" 7 "NotUsed_2" 6 "NotUsed_1" 5 "NonInterruptible_Pending" 4 "NonInterruptible_Config" 3 "NonInterruptible_ER" 2 "NonInterruptible_AB" 1 "Interruptible_AB" 0 "NoInVehicleOta";
VAL_ 810 OBCCSerial_D_Rq 3 "PresentAndProvisioned" 2 "PresentAndProvAlertAck" 1 "PresentAndUnprovisioned" 0 "NotPresent";
VAL_ 810 TlghtTest_D_RqArb 3 "TestEndAcknowledge" 2 "StartTest" 1 "StopTest" 0 "Null";
VAL_ 810 ChrgrPncSustn_B_Rq 1 "Active" 0 "Inactive";
VAL_ 810 NtfyDrvTrgtDist_L_Rq 4095 "Trip_dist_alert_disabled" 0 "Inactive";
VAL_ 810 NtfyDrvSocLvl1_Pc_Rq 127 "TargetSOCNotificationAlert" 0 "Inactive";
VAL_ 810 PtRmtRprt_D_Stat 15 "NotUsed_4" 14 "NotUsed_3" 13 "NotUsed_2" 12 "NotUsed_1" 11 "SettingUpdated" 10 "FastChargeComplete" 9 "ChargeNotOccurring" 8 "OneTimeSocReached" 7 "BatteryTemperatureRemind" 6 "ReducedPerformance" 5 "LimitedPerformance" 4 "ChargeFault" 3 "ChargeComplete" 2 "VehiclePreconditioned" 1 "TripDistanceAchieved" 0 "NoReportRequest";
VAL_ 810 ChrgrPncEnbl_D_Rq 3 "NotUsed" 2 "Enable" 1 "Disable" 0 "Null";
VAL_ 810 ExtLghtDsply_B_StatArb 1 "On" 0 "Off";
VAL_ 810 ExtLghtRight_D_RqOta 7 "NotUsed" 6 "PressToOn3" 5 "PressToOff3" 4 "PressToOn2" 3 "PressToOff2" 2 "PressToOn1" 1 "PressToOff1" 0 "Reset";
VAL_ 810 ExtLghtRear_D_RqOta 7 "NotUsed" 6 "PressToOn3" 5 "PressToOff3" 4 "PressToOn2" 3 "PressToOff2" 2 "PressToOn1" 1 "PressToOff1" 0 "Reset";
VAL_ 810 ExtLghtLeft_D_RqOta 7 "NotUsed" 6 "PressToOn3" 5 "PressToOff3" 4 "PressToOn2" 3 "PressToOff2" 2 "PressToOn1" 1 "PressToOff1" 0 "Reset";
VAL_ 810 ExtLghtFront_D_RqOta 7 "NotUsed" 6 "PressToOn3" 5 "PressToOff3" 4 "PressToOn2" 3 "PressToOff2" 2 "PressToOn1" 1 "PressToOff1" 0 "Reset";
VAL_ 550 PtWakeupActv1_B_Rq 1 "Wake_up_Powertrain_via_HW" 0 "Don_t_Wake_Up_Powertrain";
VAL_ 639 OfbChrgPrflUpdate_B_Rq 1 "Request" 0 "NoRequest";
VAL_ 639 OfbChrgClearAll_B_Rq 1 "Request" 0 "NoRequest";
VAL_ 639 OfbChrgGoTTouch_D_Rq 3 "NotUsed" 2 "On" 1 "Off" 0 "Null";
VAL_ 639 OfbChrgGoTPrcond_D_Rq 3 "High" 2 "Medium" 1 "Low" 0 "Off";
VAL_ 639 OfbChrgGoTOn_D_Rq 3 "NotUsed" 2 "On" 1 "Off" 0 "Null";
VAL_ 639 OfbChrgGoTMnte_D_Rq 15 "NotUsed_4" 14 "NotUsed_3" 13 "NotUsed_2" 12 "NotUsed_1" 11 "Minute_55" 10 "Minute_50" 9 "Minute_45" 8 "Minute_40" 7 "Minute_35" 6 "Minute_30" 5 "Minute_25" 4 "Minute_20" 3 "Minute_15" 2 "Minute_10" 1 "Minute_5" 0 "Minute_0";
VAL_ 639 OfbChrgGoTHr_T_Rq 31 "Faulty" 30 "NoDataExists";
VAL_ 639 OfbChrgGoTExtHtr_D_Rq 3 "NotUsed" 2 "On" 1 "Off" 0 "Null";
VAL_ 639 OfbChrgGoTDelete_B_Rq 1 "Request" 0 "NoRequest";
VAL_ 639 OfbChrgGoTUpdate_B_Rq 1 "Request" 0 "NoRequest";
VAL_ 530 OfbChrgToPcWknd_D_Actl 7 "Percent_50" 6 "Percent_60" 5 "Percent_70" 4 "Percent_80" 3 "Percent_85" 2 "Percent_90" 1 "Percent_95" 0 "Percent_100";
VAL_ 530 OfbChrgToPcWkdy_D_Actl 7 "Percent_50" 6 "Percent_60" 5 "Percent_70" 4 "Percent_80" 3 "Percent_85" 2 "Percent_90" 1 "Percent_95" 0 "Percent_100";
VAL_ 530 OfbChrgSetNow_D_Rq 3 "NotUsed" 2 "On" 1 "Off" 0 "Null";
VAL_ 530 OfbChrgSetDelete_B_Rq 1 "Request" 0 "NoRequest";
VAL_ 530 OfbChrgLocIdUns_B_Rq 1 "Request" 0 "NoRequest";
VAL_ 1142 ConsTipV_No_Dsply 1023 "Faulty" 1022 "NoDataExists";
VAL_ 817 ChildLckMde_B_Stat 1 "Enable" 0 "Disable";
VAL_ 817 VehLckInd_D_Rq 3 "NotUsed" 2 "On_Day" 1 "On_Night" 0 "Off";
VAL_ 817 DrTgateOpen_B_Rq 1 "Open" 0 "Null";
VAL_ 817 DrTgateExtSwMde_B_Stat 1 "Enable" 0 "Disable";
VAL_ 817 Remote_Device_Feedback 7 "Unused3" 6 "Unused2" 5 "Unused1" 4 "Shutdown" 3 "Running" 2 "Starting" 1 "Acknowledge" 0 "Null";
VAL_ 817 Veh_Lock_Requestor 31 "Unused8" 30 "Unused7" 29 "Unused6" 28 "Rgtm_Shutlock_Switch" 27 "Boundary_Alert" 26 "Transit_Vehicle_Relock" 25 "Transit_Cargo_Relock" 24 "Transit_Ajar_Lock" 23 "Diagnostics" 22 "Console_Lock" 21 "Child_Lock" 20 "Double_Lock" 19 "Passive_Pasenger" 18 "Passive_Driver" 17 "Slam_Lock_Protect" 16 "SYNC" 15 "Passport" 14 "Passive_Smart_Unlock" 13 "Autorelock" 12 "RemoteStart" 0 "Null" 1 "Autolock" 11 "Smart_Unlock" 10 "Sliding_Door" 9 "Passive" 8 "Remote" 7 "Programming" 6 "Powerslide" 5 "Keypad" 4 "Key_Cylinder" 3 "Interior" 2 "Auto_Unlock";
VAL_ 817 R_Pwr_Sliding_Dr_Rqst 1 "Active" 0 "Null";
VAL_ 817 Power_Liftgate_Rqst 1 "Active" 0 "Null";
VAL_ 817 Power_Decklid_Rqst 1 "Active" 0 "Null";
VAL_ 817 L_Pwr_Sliding_Dr_Rqst 1 "Active" 0 "Null";
VAL_ 817 Veh_Lock_Sub_Id 15 "Unused7" 14 "Unused6" 13 "Unused5" 12 "Unused4" 11 "Unused3" 10 "Unused2" 9 "Unused1" 8 "Customer_8" 7 "Customer_7" 6 "Customer_6" 5 "Customer_5" 4 "Customer_4" 3 "Customer_3" 2 "Customer_2" 1 "Customer_1" 0 "Null";
VAL_ 817 Veh_Lock_Status 3 "UNLOCK_DRV" 2 "UNLOCK_ALL" 1 "LOCK_ALL" 0 "LOCK_DBL";
VAL_ 817 ChildLck_D_Dsply 3 "NOT_SUPPORTED" 2 "ERROR" 1 "CHILD_UNLOCK" 0 "CHILD_LOCK";
VAL_ 817 WindowLockout_B_Stat 1 "Locked" 0 "Unlock";
VAL_ 817 Lockmsgtxt_D_Rq 7 "MSG7" 6 "MSG6" 5 "MSG5" 4 "MSG4" 3 "MSG3" 2 "MSG2" 1 "MSG1" 0 "NO_WARNING";
VAL_ 817 FobComm_D_Stat 3 "NotUsed" 2 "RemEngStartOK" 1 "RemEngStartFail" 0 "Null";
VAL_ 817 LockInhibit 1 "Inhibit" 0 "No_Inhibit";
VAL_ 879 WndwRearHeat_I_Actl 2047 "Faulty";
VAL_ 879 WndwRearHeat_D_Stat 7 "NotUsed" 6 "FetLiftLimitReached" 5 "FetOpenCircuit" 4 "FetOutputShortToPower" 3 "FetOutputShortToGround" 2 "FetNotControlled" 1 "OnPowerToLoad" 0 "OffNoPowerToLoad";
VAL_ 878 DcacGfciTest_B_Rq 1 "Pressed" 0 "Not_Pressed";
VAL_ 878 DcacOut_Pw_DsplyMx 1023 "Faulty";
VAL_ 878 DcacOut1_Pw_Dsply 63 "Faulty";
VAL_ 878 DcacOut2_Pw_Dsply 63 "Faulty";
VAL_ 878 DcacHw_D_Confg 15 "NotUsed_11" 14 "NotUsed_10" 13 "NotUsed_9" 12 "NotUsed_8" 11 "NotUsed_7" 10 "NotUsed_6" 9 "NotUsed_5" 8 "NotUsed_4" 7 "NotUsed_3" 6 "NotUsed_2" 5 "NotUsed_1" 4 "Power_2300W" 3 "Power_7200W" 2 "Power_2400W" 1 "Power_2000W" 0 "NoDcacHardware";
VAL_ 878 DcacFaltMsgTxt_D_Rq 15 "NotUsed" 14 "OvercurrentLP" 13 "EngineRun" 12 "Service" 11 "NotAvailable" 10 "PlugWarn" 9 "PlugWarnDrive" 8 "BreakerC" 7 "BreakerB" 6 "BreakerA" 5 "FuelLow" 4 "AcOnOutput" 3 "Temperature" 2 "Gfci" 1 "Overcurrent" 0 "Ok";
VAL_ 878 DcacLoFuelMsgTxt_D_Rq 31 "Minute_31" 30 "Minute_30" 29 "Minute_29" 28 "Minute_28" 27 "Minute_27" 26 "Minute_26" 25 "Minute_25" 24 "Minute_24" 23 "Minute_23" 22 "Minute_22" 21 "Minute_21" 20 "Minute_20" 19 "Minute_19" 18 "Minute_18" 17 "Minute_17" 16 "Minute_16" 15 "Minute_15" 14 "Minute_14" 13 "Minute_13" 12 "Minute_12" 11 "Minute_11" 10 "Minute_10" 9 "Minute_9" 8 "Minute_8" 7 "Minute_7" 6 "Minute_6" 5 "Minute_5" 4 "Minute_4" 3 "Minute_3" 2 "Minute_2" 1 "Minute_1" 0 "Ok";
VAL_ 878 DcacEngOnMsgTxt_D_Rq 3 "NotUsed" 2 "DisplayQuestion" 1 "DisplayWarning" 0 "Ok";
VAL_ 878 DcacElPw_D_Stat 3 "NotUsed" 2 "High" 1 "Low" 0 "Off";
VAL_ 878 PwBedPnlEnbl_B_Rq 1 "Enable" 0 "Disable";
VAL_ 878 DcacOn_B_Rq 1 "Enable" 0 "Disable";
VAL_ 878 DcacSys_B_Falt 1 "Yes" 0 "No";
VAL_ 878 DcacLedCtl_D_Rq 3 "Fast_Flash" 2 "Slow_Flash" 1 "On" 0 "Off";
VAL_ 395 SelDrvMdeCnfm_D_Stat 3 "NotUsed" 2 "Accepted" 1 "NotAccepted" 0 "Null";
VAL_ 984 PersIndexIpma_D_Actl 7 "Unused_3" 6 "Unused_2" 5 "Unused_1" 4 "Vehicle" 3 "PERS_4" 2 "PERS_3" 1 "PERS_2" 0 "PERS_1";
VAL_ 984 AhbcRampingV_D_Rq 3 "Slow" 2 "Medium" 1 "Fast" 0 "Immediately";
VAL_ 984 LaActvStats_D_Dsply 31 "Unused7" 30 "LA_Off" 29 "Unused5" 28 "Unused4" 27 "Unused3" 26 "Unused2" 25 "Unused1" 24 "InerveneLeft_InterveneRght" 23 "WarnLeft_InterveneRight" 22 "SuppressLeft_InterveneRght" 21 "AvailLeft_InterveneRhtt" 20 "NoLeft_InterveneRight" 19 "InterveneLeft_WarnRight" 18 "WarnLeft_WarnRight" 17 "SuppressLeft_WarnRight" 16 "AvailableLeft_WarnRight" 15 "NoLeft_WarnRight" 14 "InterveneLeft_SuppressRght" 13 "WarnLeft_SuppressRight" 12 "SuppressLeft_SuppressRight" 11 "AvailLeft_SuppressRight" 10 "NoLeft_SuppressRight" 9 "InterveneLeft_AvailRight" 8 "WarnLeft_AvailRight" 7 "SuppressLeft_AvailRight" 6 "AvailableLeft_AvailRight" 5 "NoLeft_AvailableRight" 4 "InterveneLeft_NoRight" 3 "WarnLeft_NoRight" 2 "SuppressLeft_NoRight" 1 "AvailableLeft_NoRight" 0 "NoLeft_NoRight";
VAL_ 984 LaDenyStats_B_Dsply 1 "Unavailable" 0 "Available";
VAL_ 984 LaHandsOff_D_Dsply 3 "Suppressed" 2 "Level2" 1 "Level1" 0 "HandsOn";
VAL_ 984 CamraDefog_B_Req 1 "On" 0 "Off";
VAL_ 984 CamraStats_D_Dsply 3 "FrtCam_TempUnavailOther" 2 "FrtCam_TempUnavailVisibile" 1 "Front_Camera_Service_Reqd" 0 "Front_Camera_OK";
VAL_ 984 DasAlrtLvl_D_Dsply 5 "Alertness_Level_5" 4 "Alertness_Level_4" 3 "Alertness_Level_3" 2 "Alertness_Level_2" 1 "Alertness_Level_1" 0 "Undefined";
VAL_ 984 DasStats_D_Dsply 3 "Available" 2 "Unavailable_Other" 1 "Feedback_due_to_Speed" 0 "Off";
VAL_ 984 DasWarn_D_Dsply 3 "Undefined" 2 "Warning_Level_2" 1 "Warning_Level_1" 0 "No_Warning";
VAL_ 984 AhbHiBeam_D_Rq 3 "NotUsed" 2 "HighBeamRecommended" 1 "LowBeamRecommended" 0 "DeactivatedUnavailable";
VAL_ 985 LdwChime_B_Rq 1 "On" 0 "Off";
VAL_ 985 TsrRegionTxt_D_Stat 31 "Faulty" 30 "NotUsed_8" 29 "NotUsed_7" 28 "NotUsed_6" 27 "NotUsed_5" 26 "NotUsed_4" 25 "NotUsed_3" 24 "NotUsed_2" 23 "NotUsed_1" 22 "Region_22" 21 "Region_21" 20 "Region_20" 19 "Region_19" 18 "Region_18" 17 "Region_17" 16 "Region_16" 15 "Region_15" 14 "Region_14" 13 "Region_13" 12 "Region_12" 11 "Region_11" 10 "Region_10" 9 "Region_09" 8 "Region_08" 7 "Region_07" 6 "Region_06" 5 "Region_05" 4 "Region_04" 3 "Region_03" 2 "Region_02" 1 "Region_01" 0 "NotDetermined";
VAL_ 985 SblmPedCrossScnr_B_Stat 1 "Yes" 0 "No";
VAL_ 985 LongCtrlEnbl_D_Rq 7 "NotUsed_4" 6 "NotUsed_3" 5 "NotUsed_2" 4 "NotUsed_1" 3 "RemoteParking" 2 "Autohitch" 1 "AutomaticParking" 0 "None";
VAL_ 985 SblmRndAbtScnr_B_Stat 1 "Yes" 0 "No";
VAL_ 985 DasAlrtInfo_D_Dsply 3 "NotUsed" 2 "On" 1 "Off" 0 "Null";
VAL_ 985 IaccVLim_D_Rq 252 "NotUsed_2" 250 "LimitSpeed_250" 240 "LimitSpeed_240" 230 "LimitSpeed_230" 220 "LimitSpeed_220" 210 "LimitSpeed_210" 200 "LimitSpeed_200" 190 "LimitSpeed_190" 150 "LimitSpeed_150" 140 "LimitSpeed_140" 130 "LimitSpeed_130" 120 "LimitSpeed_120" 110 "LimitSpeed_110" 100 "LimitSpeed_100" 90 "LimitSpeed_90" 80 "LimitSpeed_80" 70 "LimitSpeed_70" 60 "LimitSpeed_60" 50 "LimitSpeed_50" 40 "LimitSpeed_40" 30 "LimitSpeed_30" 20 "LimtSpeed_20" 251 "NotUsed_1" 255 "Faulty" 254 "NoDataExists" 253 "NotUsed_3" 180 "LimitSpeed_180" 179 "LimitSpeed_179" 178 "LimitSpeed_178" 177 "LimitSpeed_177" 176 "LimitSpeed_176" 175 "LimitSpeed_175" 174 "LimitSpeed_174" 173 "LimitSpeed_173" 172 "LimitSpeed_172" 171 "LimitSpeed_171" 170 "LimitSpeed_170" 169 "LimitSpeed_169" 168 "LimitSpeed_168" 167 "LimitSpeed_167" 166 "LimitSpeed_166" 165 "LimitSpeed_165" 164 "LimitSpeed_164" 163 "LimitSpeed_163" 162 "LimitSpeed_162" 161 "LimitSpeed_161" 160 "LimitSpeed_160" 15 "LimitSpeed_15" 14 "LimitSpeed_14" 13 "LimitSpeed_13" 12 "LimitSpeed_12" 11 "LimitSpeed_11" 10 "LimitSpeed_10" 9 "LimitSpeed_9" 8 "LimitSpeed_8" 7 "LimitSpeed_7" 6 "LimitSpeed_6" 5 "LimitSpeed_5" 4 "LimitSpeed_4" 3 "LimitSpeed_3" 2 "LimitSpeed_2" 1 "LimitSpeed_1" 0 "LimitSpeed_0";
VAL_ 985 IaccVLimUnit_D_Rq 3 "NoDataExists" 2 "Mph" 1 "Kph" 0 "Null";
VAL_ 985 IsaVLim_D_Rq 252 "NotUsed_2" 250 "LimitSpeed_250" 240 "LimitSpeed_240" 230 "LimitSpeed_230" 220 "LimitSpeed_220" 210 "LimitSpeed_210" 200 "LimitSpeed_200" 190 "LimitSpeed_190" 150 "LimitSpeed_150" 140 "LimitSpeed_140" 130 "LimitSpeed_130" 120 "LimitSpeed_120" 110 "LimitSpeed_110" 100 "LimitSpeed_100" 90 "LimitSpeed_90" 80 "LimitSpeed_80" 70 "LimitSpeed_70" 60 "LimitSpeed_60" 50 "LimitSpeed_50" 40 "LimitSpeed_40" 30 "LimitSpeed_30" 20 "LimtSpeed_20" 251 "NotUsed_1" 255 "Faulty" 254 "NoDataExists" 253 "NotUsed_3" 180 "LimitSpeed_180" 179 "LimitSpeed_179" 178 "LimitSpeed_178" 177 "LimitSpeed_177" 176 "LimitSpeed_176" 175 "LimitSpeed_175" 174 "LimitSpeed_174" 173 "LimitSpeed_173" 172 "LimitSpeed_172" 171 "LimitSpeed_171" 170 "LimitSpeed_170" 169 "LimitSpeed_169" 168 "LimitSpeed_168" 167 "LimitSpeed_167" 166 "LimitSpeed_166" 165 "LimitSpeed_165" 164 "LimitSpeed_164" 163 "LimitSpeed_163" 162 "LimitSpeed_162" 161 "LimitSpeed_161" 160 "LimitSpeed_160" 15 "LimitSpeed_15" 14 "LimitSpeed_14" 13 "LimitSpeed_13" 12 "LimitSpeed_12" 11 "LimitSpeed_11" 10 "LimitSpeed_10" 9 "LimitSpeed_9" 8 "LimitSpeed_8" 7 "LimitSpeed_7" 6 "LimitSpeed_6" 5 "LimitSpeed_5" 4 "LimitSpeed_4" 3 "LimitSpeed_3" 2 "LimitSpeed_2" 1 "LimitSpeed_1" 0 "LimitSpeed_0";
VAL_ 985 SblmStopScnr_B_Stat 1 "Yes" 0 "No";
VAL_ 985 SblmYieldScnr_B_Stat 1 "Yes" 0 "No";
VAL_ 985 IsaVLimUnit_D_Rq 3 "NoDataExists" 2 "Mph" 1 "Kph" 0 "Null";
VAL_ 985 AdbDividedRoad_B_Stat 1 "Yes" 0 "No";
VAL_ 985 LcwaMsgTxt_D_Stat 3 "SodXFaulty" 2 "SodXBlocked" 1 "TrailerConnected" 0 "NoMessage";
VAL_ 985 AdbDrvSide_B_Stat 1 "Left_Hand_Traffic" 0 "Right_Hand_Traffic";
VAL_ 992 MsgCntrDsplyOp_D_Rq 7 "Unused_2" 6 "Unused_1" 5 "Copy" 4 "Restore" 3 "Upload" 2 "Set" 1 "Query" 0 "Null";
VAL_ 992 MsgCntrPersIndex_D_Rq 7 "Unused_3" 6 "Unused_2" 5 "Unused_1" 4 "Vehicle" 3 "PERS_4" 2 "PERS_3" 1 "PERS_2" 0 "PERS_1";
VAL_ 943 VehVActlAdas_D_Qf 3 "OK" 2 "Not_Within_Specifications" 1 "No_Data_Exists" 0 "Faulty";
VAL_ 943 AdasLcDistToObj_L_Actl 4095 "Faulty" 4094 "NoDataExists";
VAL_ 515 PtIgnSwtch_D_Stat 3 "Faulty" 2 "No_Data_Exists" 1 "On" 0 "Off";
VAL_ 1111 TrlrYawWActl_D_Qf 3 "OK" 2 "Not_Within_Specifications" 1 "No_Data_Exists" 0 "Faulty";
VAL_ 1111 TrlrYaw_W_Actl 65535 "Faulty" 65534 "NoDataExists";
VAL_ 1111 TrlrHitYaw_AnRate_Actl 4095 "Fault" 4094 "NoDataExists";
VAL_ 1111 TrlrHitchYaw_D_Stat 15 "Faulty" 14 "NotUsed_4" 13 "NotUsed_3" 12 "NotUsed_2" 11 "NotUsed_1" 10 "FaultyYrsuConnection" 9 "FaultyYrsu" 8 "HiConfdLrndAngle" 7 "LowConfdLrndAngle" 6 "HiConfdAngleMem" 5 "LowConfdAngleMem" 4 "InitNoTadAngle" 3 "InitInputs" 2 "TadTrlrDataOutOfRange" 1 "TadNotWithinSpecification" 0 "NoConnectionWithYrsu";
VAL_ 1111 TrlrHitchYaw_An_Actl 4095 "Faulty" 4094 "NoDataExists";
VAL_ 1106 TrlrSnsId_No_Actl -1 "Faulty_FFFFFFFFFFFF" -2 "NoDataExists_FFFFFFFFFFFE";
VAL_ 982 LatCtl_D2_Rq 7 "NotUsed_5" 6 "NotUsed_4" 5 "NotUsed_3" 4 "NotUsed_2" 3 "SafeRampOut" 2 "PathFollowingExtendedMode" 1 "PathFollowingLimitedMode" 0 "NoLateralControl";
VAL_ 982 HandsOffCnfm_B_Rq 1 "Active" 0 "Inactive";
VAL_ 982 LatCtlRampType_D_Rq 3 "Immediately" 2 "Fast" 1 "Medium" 0 "Slow";
VAL_ 982 LatCtlPrecision_D_Rq 3 "NotUsed2" 2 "NotUsed1" 1 "Precise" 0 "Comfortable";
VAL_ 1104 DrvEngageLevel_D_Stat 7 "Faulty" 6 "NotUsed_2" 5 "NotUsed_1" 4 "Disengaged" 3 "Distracted" 2 "Attentive" 1 "Invalid" 0 "NotDetermined";
VAL_ 1104 DrvImpLvlConfid_D_Stat 7 "Faulty" 6 "NotUsed" 5 "High" 4 "MediumHigh" 3 "Medium" 2 "LowMedium" 1 "Low" 0 "NotDetermined";
VAL_ 1104 DrvImpairLvl_D_Stat 15 "Faulty" 14 "NotUsed_5" 13 "NotUsed_4" 12 "NotUsed_3" 11 "NotUsed_2" 10 "NotUsed_1" 9 "Incapacitated" 8 "Asleep" 7 "Microsleep" 6 "MostDrowsy" 5 "Drowsy_4" 4 "Drowsy_3" 3 "Drowsy_2" 2 "LeastDrowsy" 1 "Alert" 0 "NotDetermined";
VAL_ 1104 DrvEngLvlConfid_D_Stat 7 "Faulty" 6 "NotUsed" 5 "High" 4 "MediumHigh" 3 "Medium" 2 "LowMedium" 1 "Low" 0 "NotDetermined";
VAL_ 1104 DrvCamPassIR_D_Stat 3 "Faulty" 2 "Blocked" 1 "Ok" 0 "TemporaryUnavailable";
VAL_ 1104 DrvCamera_D_Stat 3 "Faulty" 2 "Blocked" 1 "Ok" 0 "TemporaryUnavailable";
VAL_ 1104 DrvCamDrvIR_D_Stat 3 "Faulty" 2 "Blocked" 1 "Ok" 0 "TemporaryUnavailable";
VAL_ 1104 DrvAttentZone_D_Stat 15 "Faulty" 14 "NotUsed_5" 13 "NotUsed_4" 12 "NotUsed_3" 11 "NotUsed_2" 10 "NotUsed_1" 9 "PassengerSideWindow" 8 "DriverSideWindow" 7 "DriverSideMirror" 6 "RearviewMirror" 5 "PassengerSideMirror" 4 "Infotainment" 3 "Cluster" 2 "FrontWindshield" 1 "Other" 0 "NotDetermined";
VAL_ 1104 DrvAlertSt_D_Stat 3 "Faulty" 2 "EyesOffRoad" 1 "EyesOnRoad" 0 "NotDetermined";
VAL_ 1114 TrailCtlSwtch_B_Stat2 1 "Pressed" 0 "Not_Pressed";
VAL_ 1114 TrlBrkInitOut_D_Rq 3 "Heavy" 2 "Medium" 1 "Light" 0 "Null";
VAL_ 1116 TrlrAidSetup_D2_Rq 15 "NotUsed_9" 14 "NotUsed_8" 13 "NotUsed_7" 12 "NotUsed_6" 11 "NotUsed_5" 10 "NotUsed_4" 9 "NotUsed_3" 8 "NotUsed_2" 7 "NotUsed_1" 6 "CompleteSetup" 5 "ReturnToSetup" 4 "StickerNotCircled" 3 "ConfirmSetup" 2 "EndSetup" 1 "BeginSetup" 0 "Inactive";
VAL_ 1116 TrlrAidEnbl_D2_Rq 7 "NotUsed_4" 6 "NotUsed_3" 5 "NotUsed_2" 4 "NotUsed_1" 3 "Deactivate" 2 "ActivateTrg" 1 "ActivateTba" 0 "Inactive";
VAL_ 1116 TrlrRvrseCancl_B_Rq 1 "Cancel" 0 "Null";
VAL_ 1116 TrlrIdType_D_Stat 3 "Gooseneck" 2 "FifthWheel" 1 "Conventional" 0 "Null";
VAL_ 1116 TrlrAnOffstDir_D_Mem 3 "NotUSed" 2 "Right" 1 "Left_or_Center" 0 "Null";
VAL_ 1085 ULoRgenTestMde_B_Stat 1 "Active" 0 "Inactive";
VAL_ 1085 PwSrcULoOvrTe_B_Actl 1 "Yes" 0 "No";
VAL_ 1085 PwSrcULoFalt_D_Stat 3 "Fault_No_Output" 2 "Fault_Reduced_Output" 1 "Fault_NonSpecific" 0 "No_Fault";
VAL_ 1085 PwSrcULoDcnnt_B_Stat 1 "Loose_or_Disconnected" 0 "Connected";
VAL_ 1085 PwSrcULo_Pc_Mx 255 "Fault";
VAL_ 1085 PwSrcULoComm_B_Falt 1 "Fault" 0 "No_Fault";
VAL_ 1085 PwSrcULo_I_Mx 255 "Fault";
VAL_ 1085 PwSrcULo_I_Actl 255 "Fault";
VAL_ 981 AdbBrdrTop_An_Rq 255 "Faulty" 254 "NoDataExists";
VAL_ 981 AdbBrdrRight_L_Stat 511 "Faulty" 510 "NoDataExists";
VAL_ 981 AdbBrdrRight_An_Rq 1023 "Faulty" 1022 "NoDataExists";
VAL_ 981 AdbBrdrLeft_L_Stat 511 "Faulty" 510 "NoDataExists";
VAL_ 981 AdbBrdrLeft_An_Rq 1023 "Faulty" 1022 "NoDataExists";
VAL_ 981 AdbBrdrBottom_An_Rq 63 "Faulty" 62 "NoDataExists";
VAL_ 981 AdbBeam_D_Rq 7 "NotUsed_3" 6 "NotUsed_2" 5 "NotUsed_1" 4 "FullHighBeam" 3 "Spot_BothSide" 2 "Spot_OnlyRightSide" 1 "Spot_OnlyLeftSide" 0 "NoHighBeam";
VAL_ 791 EngAirFilt_B_RqReset 1 "Yes" 0 "No";
VAL_ 791 GpsElMdeSel_B_Rq 1 "On" 0 "Off";
VAL_ 791 LongTermReset_B_Rq 1 "On" 0 "Off";
VAL_ 791 DrvEffLvl_No_Stat 63 "Fault" 62 "NoDataExists";
VAL_ 868 BattRgenLoStat_D_Qlty 3 "OK" 2 "Not_Within_Spec" 1 "Eval_In_Progress" 0 "Faulty";
VAL_ 868 BattRgenLoPrtct_B_Stat 1 "Yes" 0 "No";
VAL_ 868 BattRgenLoDChrg_D_Stat 3 "StuckClosed" 2 "StuckOpen" 1 "Closed" 0 "Open";
VAL_ 868 BattRgenLoDchrg_B_Rq 1 "Yes" 0 "No";
VAL_ 868 BattRgenLoChrg_D_Stat 3 "StuckClosed" 2 "StuckOpen" 1 "Closed" 0 "Open";
VAL_ 868 BattRgenLoChrg_B_Rq 1 "Yes" 0 "No";
VAL_ 868 BattRgenLo_B_Falt 1 "Yes" 0 "No";
VAL_ 867 BattRgenLoBalnc_B_Rq 1 "Yes" 0 "No";
VAL_ 867 BattRgenLo_Te_Actl 255 "Fault";
VAL_ 865 BattRgenLo_U_Actl 2047 "Faulty";
VAL_ 865 BattRgenLo_I_Actl 65535 "Faulty";
VAL_ 1144 WakeAlarm0_B_Typ 1 "CanAndEcuDriveCircuit" 0 "CanOnly";
VAL_ 1144 PreCondBatt_B_Actl 1 "On" 0 "Off";
VAL_ 1144 HtrnDcdcDis_B_Rq 1 "Yes" 0 "No";
VAL_ 1144 ChrgNowEvnt_B_Stat 1 "Active" 0 "Inactive";
VAL_ 1144 CabinDrvSustn_B_Rq 1 "Active" 0 "Inactive";
VAL_ 1144 BattChrgTrgtSoC_D_Rq 7 "Percent_50" 6 "Percent_60" 5 "Percent_70" 4 "Percent_80" 3 "Percent_85" 2 "Percent_90" 1 "Percent_95" 0 "Percent_100";
VAL_ 1144 CabnEvapSovFront_B_Rq 1 "On" 0 "Off";
VAL_ 1144 HeatCoreSovRear_B_Rq 1 "On" 0 "Off";
VAL_ 1144 BattChlrSov_B_Rq 1 "On" 0 "Off";
VAL_ 1144 CabnEvapSovRear_B_Rq 1 "On" 0 "Off";
VAL_ 1144 BrkAppl_D_RqPt 3 "BrakesSlowRelease" 2 "BrakesFastRelease" 1 "BrakesEngage" 0 "NotActive";
VAL_ 1144 HtrnCnnctPwr_B_Stat 1 "Asserted" 0 "NotAsserted";
VAL_ 1144 PtcHtr_D_Stat 3 "Faulty" 2 "NotUsed" 1 "On" 0 "Off";
VAL_ 1144 HtrnClntFlw_D_Rq 3 "High" 2 "Medium" 1 "Low" 0 "Off";
VAL_ 1144 BattTracDrvSustn_B_Rq 1 "Active" 0 "Inactive";
VAL_ 1144 BattTracClntVlv_B_Rq 1 "On" 0 "Off";
VAL_ 1141 OfbChrgSetSync_D_Stat 3 "Fail" 2 "Success" 1 "InProgress" 0 "NoSyncInProgress";
VAL_ 1141 PtRmtRprt_D_Rq 15 "NotUsed_4" 14 "NotUsed_3" 13 "NotUsed_2" 12 "PlugInToMaintain12vBattery" 11 "SettingUpdated" 10 "FastChargeComplete" 9 "ChargeNotOccurring" 8 "OneTimeSocReached" 7 "BatteryTemperatureReminder" 6 "ReducedPerformance" 5 "LimitedPerformance" 4 "ChargeFault" 3 "ChargeComplete" 2 "VehiclePreconditioned" 1 "TripDistanceAchieved" 0 "NoReportRequest";
VAL_ 1141 NtfctnConflict1_D_Rq 7 "NotUsed5" 6 "NotUsed4" 5 "NotUsed3" 4 "NotUsed2" 3 "NotUsed1" 2 "Clonflict_Exists" 1 "No_Conflict" 0 "Invalid";
VAL_ 1140 RgenEvntLvl_Pc_Dsply 1023 "Fault" 1022 "NoDataExists";
VAL_ 1140 BrkEvntComplt_B_Dsply 1 "On" 0 "Off";
VAL_ 1140 PreCondStat_D_Dsply 7 "Reserved3" 6 "Reserved2" 5 "Reserved1" 4 "Faulted" 3 "Complete" 2 "In_Progress" 1 "Scheduled" 0 "Not_Scheduled";
VAL_ 1139 BattChrgTrgtLMax_T_Est 2047 "Faulty" 2046 "NoDataExists";
VAL_ 1139 ActChrgStrtYr_No_Actl 31 "Invalid";
VAL_ 1139 ActChrgStrtMin_No_Actl 63 "Invalid" 62 "Unknown";
VAL_ 1139 ActChrgStrtHr_No_Actl 31 "Invalid" 30 "Unknown";
VAL_ 1139 ActChrgStrtDay_No_Actl 31 "Invalid";
VAL_ 1139 ActChrgStrMnth_No_Actl 15 "Invalid";
VAL_ 1138 BattChrgTrgtLMin_T_Est 2047 "Faulty" 2046 "NoDataExists";
VAL_ 1138 ActChrgEndYr_No_Actl 31 "Invalid";
VAL_ 1138 ActChrgEndMnth_No_Actl 15 "Invalid";
VAL_ 1138 ActChrgEndMin_No_Actl 63 "Invalid" 62 "Unknown";
VAL_ 1138 ActChrgEndHr_No_Actl 31 "Invalid" 30 "Unknown";
VAL_ 1138 ActChrgEndDay_No_Actl 31 "Invalid";
VAL_ 1089 Mtr2Aout_W_ActlMntr 1023 "Faulty";
VAL_ 1089 Inv1_Te_Actl 255 "Faulty" 254 "NoDataExists";
VAL_ 1089 MtrTrac2Coil_Te_Actl 255 "Faulty" 254 "NoDataExists";
VAL_ 1089 MtrTrac2Falt_B_Stat 1 "Active" 0 "Inactive";
VAL_ 1089 MtrTrac2TeAlrm_B_Stat 1 "Active" 0 "Inactive";
VAL_ 1089 Mtr2CntlTeAlrm_B_Stat 1 "Active" 0 "Inactive";
VAL_ 1089 MtrTrac2Inv_Te_Actl 255 "Faulty" 254 "NoDataExists";
VAL_ 1089 MtrTrac2_I_Actl 65535 "Faulty";
VAL_ 1088 ChrgTMatch_B_Stat 1 "True" 0 "False";
VAL_ 1088 ChrgStat_D2_Dsply 15 "NotUsed_2" 14 "NotUsed_1" 13 "ChargeTargetReached" 12 "DriveConditioning" 11 "CabinPreconditioning" 10 "ChargingSystemMaintain" 9 "ChargingInductive" 8 "ChargingDCFastChange" 7 "ChargingAC" 6 "ChargeScheduled" 5 "EvsePaused" 4 "EvseNotDetected" 3 "EvseNotCompatible" 2 "FaultOutsideCar" 1 "FaultInsideCar" 0 "NotReady";
VAL_ 1088 HvacPrecondRecirc_D_Rq 3 "Last_User_Setting" 2 "Auto" 1 "Recirc" 0 "Outside";
VAL_ 1088 HvacPrecondMode2_D_Rq 15 "NotUsed4" 14 "NotUsed3" 13 "NotUsed2" 12 "NotUsed1" 11 "Last_User_Settings" 10 "Auto" 9 "Max_Defrost" 8 "Windshield_Panel_Floor" 7 "Windshield_Panel" 6 "Windshield" 5 "Windshield_Floor" 4 "Floor" 3 "Panel_Floor" 2 "Panel" 1 "MAX_AC" 0 "Off";
VAL_ 1088 HvacPrecondBlwr2_D_Rq 15 "NotUsed6" 14 "NotUsed5" 13 "NotUsed4" 12 "NotUsed3" 11 "NotUsed2" 10 "NotUsed1" 9 "Last_User_Setting" 8 "Auto" 7 "Speed7" 6 "Speed6" 5 "Speed5" 4 "Speed4" 3 "Speed3" 2 "Speed2" 1 "Speed1" 0 "Off";
VAL_ 1088 HvacPrecondAC_D_Rq 3 "Last_User_Setting" 2 "Auto" 1 "On" 0 "Off";
VAL_ 1088 BattChrgInhbt_D_Rq 3 "MaintainTargetSoc" 2 "NotUsed" 1 "InhibitChargingThermal" 0 "Enable_Charging";
VAL_ 1040 ElCmprEnbl_B_Rq 1 "Enable" 0 "Disable";
VAL_ 1016 ChrgGoTElement_B_Dsply 1 "Yes" 0 "No";
VAL_ 1016 ChrgGoTTouchEnbl_B_Rq 1 "Request" 0 "NoRequest";
VAL_ 1016 ChrgGoTTouch_B_Stat 1 "On" 0 "Off";
VAL_ 1016 ChrgGoTPrcond_D_Stat 3 "High" 2 "Medium" 1 "Low" 0 "Off";
VAL_ 1016 ChrgGoTMnte_D_Stat 15 "NotUsed_4" 14 "NotUsed_3" 13 "NotUsed_2" 12 "NotUsed_1" 11 "Minute_55" 10 "Minute_50" 9 "Minute_45" 8 "Minute_40" 7 "Minute_35" 6 "Minute_30" 5 "Minute_25" 4 "Minute_20" 3 "Minute_15" 2 "Minute_10" 1 "Minute_5" 0 "Minute_0";
VAL_ 1016 ChrgGoTHr_T_Stat 31 "Faulty" 30 "NoDataExists";
VAL_ 1016 ChrgGoTExtHtrEnbl_B_Rq 1 "Request" 0 "NoRequest";
VAL_ 1016 ChrgGoTExtHtr_B_Stat 1 "On" 0 "Off";
VAL_ 1016 ChrgGoTAllOn_B_Stat 1 "On" 0 "Off";
VAL_ 1013 ChrgToPcWkndSav_D_Stat 7 "Percent_50" 6 "Percent_60" 5 "Percent_70" 4 "Percent_80" 3 "Percent_85" 2 "Percent_90" 1 "Percent_95" 0 "Percent_100";
VAL_ 1013 ChrgToPcWkdySav_D_Stat 7 "Percent_50" 6 "Percent_60" 5 "Percent_70" 4 "Percent_80" 3 "Percent_85" 2 "Percent_90" 1 "Percent_95" 0 "Percent_100";
VAL_ 1013 ChrgNowEnbl_B_Saved 1 "On" 0 "Off";
VAL_ 1013 ChrgLocIdUnsAck_B_Stat 1 "Yes" 0 "No";
VAL_ 1012 ChrgNowCurnt_B_Dsply 1 "On" 0 "Off";
VAL_ 1012 ChrgLocSaved_B_Dsply 1 "Yes" 0 "No";
VAL_ 1012 ChrgLocLongPostv_B_Sav 1 "Yes" 0 "No";
VAL_ 1012 ChrgLocLattPostv_B_Sav 1 "Yes" 0 "No";
VAL_ 1011 ChrgLocLongPostv_B_Uns 1 "Yes" 0 "No";
VAL_ 1011 ChrgLocLattPostv_B_Uns 1 "Yes" 0 "No";
VAL_ 871 BattElecPerf_D_Actl 7 "NotUsed" 6 "Hot_Batt_Severe_Lim_Perf" 5 "Hot_Batt_Reduced_Perf" 4 "Hot_Batt_Close_to_lim_Per" 3 "Cold_Batt_Severe_Lim_Perf" 2 "Cold_Batt_Reduced_Perf" 1 "Cold_Batt_Close_to_lim_Pe" 0 "Ok_no_message_displayed";
VAL_ 871 BattChrgTrgtLPt_T_Est 2047 "Faulty" 2046 "NoDataExists";
VAL_ 871 BattChrgTrgSocPt_T_Est 2047 "Faulty" 2046 "NoDataExists";
VAL_ 871 BattChrgCmpltPt_T_Est 2047 "Faulty" 2046 "NoDataExists";
VAL_ 786 RgenTrip_L_Dsply 65535 "Fault" 65534 "NoDataExists";
VAL_ 786 ChrgStat_D_Dsply 7 "NotUsed" 6 "Complete" 5 "Scheduled" 4 "In_Progress" 3 "Fault_Outside_Car" 2 "Fault_Inside_Car" 1 "Fault_Unknown_Location" 0 "Not_Ready";
VAL_ 72 immoTarget2Status 7 "Unused4" 6 "Unused3" 5 "Unused2" 4 "Unused1" 3 "DISABLED_RESET   " 2 "ENABLED_NONMOTIVE_START" 1 "ENABLED_MOTIVE_START" 0 "DISABLED";
VAL_ 72 immoTarget2Cmd 7 "Unused4" 6 "Unused3" 5 "Unused2" 4 "Unused1" 3 "TARGET1_IDBLOCK2" 2 "TARGET1_IDBLOCK1" 1 "CHALLENGE" 0 "IDLE";
VAL_ 912 CabnEvapSovFront_D_Stat 7 "NotUsed_1" 6 "FetLifeLimitReached" 5 "FetOpenCircuit" 4 "FetOutputShortToPower" 3 "FetOutputShortToGround" 2 "FetNotControlled" 1 "OnPowerToLoad" 0 "OffNoPowerToLoad";
VAL_ 912 BattChlrSov_D_Stat 7 "NotUsed_1" 6 "FetLifeLimitReached" 5 "FetOpenCircuit" 4 "FetOutputShortToPower" 3 "FetOutputShortToGround" 2 "FetNotControlled" 1 "OnPowerToLoad" 0 "OffNoPowerToLoad";
VAL_ 912 BattTracClntVlv_D_Stat 7 "NotUsed" 6 "FetLifeLimitReached" 5 "FetOpenCircuit" 4 "FetOutputShortToPower" 3 "FetOutputShortToGround" 2 "FetNotControlled" 1 "OnPowerToLoad" 0 "OffNoPowerToLoad";
VAL_ 874 AirCondCluOpen_D_Falt 3 "NotUsed" 2 "Pass" 1 "Fail" 0 "Not_Diagnose_Yet";
VAL_ 874 AirCondCluLife_D_Falt 3 "NotUsed" 2 "Pass" 1 "Fail" 0 "Not_Diagnose_Yet";
VAL_ 874 AirCondCluGnd_D_Falt 3 "NotUsed" 2 "Pass" 1 "Fail" 0 "Not_Diagnose_Yet";
VAL_ 874 AirCondClu_D_Stat 7 "NotUsed" 6 "FetLifeLimitReached" 5 "FetOpenCircuit" 4 "FetOutputShortToPower" 3 "FetOutputShortToGround" 2 "FetNotControlled" 1 "OnPowerToLoad" 0 "OffNoPowerToLoad";
VAL_ 874 AirCondCluBatt_D_Falt 3 "NotUsed" 2 "Pass" 1 "Fail" 0 "Not_Diagnose_Yet";
VAL_ 874 BattTracShrtGrnd_D_Falt 3 "NotUsed" 2 "Pass" 1 "Fail" 0 "Not_Diagnose_Yet";
VAL_ 874 BattTracShrtBatt_D_Falt 3 "NotUsed" 2 "Pass" 1 "Fail" 0 "Not_Diagnose_Yet";
VAL_ 874 BattTracOpnCirct_D_Falt 3 "NotUsed" 2 "Pass" 1 "Fail" 0 "Not_Diagnose_Yet";
VAL_ 874 BattTracLifeLim_D_Falt 3 "NotUsed" 2 "Pass" 1 "Fail" 0 "Not_Diagnose_Yet";
VAL_ 874 BattChlrShrtGrnd_D_Falt 3 "NotUsed" 2 "Pass" 1 "Fail" 0 "Not_Diagnose_Yet";
VAL_ 874 BattChlrShrtBatt_D_Falt 3 "NotUsed" 2 "Pass" 1 "Fail" 0 "Not_Diagnose_Yet";
VAL_ 874 BattChlrOpnCirct_D_Falt 3 "NotUsed" 2 "Pass" 1 "Fail" 0 "Not_Diagnose_Yet";
VAL_ 874 BattChlrLifeLim_D_Falt 3 "NotUsed" 2 "Pass" 1 "Fail" 0 "Not_Diagnose_Yet";
VAL_ 874 BattTracLow_D_Falt 3 "NotUsed" 2 "Pass" 1 "Fail" 0 "Not_Diagnose_Yet";
VAL_ 651 TelematicsSrvc_D_St 7 "NotUsed" 6 "NotifyNotActivatedYet" 5 "NotActivatedYet" 4 "NotifyExpired" 3 "Expired" 2 "ExpiringSoon" 1 "Active" 0 "Null";
VAL_ 651 EmgcyCallMute_D_Stat 7 "NotUsed4" 6 "NotUsed3" 5 "NotUsed2" 4 "NotUsed1" 3 "ManualEmergencyCallMute" 2 "AutomaticEmergencyCallMute" 1 "EmergencyCallUnmute" 0 "Null";
VAL_ 651 OfbChrgSetSync_D_Rq 3 "Fail" 2 "Success" 1 "InProgress" 0 "NoSyncInProgress";
VAL_ 529 OnbChrgToPcWknd_D_Actl 7 "Percent_50" 6 "Percent_60" 5 "Percent_70" 4 "Percent_80" 3 "Percent_85" 2 "Percent_90" 1 "Percent_95" 0 "Percent_100";
VAL_ 529 OnbChrgToPcWkdy_D_Actl 7 "Percent_50" 6 "Percent_60" 5 "Percent_70" 4 "Percent_80" 3 "Percent_85" 2 "Percent_90" 1 "Percent_95" 0 "Percent_100";
VAL_ 529 OnbChrgSetNow_D_Rq 3 "NotUsed" 2 "On" 1 "Off" 0 "Null";
VAL_ 529 OnbChrgSetDelete_B_Rq 1 "Request" 0 "NoRequest";
VAL_ 529 OnbChrgPrflUpdate_B_Rq 1 "Request" 0 "NoRequest";
VAL_ 529 OnbChrgLocIdUns_B_Rq 1 "Request" 0 "NoRequest";
VAL_ 66 immoControlCmd_T2 0 "IDLE" 1 "MOTIVE_START_RQST" 2 "NONMOTIVE_START_RQST" 3 "RQST_TARGET2_IDBLOCK1" 4 "RQST_TARGET2_IDBLOCK2" 5 "Unused" 6 "ECHO_TARGET2_IDBLOCK2" 7 "SHUTDOWN";
VAL_ 1124 GPS_Vdop 31 "Invalid" 30 "Unknown";
VAL_ 1124 GPS_Speed 255 "Invalid" 254 "Unknown";
VAL_ 1124 GPS_Sat_num_in_view 31 "Invalid" 30 "Unknown";
VAL_ 1124 GPS_MSL_altitude 4095 "Fault" 4094 "Unknown";
VAL_ 1124 GPS_Heading 65535 "Fault" 65534 "Unknown";
VAL_ 1124 GPS_Hdop 31 "Invalid" 30 "Unknown";
VAL_ 1124 GPS_dimension 2 "_3D" 1 "_2D" 0 "No_Fix";
VAL_ 1119 CoolFanDcdc_D_Rq 3 "High" 2 "Medium" 1 "Low" 0 "Off";
VAL_ 1119 DcdcClntFlw_D_Rq 3 "High" 2 "Medium" 1 "Low" 0 "Off";
VAL_ 1123 GpsUtcYr_No_Actl 31 "Fault";
VAL_ 1123 GpsUtcMnth_No_Actl 15 "Fault";
VAL_ 1123 GPS_UTC_seconds 63 "Fault" 62 "Unknown";
VAL_ 1123 GPS_UTC_minutes 63 "Fault" 62 "Unknown";
VAL_ 1123 GPS_UTC_hours 31 "Invalid" 30 "Unknown";
VAL_ 1123 GPS_Pdop 31 "Invalid" 30 "Unknown";
VAL_ 1123 GPS_Compass_direction 7 "NorthWest" 6 "West" 5 "SouthWest" 4 "South" 3 "SouthEast" 2 "East" 1 "NorthEast" 0 "North";
VAL_ 1123 GPS_Actual_vs_Infer_pos 1 "Inferred_Position" 0 "Actual_Postition";
VAL_ 1123 Gps_B_Falt 1 "Yes" 0 "No";
VAL_ 1122 GpsHsphLongEast_D_Actl 0 "Invalid" 1 "Eastern" 2 "Western" 3 "Fault";
VAL_ 1122 GpsHsphLattSth_D_Actl 3 "Fault" 2 "Northern" 1 "Southern" 0 "Invalid";
VAL_ 1122 GPS_Longitude_Minutes 63 "Fault" 62 "Unknown";
VAL_ 1122 GPS_Longitude_Min_dec 16383 "Invalid" 16382 "Unknown";
VAL_ 1122 GPS_Longitude_Degrees 511 "Fault" 510 "Unknown";
VAL_ 1122 GPS_Latitude_Minutes 63 "Fault" 62 "Unknown";
VAL_ 1122 GPS_Latitude_Min_dec 16383 "Invalid" 16382 "Unknown";
VAL_ 1122 GPS_Latitude_Degrees 255 "Invalid" 254 "Unknown";
VAL_ 1003 PersRecallSrc_D_Actl 7 "NotUsed_3" 6 "NotUsed_2" 5 "NotUsed_1" 4 "MemorySwitch" 3 "RemoteStart" 2 "KeyFob" 1 "CenterStack" 0 "Null";
VAL_ 1003 Pers4Key_D_Stat 3 "NotUsed_1" 2 "KeyUnAssociated" 1 "KeyAssociated" 0 "Null";
VAL_ 1003 Pers3Key_D_Stat 3 "NotUsed_1" 2 "KeyUnAssociated" 1 "KeyAssociated" 0 "Null";
VAL_ 1003 Pers2Key_D_Stat 3 "NotUsed_1" 2 "KeyUnAssociated" 1 "KeyAssociated" 0 "Null";
VAL_ 1003 Pers1Key_D_Stat 3 "NotUsed_1" 2 "KeyUnAssociated" 1 "KeyAssociated" 0 "Null";
VAL_ 1003 EmPrflNo_D_Stat 7 "NotUsed_3" 6 "NotUsed_2" 5 "NotUsed_1" 4 "Pers4" 3 "Pers3" 2 "Pers2" 1 "Pers1" 0 "Null";
VAL_ 1003 EmPrflKeyAssoc_D_Stat 7 "WrongDevice" 6 "KeyAssociateFailed" 5 "KeyAssociateSuccess" 4 "KeyAlreadyInUse" 3 "KeyDisassociated" 2 "KeyAssociationExited" 1 "KeyAssociationEntered" 0 "Null";
VAL_ 1003 VehKeyActv_D_Stat 15 "NotUsed7" 14 "NotUsed6" 13 "NotUsed5" 12 "NotUsed4" 11 "NotUsed3" 10 "NotUsed2" 9 "NotUsed1" 8 "Key8Active" 7 "Key7Active" 6 "Key6Active" 5 "Key5Active" 4 "Key4Active" 3 "Key3Active" 2 "Key2Active" 1 "Key1Active" 0 "NoKeyActive";
VAL_ 1003 PersNoPos_D_Actl 7 "Unused_3" 6 "Unused_2" 5 "Unused_1" 4 "Vehicle" 3 "PERS_4" 2 "PERS_3" 1 "PERS_2" 0 "PERS_1";
VAL_ 1003 PersSetupRestr_D_Actl 3 "Non_Moveable_Person" 2 "Moveable_Person" 1 "Vehicle" 0 "Factory";
VAL_ 1003 PersSetupAccessCtrl 1 "Limited" 0 "Full";
VAL_ 1003 PersConflict_D_Actl 1 "Conflict" 0 "No_Conflict";
VAL_ 1003 AssocConfirm_D_Actl 0 "None" 7 "Associate" 6 "Keycode_Rejected" 5 "Keycode_Accepted" 4 "In_Progress" 3 "Erase" 2 "Duplicate" 1 "Disassociate";
VAL_ 1003 PersNo_D_Actl 7 "Unused_3" 6 "Unused_2" 5 "NotDetermined" 4 "Vehicle" 3 "PERS_4" 2 "PERS_3" 1 "PERS_2" 0 "PERS_1";
VAL_ 1056 AutoEpbMsgTxt_D_Rq 7 "Message7" 6 "Message6" 5 "Message5" 4 "Message4" 3 "Message3" 2 "Message2" 1 "Message1" 0 "NoMessage";
VAL_ 1056 AutoEpbDsply_D_Stat 1 "Available" 0 "NotAvailable";
VAL_ 1056 AutoEpbButtnOn_B_Stat 1 "On" 0 "Off";
VAL_ 1056 SelDrvMdePos12_B_Avail 1 "Available" 0 "NotAvailable";
VAL_ 1056 SelDrvMdePos11_B_Avail 1 "Available" 0 "NotAvailable";
VAL_ 1056 SelDrvMdePos10_B_Avail 1 "Available" 0 "NotAvailable";
VAL_ 1056 SelDrvMdePos09_B_Avail 1 "Available" 0 "NotAvailable";
VAL_ 1056 SelDrvMdePos08_B_Avail 1 "Available" 0 "NotAvailable";
VAL_ 1056 SelDrvMdePos07_B_Avail 1 "Available" 0 "NotAvailable";
VAL_ 1056 SelDrvMdePos06_B_Avail 1 "Available" 0 "NotAvailable";
VAL_ 1056 SelDrvMdePos05_B_Avail 1 "Available" 0 "NotAvailable";
VAL_ 1056 SelDrvMdePos04_B_Avail 1 "Available" 0 "NotAvailable";
VAL_ 1056 SelDrvMdePos03_B_Avail 1 "Available" 0 "NotAvailable";
VAL_ 1056 SelDrvMdePos02_B_Avail 1 "Available" 0 "NotAvailable";
VAL_ 1056 SelDrvMdePos01_B_Avail 1 "Available" 0 "NotAvailable";
VAL_ 1056 ActvDrvMde_D2_Stat 31 "Faulty" 30 "SelDrvMde31" 29 "SelDrvMde30" 28 "SelDrvMde29" 27 "SelDrvMde28" 26 "SelDrvMde27" 25 "SelDrvMde26" 24 "SelDrvMde25" 23 "SelDrvMde24" 22 "SelDrvMde23" 21 "SelDrvMde22" 20 "SelDrvMde21" 19 "SelDrvMde20" 18 "SelDrvMde19" 17 "SelDrvMde18" 16 "SelDrvMde17" 15 "SelDrvMde16" 14 "SelDrvMde15" 13 "SelDrvMde14" 12 "SelDrvMde13" 11 "SelDrvMde12" 10 "SelDrvMde11" 9 "SelDrvMde10" 8 "SelDrvMde09" 7 "SelDrvMde08" 6 "SelDrvMde07" 5 "SelDrvMde06" 4 "SelDrvMde05" 3 "SelDrvMde04" 2 "SelDrvMde03" 1 "SelDrvMde02" 0 "SelDrvMde01";
VAL_ 1056 SelDrvMde_D2_Rq 31 "Faulty" 30 "SelDrvMde31" 29 "SelDrvMde30" 28 "SelDrvMde29" 27 "SelDrvMde28" 26 "SelDrvMde27" 25 "SelDrvMde26" 24 "SelDrvMde25" 23 "SelDrvMde24" 22 "SelDrvMde23" 21 "SelDrvMde22" 20 "SelDrvMde21" 19 "SelDrvMde20" 18 "SelDrvMde19" 17 "SelDrvMde18" 16 "SelDrvMde17" 15 "SelDrvMde16" 14 "SelDrvMde15" 13 "SelDrvMde14" 12 "SelDrvMde13" 11 "SelDrvMde12" 10 "SelDrvMde11" 9 "SelDrvMde10" 8 "SelDrvMde09" 7 "SelDrvMde08" 6 "SelDrvMde07" 5 "SelDrvMde06" 4 "SelDrvMde05" 3 "SelDrvMde04" 2 "SelDrvMde03" 1 "SelDrvMde02" 0 "SelDrvMde01";
VAL_ 1056 SelDrvMdePt_D_Rq 31 "Faulty" 30 "NotUsed15" 29 "NotUsed14" 28 "NotUsed13" 27 "NotUsed12" 26 "NotUsed11" 25 "NotUsed10" 24 "NotUsed9" 23 "NotUsed8" 22 "NotUsed7" 21 "NotUsed6" 20 "NotUsed5" 19 "NotUsed4" 18 "EvLaterChargerMode" 17 "EvNowMode" 16 "DragMode" 15 "HighSpeedDesertMode_Baja" 14 "SportAdaptiveMode" 13 "NotAvailable_13" 12 "NotAvailable_12" 11 "NotAvailable_11" 10 "NotAvailable_10" 9 "RockCrawlMode" 8 "MudRutsMode" 7 "SandMode" 6 "EconomyMode" 5 "GrassGravelSnow" 4 "NotAvailable_04" 3 "TowHaulMode" 2 "NotAvailable_02" 1 "SportMode" 0 "NormalMode";
VAL_ 1056 SelDrvMdeMsgTxt_D_Rq 15 "Message15" 14 "Message14" 13 "Message13" 12 "Message12" 11 "Message11" 10 "Message10" 9 "Message9" 8 "Message8" 7 "Message7" 6 "Message6" 5 "Message5" 4 "Message4" 3 "Message3" 2 "Message2" 1 "Message1" 0 "NoMessage";
VAL_ 1056 SelDrvMde_D_Stat 3 "NotUsed" 2 "DriveModeChangeRequest" 1 "DriveModeChangeSelection" 0 "NoDriveModeChangeRequest";
VAL_ 1056 AwdMde_D_RqBrk 7 "Faulty" 6 "NotUsed2" 5 "NoRequest" 4 "Neutral" 3 "FourByFourLow" 2 "FourByFourHigh" 1 "FourByFourAuto" 0 "FourByTwo";
VAL_ 870 EngMdeMsgTxt_D_Rq 7 "NotUsed_3" 6 "NotUsed_2" 5 "NotUsed_1" 4 "Charge" 3 "GlowingCharge" 2 "Hybrid" 1 "Ev" 0 "NoMessage";
VAL_ 870 RngPerChrgInst_L_Dsply 4095 "Faulty" 4094 "NoDataExists";
VAL_ 1152 BattTracDiagClr_B_Stat 1 "On" 0 "Off";
VAL_ 1152 EngTeHi_B_Actl 1 "EngineTempHigh" 0 "Normal";
VAL_ 1152 DcdcOn_B_Rq 1 "On" 0 "Off";
VAL_ 1152 ULoBattSpprtSustn_B_Rq 1 "Active" 0 "Inactive";
VAL_ 1152 VehElEff_No_Avg 127 "Faulty" 126 "NoDataExists";
VAL_ 872 PlgActvArb_B_Dsply 1 "On" 0 "Off";
VAL_ 872 HybMdeStat_D_Dsply 7 "NotUsed2" 6 "EV_Charge" 5 "EV_Override" 4 "Forced_EV_Mode" 3 "Forced_Charge_Sustain_Mode" 2 "Auto_Charge_Sustain_Mode" 1 "Auto_Charge_Deplete_Mode" 0 "Null_State";
VAL_ 976 SuspClkSync_No_Actl 255 "Faulty" 254 "NoDataExists";
VAL_ 976 SrpSigValid_B_Stat 1 "True" 0 "False";
VAL_ 976 SrpHghtRight_L_Actl 511 "Faulty" 510 "NoDataExists";
VAL_ 976 SrpHghtLeft_L_Actl 511 "Faulty" 510 "NoDataExists";
VAL_ 976 SrpEventRight_D_Stat 3 "Faulty" 2 "Bump" 1 "Pothole" 0 "NoEvent";
VAL_ 976 SrpEventLeft_D_Stat 3 "Faulty" 2 "Bump" 1 "Pothole" 0 "NoEvent";
VAL_ 976 SrpDistRight_L_Actl 511 "Faulty" 510 "NoDataExists";
VAL_ 976 SrpDistLeft_L_Actl 511 "Faulty" 510 "NoDataExists";
